VERSION ""

NS_ :

BS_:

BU_: ACM APIM APIM_CDC APIM_CIM APIM_CISM ARM DSP ESPM FCIMB GENERIC GWM HUD_ADV IPC MRCMB_RDAPM_HS3 RACM_RCIM TRM_ITRM TSTR WCM WCMB WCMC

BO_ 1152 HEV_Powertrain_Data6_HS3: 8 GWM
 SG_ StopStrtVThres_D_Stat : 1|2@0+ (1,0) [0|3] "SED"  APIM,APIM_CDC,APIM_CIM,IPC
 SG_ BattTracDiagClr_B_Stat : 2|1@0+ (1,0) [0|1] "SED" Vector__XXX
 SG_ OnePdlDrv_D_Dsply : 4|2@0+ (1,0) [0|3] "SED"  APIM,APIM_CDC,APIM_CIM,APIM_CISM,IPC
 SG_ EngTeHi_B_Actl : 5|1@0+ (1,0) [0|1] "SED" Vector__XXX
 SG_ DcdcOn_B_Rq : 6|1@0+ (1,0) [0|1] "SED" Vector__XXX
 SG_ ULoBattSpprtSustn_B_Rq : 7|1@0+ (1,0) [0|1] "SED" Vector__XXX
 SG_ GrdAsstActv_B_Stat : 8|1@0+ (1,0) [0|1] "SED"  APIM_CDC,APIM_CIM,IPC
 SG_ VehElEff_No_Avg : 15|7@0+ (10,-100) [-100|1170] "watt*hr/km" Vector__XXX
 SG_ PwOutlet8EnblScnd_B_Rq : 16|1@0+ (1,0) [0|1] "SED" Vector__XXX
 SG_ PwOutlet8Enbl_B_Rq : 17|1@0+ (1,0) [0|1] "SED" Vector__XXX
 SG_ PwOutlet7EnblScnd_B_Rq : 18|1@0+ (1,0) [0|1] "SED" Vector__XXX
 SG_ PwOutlet7Enbl_B_Rq : 19|1@0+ (1,0) [0|1] "SED" Vector__XXX
 SG_ PwOutlet6EnblScnd_B_Rq : 20|1@0+ (1,0) [0|1] "SED" Vector__XXX
 SG_ PwOutlet6Enbl_B_Rq : 21|1@0+ (1,0) [0|1] "SED" Vector__XXX
 SG_ HybPwULoLamp_B_Rq : 22|1@0+ (1,0) [0|1] "SED" Vector__XXX
 SG_ OnePdlDrvLamp_B_Rq : 23|1@0+ (1,0) [0|1] "SED"  APIM_CDC,APIM_CIM,IPC
 SG_ DcacPwSustn_B_RqPt : 24|1@0+ (1,0) [0|1] "SED" Vector__XXX
 SG_ OnePdlDrvButtn_D_Dsply : 26|2@0+ (1,0) [0|3] "SED"  APIM,APIM_CDC,APIM_CIM
 SG_ DcdcOnScnd_B_Rq : 27|1@0+ (1,0) [0|1] "SED" Vector__XXX
 SG_ PwCabinEnblScnd_B_Rq : 28|1@0+ (1,0) [0|1] "SED" Vector__XXX
 SG_ PwCabinEnbl_B_Rq : 29|1@0+ (1,0) [0|1] "SED" Vector__XXX
 SG_ PwTrnkFrntEnblScnd_B_Rq : 30|1@0+ (1,0) [0|1] "SED" Vector__XXX
 SG_ PwTrnkFrntEnbl_B_Rq : 31|1@0+ (1,0) [0|1] "SED" Vector__XXX
 SG_ DcacLoFuelLim_L_PwRsrv : 39|9@0+ (1,0) [0|511] "kilometer"  APIM,APIM_CDC,APIM_CIM

BO_ 1153 All_Terrain_Data_HS3: 8 GWM
 SG_ TerrMde_D_RqDrv : 3|3@0+ (1,0) [0|7] "SED"  APIM_CDC,APIM_CIM
 SG_ TerrStat_D_RqDsply : 7|4@0+ (1,0) [0|15] "SED"  APIM_CDC,APIM_CIM,GENERIC

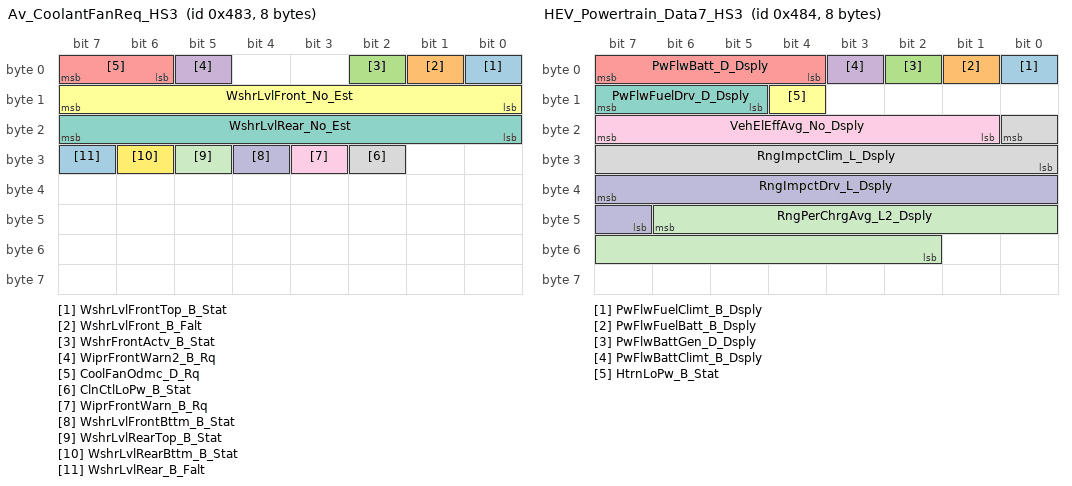
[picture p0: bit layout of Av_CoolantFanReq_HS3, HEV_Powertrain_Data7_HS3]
BO_ 1155 Av_CoolantFanReq_HS3: 8 GWM
 SG_ WshrLvlFrontTop_B_Stat : 0|1@0+ (1,0) [0|1] "SED" Vector__XXX
 SG_ WshrLvlFront_B_Falt : 1|1@0+ (1,0) [0|1] "SED" Vector__XXX
 SG_ WshrFrontActv_B_Stat : 2|1@0+ (1,0) [0|1] "SED"  APIM_CDC
 SG_ WiprFrontWarn2_B_Rq : 5|1@0+ (1,0) [0|1] "SED"  APIM_CDC
 SG_ CoolFanOdmc_D_Rq : 7|2@0+ (1,0) [0|3] "SED" Vector__XXX
 SG_ WshrLvlFront_No_Est : 15|8@0+ (1,0) [0|255] "unitless" Vector__XXX
 SG_ WshrLvlRear_No_Est : 23|8@0+ (1,0) [0|255] "unitless" Vector__XXX
 SG_ ClnCtlLoPw_B_Stat : 26|1@0+ (1,0) [0|1] "SED" Vector__XXX
 SG_ WiprFrontWarn_B_Rq : 27|1@0+ (1,0) [0|1] "SED"  APIM_CDC
 SG_ WshrLvlFrontBttm_B_Stat : 28|1@0+ (1,0) [0|1] "SED" Vector__XXX
 SG_ WshrLvlRearTop_B_Stat : 29|1@0+ (1,0) [0|1] "SED" Vector__XXX
 SG_ WshrLvlRearBttm_B_Stat : 30|1@0+ (1,0) [0|1] "SED" Vector__XXX
 SG_ WshrLvlRear_B_Falt : 31|1@0+ (1,0) [0|1] "SED" Vector__XXX

BO_ 1156 HEV_Powertrain_Data7_HS3: 8 GWM
 SG_ PwFlwFuelClimt_B_Dsply : 0|1@0+ (1,0) [0|1] "SED"  APIM,APIM_CDC,APIM_CIM,APIM_CISM
 SG_ PwFlwFuelBatt_B_Dsply : 1|1@0+ (1,0) [0|1] "SED"  APIM,APIM_CDC,APIM_CIM,APIM_CISM
 SG_ PwFlwBattGen_D_Dsply : 2|1@0+ (1,0) [0|1] "SED"  APIM,APIM_CDC,APIM_CIM,APIM_CISM
 SG_ PwFlwBattClimt_B_Dsply : 3|1@0+ (1,0) [0|1] "SED"  APIM,APIM_CDC,APIM_CIM,APIM_CISM
 SG_ PwFlwBatt_D_Dsply : 7|4@0+ (1,0) [0|15] "SED"  APIM,APIM_CDC,APIM_CIM,APIM_CISM
 SG_ HtrnLoPw_B_Stat : 12|1@0+ (1,0) [0|1] "SED" Vector__XXX
 SG_ PwFlwFuelDrv_D_Dsply : 15|3@0+ (1,0) [0|7] "SED"  APIM,APIM_CDC,APIM_CIM,APIM_CISM
 SG_ RngImpctClim_L_Dsply : 16|9@0+ (1,-255) [-255|256] "km"  APIM_CDC,APIM_CIM,IPC
 SG_ VehElEffAvg_No_Dsply : 23|7@0+ (10,-100) [-100|1170] "wattHr/km"  APIM,APIM_CDC,APIM_CIM,APIM_CISM,IPC
 SG_ RngImpctDrv_L_Dsply : 39|9@0+ (1,-255) [-255|256] "km"  APIM_CDC,APIM_CIM,IPC
 SG_ RngPerChrgAvg_L2_Dsply : 46|13@0+ (0.1,0) [0|819.1] "km"  APIM,APIM_CDC,APIM_CIM,APIM_CISM,IPC

BO_ 1157 BTT5GLH_Data1_HS3: 8 GWM
 SG_ SodAltLeft_D2_StatAft : 7|2@0+ (1,0) [0|3] "SED"  APIM,APIM_CDC,APIM_CIM,APIM_CISM

BO_ 1158 BTT5GRH_Data1_HS3: 8 GWM
 SG_ SodAltRight_D2_StatAft : 7|2@0+ (1,0) [0|3] "SED"  APIM,APIM_CDC,APIM_CIM,APIM_CISM

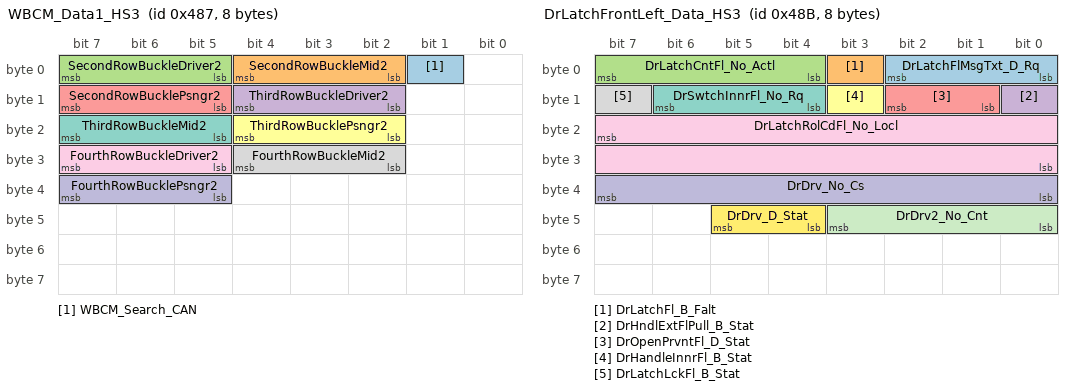
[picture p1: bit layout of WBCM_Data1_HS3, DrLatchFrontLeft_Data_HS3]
BO_ 1159 WBCM_Data1_HS3: 8 GWM
 SG_ WBCM_Search_CAN : 1|1@0+ (1,0) [0|1] "SED" Vector__XXX
 SG_ SecondRowBuckleMid2 : 4|3@0+ (1,0) [0|7] "SED"  APIM_CDC,APIM_CIM,IPC
 SG_ SecondRowBuckleDriver2 : 7|3@0+ (1,0) [0|7] "SED"  APIM_CDC,APIM_CIM,IPC
 SG_ ThirdRowBuckleDriver2 : 12|3@0+ (1,0) [0|7] "SED"  APIM_CDC,APIM_CIM,IPC
 SG_ SecondRowBucklePsngr2 : 15|3@0+ (1,0) [0|7] "SED"  APIM_CDC,APIM_CIM,IPC
 SG_ ThirdRowBucklePsngr2 : 20|3@0+ (1,0) [0|7] "SED"  APIM_CDC,APIM_CIM,IPC
 SG_ ThirdRowBuckleMid2 : 23|3@0+ (1,0) [0|7] "SED"  APIM_CDC,APIM_CIM,IPC
 SG_ FourthRowBuckleMid2 : 28|3@0+ (1,0) [0|7] "SED"  APIM_CDC,APIM_CIM,IPC
 SG_ FourthRowBuckleDriver2 : 31|3@0+ (1,0) [0|7] "SED"  APIM_CDC,APIM_CIM,IPC
 SG_ FourthRowBucklePsngr2 : 39|3@0+ (1,0) [0|7] "SED"  APIM_CDC,APIM_CIM,IPC

BO_ 1161 HEV_Data_Monitor_22_HS3: 8 GWM
 SG_ BattTracCellCnt_No_Actl : 7|8@0+ (1,0) [0|255] "unitless" Vector__XXX
 SG_ BattTracCellUMn_No_Actl : 15|8@0+ (1,0) [0|255] "unitless" Vector__XXX
 SG_ BattTracTeCnt_No_Actl : 23|8@0+ (1,0) [0|255] "unitless" Vector__XXX
 SG_ BattTracTeMn_No_Actl : 31|8@0+ (1,0) [0|255] "unitless" Vector__XXX
 SG_ BattTracTeMx_No_Actl : 39|8@0+ (1,0) [0|255] "unitless" Vector__XXX
 SG_ BattTracTeMx_B_Falt : 40|1@0+ (1,0) [0|1] "SED" Vector__XXX
 SG_ BattTracTeDelta_B_Falt : 41|1@0+ (1,0) [0|1] "SED" Vector__XXX
 SG_ BattTracSoftware_B_Falt : 42|1@0+ (1,0) [0|1] "SED" Vector__XXX
 SG_ BattTracCellDiff_B_Falt : 43|1@0+ (1,0) [0|1] "SED" Vector__XXX
 SG_ BattChrgSocMx_B_Falt : 44|1@0+ (1,0) [0|1] "SED"  APIM,APIM_CDC,APIM_CIM,APIM_CISM
 SG_ BattChrgSocMn_B_Falt : 45|1@0+ (1,0) [0|1] "SED"  APIM,APIM_CDC,APIM_CIM,APIM_CISM
 SG_ BattChrgSocErrtc_B_Falt : 46|1@0+ (1,0) [0|1] "SED" Vector__XXX
 SG_ BattChrgIsltn_B_Falt : 47|1@0+ (1,0) [0|1] "SED" Vector__XXX
 SG_ BattTracUMxArry_No_Actl : 52|5@0+ (1,0) [0|31] "unitless" Vector__XXX
 SG_ BattChrgUMx_B_Falt : 53|1@0+ (1,0) [0|1] "SED" Vector__XXX
 SG_ BattTracUMx_B_Falt : 54|1@0+ (1,0) [0|1] "SED" Vector__XXX
 SG_ BattTracUMn_B_Falt : 55|1@0+ (1,0) [0|1] "SED" Vector__XXX
 SG_ BattTracCellUMx_No_Actl : 63|8@0+ (1,0) [0|255] "unitless" Vector__XXX

BO_ 1163 DrLatchFrontLeft_Data_HS3: 8 GWM
 SG_ DrLatchFlMsgTxt_D_Rq : 2|3@0+ (1,0) [0|7] "SED"  APIM_CDC,APIM_CIM,IPC
 SG_ DrLatchFl_B_Falt : 3|1@0+ (1,0) [0|1] "SED" Vector__XXX
 SG_ DrLatchCntFl_No_Actl : 7|4@0+ (1,0) [0|15] "unitless" Vector__XXX
 SG_ DrHndlExtFlPull_B_Stat : 8|1@0+ (1,0) [0|1] "SED" Vector__XXX
 SG_ DrOpenPrvntFl_D_Stat : 10|2@0+ (1,0) [0|3] "SED" Vector__XXX
 SG_ DrHandleInnrFl_B_Stat : 11|1@0+ (1,0) [0|1] "SED" Vector__XXX
 SG_ DrSwtchInnrFl_No_Rq : 14|3@0+ (1,0) [0|7] "unitless" Vector__XXX
 SG_ DrLatchLckFl_B_Stat : 15|1@0+ (1,0) [0|1] "SED"  APIM,APIM_CDC,APIM_CIM,APIM_CISM
 SG_ DrLatchRolCdFl_No_Locl : 23|16@0+ (1,0) [0|65535] "unitless" Vector__XXX
 SG_ DrDrv_No_Cs : 39|8@0+ (1,0) [0|255] "unitless" Vector__XXX
 SG_ DrDrv2_No_Cnt : 43|4@0+ (1,0) [0|15] "unitless" Vector__XXX
 SG_ DrDrv_D_Stat : 45|2@0+ (1,0) [0|3] "SED" Vector__XXX

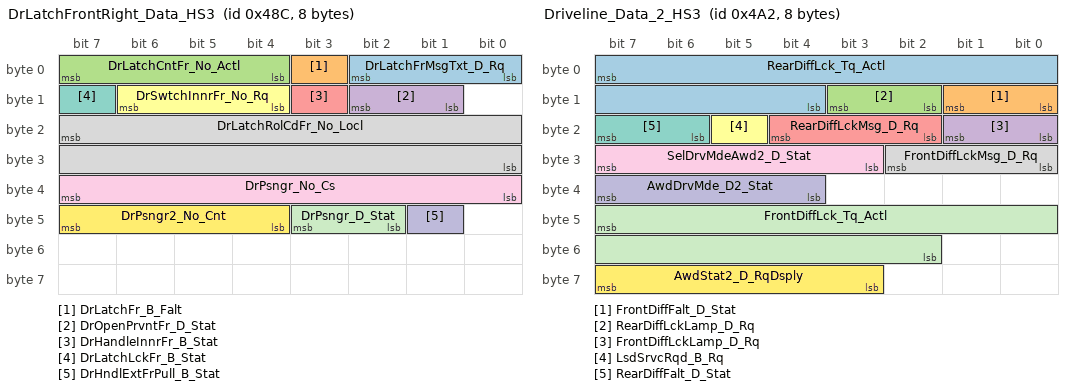
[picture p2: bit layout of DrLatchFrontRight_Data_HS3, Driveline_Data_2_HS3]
BO_ 1164 DrLatchFrontRight_Data_HS3: 8 GWM
 SG_ DrLatchFrMsgTxt_D_Rq : 2|3@0+ (1,0) [0|7] "SED"  APIM_CDC,APIM_CIM,IPC
 SG_ DrLatchFr_B_Falt : 3|1@0+ (1,0) [0|1] "SED" Vector__XXX
 SG_ DrLatchCntFr_No_Actl : 7|4@0+ (1,0) [0|15] "unitless" Vector__XXX
 SG_ DrOpenPrvntFr_D_Stat : 10|2@0+ (1,0) [0|3] "SED" Vector__XXX
 SG_ DrHandleInnrFr_B_Stat : 11|1@0+ (1,0) [0|1] "SED" Vector__XXX
 SG_ DrSwtchInnrFr_No_Rq : 14|3@0+ (1,0) [0|7] "unitless" Vector__XXX
 SG_ DrLatchLckFr_B_Stat : 15|1@0+ (1,0) [0|1] "SED"  APIM,APIM_CDC,APIM_CIM,APIM_CISM
 SG_ DrLatchRolCdFr_No_Locl : 23|16@0+ (1,0) [0|65535] "unitless" Vector__XXX
 SG_ DrPsngr_No_Cs : 39|8@0+ (1,0) [0|255] "unitless" Vector__XXX
 SG_ DrHndlExtFrPull_B_Stat : 41|1@0+ (1,0) [0|1] "SED" Vector__XXX
 SG_ DrPsngr_D_Stat : 43|2@0+ (1,0) [0|3] "SED" Vector__XXX
 SG_ DrPsngr2_No_Cnt : 47|4@0+ (1,0) [0|15] "unitless" Vector__XXX

BO_ 1165 DrLatchRearLeft_Data_HS3: 8 GWM
 SG_ DrLatchRolCdRl_No_Locl : 7|16@0+ (1,0) [0|65535] "unitless"  APIM_CIM

BO_ 1166 DrLatchRearRight_Data_HS3: 8 GWM
 SG_ DrLatchRolCdRr_No_Locl : 7|16@0+ (1,0) [0|65535] "unitless"  APIM_CIM
 SG_ DrHndlExtRrPull_B_Stat : 23|1@0+ (1,0) [0|1] "SED"  APIM_CIM

BO_ 1184 APIM_TCU_Word_Rx_HS3: 8 GWM
 SG_ APIM_TCU_Word_Rx : 7|64@0+ (1,0) [0|1.84467440737096E+019] "unitless"  APIM,APIM_CDC,APIM_CIM,APIM_CISM

BO_ 1185 TCU_MC_WORD_Rx: 8 APIM_CDC
 SG_ TCU_MC_WORD_Rx : 7|64@0+ (1,0) [0|1.84467440737096E+019] "unitless"  GWM

BO_ 1186 Driveline_Data_2_HS3: 8 GWM
 SG_ RearDiffLck_Tq_Actl : 7|12@0+ (1,0) [0|4095] "Nm" Vector__XXX
 SG_ FrontDiffFalt_D_Stat : 9|2@0+ (1,0) [0|3] "SED"  GENERIC
 SG_ RearDiffLckLamp_D_Rq : 11|2@0+ (1,0) [0|3] "SED"  ACM,APIM,APIM_CDC,APIM_CIM,APIM_CISM,HUD_ADV,IPC
 SG_ FrontDiffLckLamp_D_Rq : 17|2@0+ (1,0) [0|3] "SED"  APIM,APIM_CDC,APIM_CIM,APIM_CISM,HUD_ADV,IPC
 SG_ RearDiffLckMsg_D_Rq : 20|3@0+ (1,0) [0|7] "SED"  APIM_CDC,APIM_CIM,IPC
 SG_ LsdSrvcRqd_B_Rq : 21|1@0+ (1,0) [0|1] "SED"  APIM_CDC,APIM_CIM,APIM_CISM,IPC
 SG_ RearDiffFalt_D_Stat : 23|2@0+ (1,0) [0|3] "SED" Vector__XXX
 SG_ FrontDiffLckMsg_D_Rq : 26|3@0+ (1,0) [0|7] "SED"  APIM_CDC,APIM_CIM,IPC
 SG_ SelDrvMdeAwd2_D_Stat : 31|5@0+ (1,0) [0|31] "SED"  GENERIC
 SG_ AwdDrvMde_D2_Stat : 39|4@0+ (1,0) [0|15] "SED"  APIM_CDC,APIM_CIM,IPC
 SG_ FrontDiffLck_Tq_Actl : 47|14@0+ (1,0) [0|16383] "Nm"  GENERIC
 SG_ AwdStat2_D_RqDsply : 63|5@0+ (1,0) [0|31] "SED"  APIM_CDC,APIM_CIM,IPC

BO_ 1187 TCU_RDISP2_WORD_Tx_HS3: 8 GWM
 SG_ TCU_RDISP2_WORD_Tx : 7|64@0+ (1,0) [0|1.84467440737096E+019] "unitless"  HUD_ADV

BO_ 1188 OPTIN_MC_WORD_Rx: 8 APIM_CDC
 SG_ OPTIN_MC_WORD_Rx : 7|64@0+ (1,0) [0|1.84467440737096E+019] "unitless"  GWM

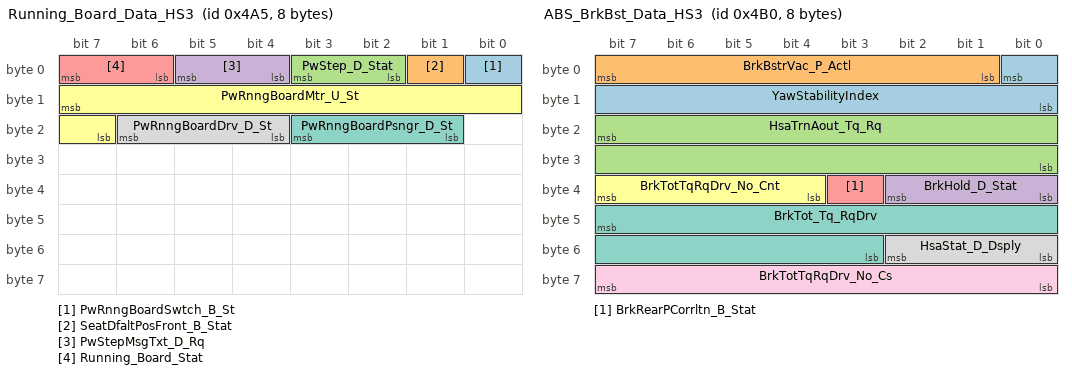
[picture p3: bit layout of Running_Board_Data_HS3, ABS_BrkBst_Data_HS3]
BO_ 1189 Running_Board_Data_HS3: 8 GWM
 SG_ PwRnngBoardSwtch_B_St : 0|1@0+ (1,0) [0|1] "SED" Vector__XXX
 SG_ SeatDfaltPosFront_B_Stat : 1|1@0+ (1,0) [0|1] "SED" Vector__XXX
 SG_ PwStep_D_Stat : 3|2@0+ (1,0) [0|3] "SED" Vector__XXX
 SG_ PwStepMsgTxt_D_Rq : 5|2@0+ (1,0) [0|3] "SED"  APIM_CDC,APIM_CIM,IPC
 SG_ Running_Board_Stat : 7|2@0+ (1,0) [0|3] "SED"  APIM,APIM_CDC,APIM_CIM,APIM_CISM,IPC
 SG_ PwRnngBoardMtr_U_St : 15|9@0+ (0.05,0) [0|25.55] "volt" Vector__XXX
 SG_ PwRnngBoardPsngr_D_St : 19|3@0+ (1,0) [0|7] "SED" Vector__XXX
 SG_ PwRnngBoardDrv_D_St : 22|3@0+ (1,0) [0|7] "SED" Vector__XXX

BO_ 1192 APIM_TCU_Word_Tx: 8 APIM_CDC
 SG_ APIM_TCU_Word_Tx : 7|64@0+ (1,0) [0|1.84467440737096E+019] "unitless"  GWM

BO_ 1195 TCU_RDISP2_WORD_Rx: 8 HUD_ADV
 SG_ TCU_RDISP2_WORD_Rx : 7|64@0+ (1,0) [0|1.84467440737096E+019] "unitless"  GWM

BO_ 1200 ABS_BrkBst_Data_HS3: 8 GWM
 SG_ YawStabilityIndex : 0|9@0+ (1,-256) [-256|255] "%" Vector__XXX
 SG_ BrkBstrVac_P_Actl : 7|7@0+ (8,0) [0|1016] "millibar" Vector__XXX
 SG_ HsaTrnAout_Tq_Rq : 23|16@0+ (4,-131072) [-131072|131068] "Nm" Vector__XXX
 SG_ BrkHold_D_Stat : 34|3@0+ (1,0) [0|7] "SED" Vector__XXX
 SG_ BrkRearPCorrltn_B_Stat : 35|1@0+ (1,0) [0|1] "SED" Vector__XXX
 SG_ BrkTotTqRqDrv_No_Cnt : 39|4@0+ (1,0) [0|15] "unitless" Vector__XXX
 SG_ BrkTot_Tq_RqDrv : 47|13@0+ (4,0) [0|32764] "Nm"  APIM,APIM_CIM,APIM_CISM
 SG_ HsaStat_D_Dsply : 50|3@0+ (1,0) [0|7] "SED" Vector__XXX
 SG_ BrkTotTqRqDrv_No_Cs : 63|8@0+ (1,0) [0|255] "unitless" Vector__XXX

BO_ 1202 SDARS_VR_WORD_Rx: 8 APIM_CDC
 SG_ SDARS_VR_WORD_Rx : 7|64@0+ (1,0) [0|1.84467440737096E+019] "unitless"  ACM

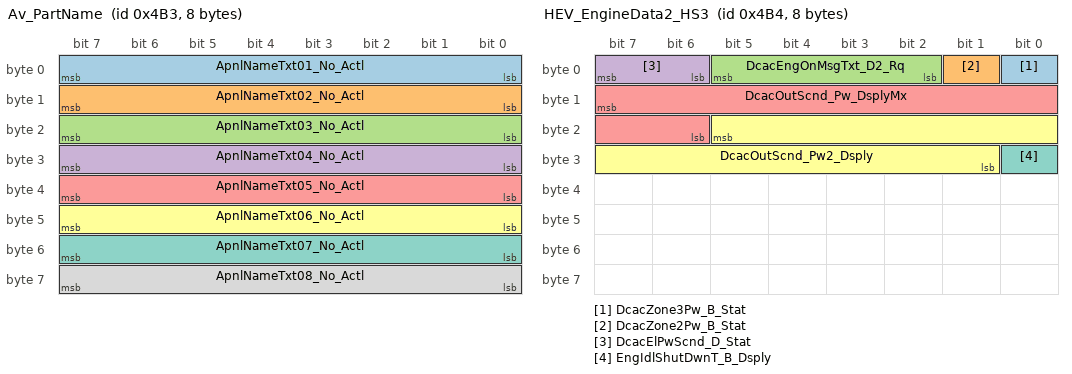
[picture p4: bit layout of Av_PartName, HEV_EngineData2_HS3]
BO_ 1203 Av_PartName: 8 GWM
 SG_ ApnlNameTxt01_No_Actl : 7|8@0+ (1,0) [0|255] "unitless"  MRCMB_RDAPM_HS3
 SG_ ApnlNameTxt02_No_Actl : 15|8@0+ (1,0) [0|255] "unitless"  MRCMB_RDAPM_HS3
 SG_ ApnlNameTxt03_No_Actl : 23|8@0+ (1,0) [0|255] "unitless"  MRCMB_RDAPM_HS3
 SG_ ApnlNameTxt04_No_Actl : 31|8@0+ (1,0) [0|255] "unitless"  MRCMB_RDAPM_HS3
 SG_ ApnlNameTxt05_No_Actl : 39|8@0+ (1,0) [0|255] "unitless"  MRCMB_RDAPM_HS3
 SG_ ApnlNameTxt06_No_Actl : 47|8@0+ (1,0) [0|255] "unitless"  MRCMB_RDAPM_HS3
 SG_ ApnlNameTxt07_No_Actl : 55|8@0+ (1,0) [0|255] "unitless"  MRCMB_RDAPM_HS3
 SG_ ApnlNameTxt08_No_Actl : 63|8@0+ (1,0) [0|255] "unitless"  MRCMB_RDAPM_HS3

BO_ 1204 HEV_EngineData2_HS3: 8 GWM
 SG_ DcacZone3Pw_B_Stat : 0|1@0+ (1,0) [0|1] "SED"  APIM,APIM_CDC,APIM_CIM
 SG_ DcacZone2Pw_B_Stat : 1|1@0+ (1,0) [0|1] "SED"  APIM,APIM_CDC,APIM_CIM
 SG_ DcacEngOnMsgTxt_D2_Rq : 5|4@0+ (1,0) [0|15] "SED"  APIM,APIM_CDC,APIM_CIM
 SG_ DcacElPwScnd_D_Stat : 7|2@0+ (1,0) [0|3] "SED"  APIM,APIM_CDC,APIM_CIM
 SG_ DcacOutScnd_Pw_DsplyMx : 15|10@0+ (10,0) [0|10230] "watts"  APIM,APIM_CDC,APIM_CIM
 SG_ DcacOutScnd_Pw2_Dsply : 21|13@0+ (1,0) [0|8191] "watts"  APIM,APIM_CDC,APIM_CIM
 SG_ EngIdlShutDwnT_B_Dsply : 24|1@0+ (1,0) [0|1] "SED"  APIM,APIM_CDC,APIM_CIM

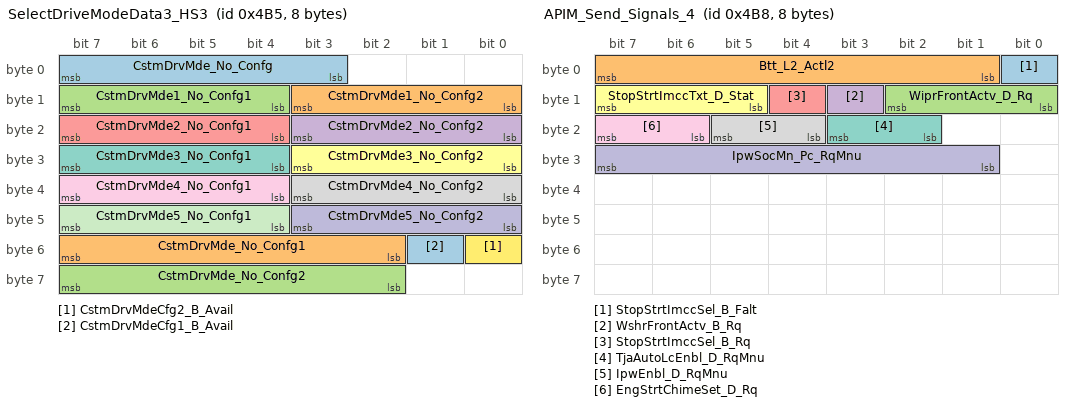
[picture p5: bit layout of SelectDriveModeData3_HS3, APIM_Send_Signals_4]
BO_ 1205 SelectDriveModeData3_HS3: 8 GWM
 SG_ CstmDrvMde_No_Confg : 7|5@0+ (1,0) [0|31] "unitless"  APIM_CDC,APIM_CIM,IPC
 SG_ CstmDrvMde1_No_Confg2 : 11|4@0+ (1,0) [0|15] "unitless"  APIM_CDC,APIM_CIM,IPC
 SG_ CstmDrvMde1_No_Confg1 : 15|4@0+ (1,0) [0|15] "unitless"  APIM_CDC,APIM_CIM,IPC
 SG_ CstmDrvMde2_No_Confg2 : 19|4@0+ (1,0) [0|15] "unitless"  APIM_CDC,APIM_CIM,IPC
 SG_ CstmDrvMde2_No_Confg1 : 23|4@0+ (1,0) [0|15] "unitless"  APIM_CDC,APIM_CIM,IPC
 SG_ CstmDrvMde3_No_Confg2 : 27|4@0+ (1,0) [0|15] "unitless"  APIM_CDC,APIM_CIM,IPC
 SG_ CstmDrvMde3_No_Confg1 : 31|4@0+ (1,0) [0|15] "unitless"  APIM_CDC,APIM_CIM,IPC
 SG_ CstmDrvMde4_No_Confg2 : 35|4@0+ (1,0) [0|15] "unitless"  APIM_CDC,APIM_CIM,IPC
 SG_ CstmDrvMde4_No_Confg1 : 39|4@0+ (1,0) [0|15] "unitless"  APIM_CDC,APIM_CIM,IPC
 SG_ CstmDrvMde5_No_Confg2 : 43|4@0+ (1,0) [0|15] "unitless"  APIM_CDC,APIM_CIM,IPC
 SG_ CstmDrvMde5_No_Confg1 : 47|4@0+ (1,0) [0|15] "unitless"  APIM_CDC,APIM_CIM,IPC
 SG_ CstmDrvMdeCfg2_B_Avail : 48|1@0+ (1,0) [0|1] "SED"  APIM_CDC,APIM_CIM,IPC
 SG_ CstmDrvMdeCfg1_B_Avail : 49|1@0+ (1,0) [0|1] "SED"  APIM_CDC,APIM_CIM,IPC
 SG_ CstmDrvMde_No_Confg1 : 55|6@0+ (1,0) [0|63] "unitless"  APIM_CDC,APIM_CIM,IPC
 SG_ CstmDrvMde_No_Confg2 : 63|6@0+ (1,0) [0|63] "unitless"  APIM_CDC,APIM_CIM,IPC

BO_ 1208 APIM_Send_Signals_4: 8 APIM_CDC
 SG_ StopStrtImccSel_B_Falt : 0|1@0+ (1,0) [0|1] "SED"  GWM
 SG_ Btt_L2_Actl2 : 7|7@0+ (0.1,5.1) [5.1|17.8] "meter"  GWM
 SG_ WiprFrontActv_D_Rq : 10|3@0+ (1,0) [0|7] "SED"  GWM
 SG_ WshrFrontActv_B_Rq : 11|1@0+ (1,0) [0|1] "SED"  GWM
 SG_ StopStrtImccSel_B_Rq : 12|1@0+ (1,0) [0|1] "SED"  GWM
 SG_ StopStrtImccTxt_D_Stat : 15|3@0+ (1,0) [0|7] "SED"  GWM
 SG_ TjaAutoLcEnbl_D_RqMnu : 19|2@0+ (1,0) [0|3] "SED"  GWM
 SG_ IpwEnbl_D_RqMnu : 21|2@0+ (1,0) [0|3] "SED"  GWM
 SG_ EngStrtChimeSet_D_Rq : 23|2@0+ (1,0) [0|3] "SED"  GWM
 SG_ IpwSocMn_Pc_RqMnu : 31|7@0+ (1,0) [0|127] "percent"  GWM

BO_ 1210 SDARS_VR_WORD_Tx: 8 ACM
 SG_ SDARS_VR_WORD_Tx : 7|64@0+ (1,0) [0|1.84467440737096E+019] "unitless"  APIM,APIM_CDC

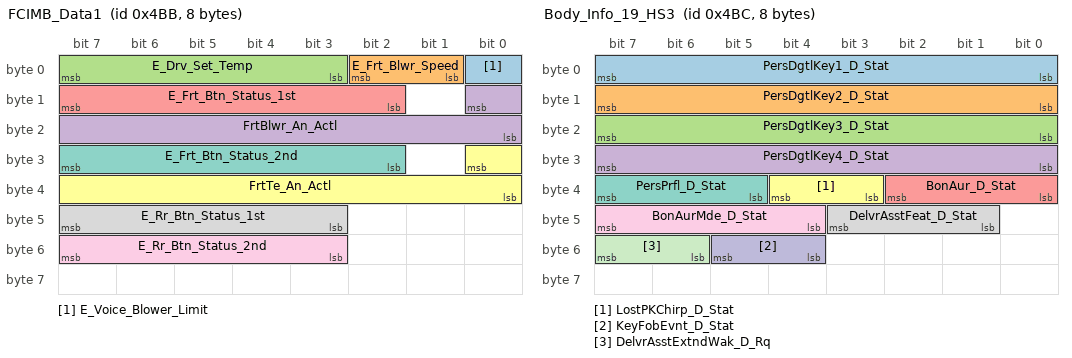
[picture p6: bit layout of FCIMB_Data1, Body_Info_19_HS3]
BO_ 1211 FCIMB_Data1: 8 FCIMB
 SG_ E_Voice_Blower_Limit : 0|1@0+ (1,0) [0|1] "SED"  GWM
 SG_ E_Frt_Blwr_Speed : 2|2@0+ (1,0) [0|3] "SED"  GWM
 SG_ E_Drv_Set_Temp : 7|5@0+ (1,0) [0|31] "SED"  GWM
 SG_ FrtBlwr_An_Actl : 8|9@0+ (1,0) [0|511] "degrees"  GWM
 SG_ E_Frt_Btn_Status_1st : 15|6@0+ (1,0) [0|63] "SED"  GWM
 SG_ FrtTe_An_Actl : 24|9@0+ (1,0) [0|511] "degrees"  GWM
 SG_ E_Frt_Btn_Status_2nd : 31|6@0+ (1,0) [0|63] "SED"  GWM
 SG_ E_Rr_Btn_Status_1st : 47|5@0+ (1,0) [0|31] "SED"  GWM
 SG_ E_Rr_Btn_Status_2nd : 55|5@0+ (1,0) [0|31] "SED"  GWM

BO_ 1212 Body_Info_19_HS3: 8 GWM
 SG_ PersDgtlKey1_D_Stat : 7|8@0+ (1,0) [0|255] "SED"  APIM,APIM_CDC,APIM_CIM
 SG_ PersDgtlKey2_D_Stat : 15|8@0+ (1,0) [0|255] "SED"  APIM,APIM_CDC,APIM_CIM
 SG_ PersDgtlKey3_D_Stat : 23|8@0+ (1,0) [0|255] "SED"  APIM,APIM_CDC,APIM_CIM
 SG_ PersDgtlKey4_D_Stat : 31|8@0+ (1,0) [0|255] "SED"  APIM,APIM_CDC,APIM_CIM
 SG_ BonAur_D_Stat : 34|3@0+ (1,0) [0|7] "SED"  APIM_CDC,APIM_CIM,RACM_RCIM
 SG_ LostPKChirp_D_Stat : 36|2@0+ (1,0) [0|3] "SED"  APIM,APIM_CDC,APIM_CIM,APIM_CISM
 SG_ PersPrfl_D_Stat : 39|3@0+ (1,0) [0|7] "SED"  APIM,APIM_CDC,APIM_CIM
 SG_ DelvrAsstFeat_D_Stat : 43|3@0+ (1,0) [0|7] "SED"  APIM,APIM_CDC,IPC
 SG_ BonAurMde_D_Stat : 47|4@0+ (1,0) [0|15] "SED"  APIM_CDC,APIM_CIM,RACM_RCIM
 SG_ KeyFobEvnt_D_Stat : 53|2@0+ (1,0) [0|3] "SED"  APIM,APIM_CDC
 SG_ DelvrAsstExtndWak_D_Rq : 55|2@0+ (1,0) [0|3] "SED"  APIM,APIM_CDC

BO_ 1216 LeftPwrSlidDrStat_HS3: 8 GWM
 SG_ SldrlUnlck_No_Cnt : 3|4@0+ (1,0) [0|15] "unitless" Vector__XXX
 SG_ SldrlChildLck_No_Cnt : 7|4@0+ (1,0) [0|15] "unitless" Vector__XXX
 SG_ SldrlUnlckRollCd_No_Cnt : 15|16@0+ (1,0) [0|65535] "unitless" Vector__XXX
 SG_ DrHandleInnrRl_B_Stat : 24|1@0+ (1,0) [0|1] "SED" Vector__XXX
 SG_ SldrlStat_B_Actl : 25|1@0+ (1,0) [0|1] "SED"  APIM_CDC,APIM_CIM,IPC
 SG_ SldrlUnlckSwtch_D_Stat : 27|2@0+ (1,0) [0|3] "SED" Vector__XXX
 SG_ Sldrl_D_Stat : 29|2@0+ (1,0) [0|3] "SED" Vector__XXX
 SG_ PwStepLeft_D_Rq : 31|2@0+ (1,0) [0|3] "SED" Vector__XXX
 SG_ UnlckSrcRl_D_Stat : 33|2@0+ (1,0) [0|3] "SED" Vector__XXX
 SG_ SldrlMsgTxt_D2_Rq : 36|3@0+ (1,0) [0|7] "SED"  APIM_CDC,APIM_CIM,IPC
 SG_ SldrlChime_D_Rq : 39|3@0+ (1,0) [0|7] "SED"  APIM_CDC,APIM_CIM,IPC
 SG_ DrLatchLckRl_B_Stat : 40|1@0+ (1,0) [0|1] "SED"  APIM,APIM_CDC,APIM_CIM,APIM_CISM
 SG_ DrLatchCntRl_No_Actl : 44|4@0+ (1,0) [0|15] "unitless" Vector__XXX
 SG_ DrSwtchExtRl_No_Rq : 47|3@0+ (1,0) [0|7] "unitless" Vector__XXX
 SG_ DrLatchRlMsgTxt_D_Rq : 50|3@0+ (1,0) [0|7] "SED"  APIM_CDC,APIM_CIM,IPC
 SG_ DrOpenPrvntRl_D_Stat : 52|2@0+ (1,0) [0|3] "SED" Vector__XXX
 SG_ DrSwtchInnrRl_No_Rq : 55|3@0+ (1,0) [0|7] "unitless" Vector__XXX
 SG_ DrHndlExtRlPull_B_Stat : 62|1@0+ (1,0) [0|1] "SED" Vector__XXX
 SG_ DrLatchRl_B_Falt : 63|1@0+ (1,0) [0|1] "SED" Vector__XXX

BO_ 1217 RightPwrSlidDrStat_HS3: 8 GWM
 SG_ SldrrUnlck_No_Cnt : 3|4@0+ (1,0) [0|15] "unitless" Vector__XXX
 SG_ SldrrChildLck_No_Cnt : 7|4@0+ (1,0) [0|15] "unitless" Vector__XXX
 SG_ SldrrUnlckRollCd_No_Cnt : 15|16@0+ (1,0) [0|65535] "unitless" Vector__XXX
 SG_ DrHandleInnrRr_B_Stat : 24|1@0+ (1,0) [0|1] "SED" Vector__XXX
 SG_ SldrrStat_B_Actl : 25|1@0+ (1,0) [0|1] "SED"  APIM_CDC,APIM_CIM,IPC
 SG_ SldrrUnlckSwtch_D_Stat : 27|2@0+ (1,0) [0|3] "SED" Vector__XXX
 SG_ Sldrr_D_Stat : 29|2@0+ (1,0) [0|3] "SED" Vector__XXX
 SG_ PwStepRight_D_Rq : 31|2@0+ (1,0) [0|3] "SED" Vector__XXX
 SG_ UnlckSrcRr_D_Stat : 33|2@0+ (1,0) [0|3] "SED" Vector__XXX
 SG_ SldrrMsgTxt_D2_Rq : 36|3@0+ (1,0) [0|7] "SED"  APIM_CDC,APIM_CIM,IPC
 SG_ SldrrChime_D_Rq : 39|3@0+ (1,0) [0|7] "SED"  APIM_CDC,APIM_CIM,IPC
 SG_ DrLatchLckRr_B_Stat : 40|1@0+ (1,0) [0|1] "SED"  APIM,APIM_CDC,APIM_CIM,APIM_CISM
 SG_ DrLatchCntRr_No_Actl : 44|4@0+ (1,0) [0|15] "unitless" Vector__XXX
 SG_ DrSwtchExtRr_No_Rq : 47|3@0+ (1,0) [0|7] "unitless" Vector__XXX
 SG_ DrOpenPrvntRr_D_Stat : 49|2@0+ (1,0) [0|3] "SED" Vector__XXX
 SG_ DrLatchRrMsgTxt_D_Rq : 52|3@0+ (1,0) [0|7] "SED"  APIM_CDC,APIM_CIM,IPC
 SG_ DrSwtchInnrRr_No_Rq : 55|3@0+ (1,0) [0|7] "unitless" Vector__XXX
 SG_ DrLatchRr_B_Falt : 63|1@0+ (1,0) [0|1] "SED" Vector__XXX

BO_ 1218 Body_Info_5_HS3: 8 GWM
 SG_ BecSwtchExtLck_D_Stat : 1|2@0+ (1,0) [0|3] "SED"  APIM_CDC
 SG_ BecSwtch2ExtLck_D_Stat : 3|2@0+ (1,0) [0|3] "SED"  APIM_CDC
 SG_ DrPsngrRearLck_D_Stat : 5|2@0+ (1,0) [0|3] "SED"  APIM_CDC
 SG_ DrDrvRearLck_D_Stat : 7|2@0+ (1,0) [0|3] "SED"  APIM_CDC
 SG_ LckUnlckSrvc_D_Arb : 9|2@0+ (1,0) [0|3] "SED" Vector__XXX
 SG_ FecSwtchExtLck_D_Stat : 11|2@0+ (1,0) [0|3] "SED"  APIM_CDC
 SG_ DrPsngrLck_D_Stat : 13|2@0+ (1,0) [0|3] "SED"  APIM_CDC
 SG_ DrDrvLck_D_Stat : 15|2@0+ (1,0) [0|3] "SED"  APIM_CDC
 SG_ ClsrOprtSrvc_D_Arb : 17|2@0+ (1,0) [0|3] "SED" Vector__XXX
 SG_ DrStopTglRl_No_Actl : 20|3@0+ (1,0) [0|7] "unitless" Vector__XXX
 SG_ DrStopTglRr_No_Actl : 23|3@0+ (1,0) [0|7] "unitless" Vector__XXX
 SG_ ClsrOprtSrvc_D_Res : 27|4@0+ (1,0) [0|15] "SED" Vector__XXX
 SG_ LckUnlckSrvc_D_Res : 31|4@0+ (1,0) [0|15] "SED" Vector__XXX
 SG_ LatchFdbck_B_Stat : 33|1@0+ (1,0) [0|1] "SED" Vector__XXX
 SG_ ClsrOprtSrvcId_No_Actl : 36|3@0+ (1,0) [0|7] "unitless" Vector__XXX
 SG_ LckUnlckSrvcId_No_Actl : 39|3@0+ (1,0) [0|7] "unitless" Vector__XXX
 SG_ PsngrAutoPwWndw_D_Rq : 41|2@0+ (1,0) [0|3] "SED" Vector__XXX
 SG_ AwlSwtch_D_Stat : 44|3@0+ (1,0) [0|7] "unitless" Vector__XXX
 SG_ OprtSrc_D_Stat : 47|3@0+ (1,0) [0|7] "SED" Vector__XXX
 SG_ BodyPersFeatCnt_No_Act : 53|5@0+ (1,0) [0|31] "unitless" Vector__XXX
 SG_ DrvAutoPwWndw_D_Rq : 55|2@0+ (1,0) [0|3] "SED" Vector__XXX
 SG_ VehLck_D_Dsply : 57|2@0+ (1,0) [0|3] "SED" Vector__XXX
 SG_ BodyPersSrvc_D_Res : 61|4@0+ (1,0) [0|15] "SED" Vector__XXX
 SG_ BodyPersChng_D_Stat : 63|2@0+ (1,0) [0|3] "SED" Vector__XXX

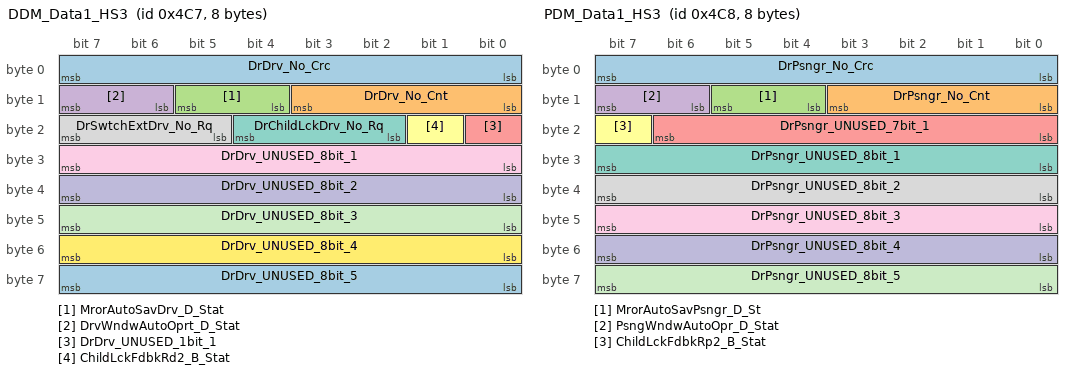
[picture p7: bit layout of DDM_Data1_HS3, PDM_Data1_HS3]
BO_ 1223 DDM_Data1_HS3: 8 GWM
 SG_ DrDrv_No_Crc : 7|8@0+ (1,0) [0|255] "unitless" Vector__XXX
 SG_ DrDrv_No_Cnt : 11|4@0+ (1,0) [0|15] "unitless" Vector__XXX
 SG_ MrorAutoSavDrv_D_Stat : 13|2@0+ (1,0) [0|3] "SED"  APIM_CDC,APIM_CIM
 SG_ DrvWndwAutoOprt_D_Stat : 15|2@0+ (1,0) [0|3] "SED" Vector__XXX
 SG_ DrDrv_UNUSED_1bit_1 : 16|1@0+ (1,0) [0|1] "unitless" Vector__XXX
 SG_ ChildLckFdbkRd2_B_Stat : 17|1@0+ (1,0) [0|1] "SED" Vector__XXX
 SG_ DrChildLckDrv_No_Rq : 20|3@0+ (1,0) [0|7] "unitless" Vector__XXX
 SG_ DrSwtchExtDrv_No_Rq : 23|3@0+ (1,0) [0|7] "unitless" Vector__XXX
 SG_ DrDrv_UNUSED_8bit_1 : 31|8@0+ (1,0) [0|255] "unitless" Vector__XXX
 SG_ DrDrv_UNUSED_8bit_2 : 39|8@0+ (1,0) [0|255] "unitless" Vector__XXX
 SG_ DrDrv_UNUSED_8bit_3 : 47|8@0+ (1,0) [0|255] "unitless" Vector__XXX
 SG_ DrDrv_UNUSED_8bit_4 : 55|8@0+ (1,0) [0|255] "unitless" Vector__XXX
 SG_ DrDrv_UNUSED_8bit_5 : 63|8@0+ (1,0) [0|255] "unitless" Vector__XXX

BO_ 1224 PDM_Data1_HS3: 8 GWM
 SG_ DrPsngr_No_Crc : 7|8@0+ (1,0) [0|255] "unitless" Vector__XXX
 SG_ DrPsngr_No_Cnt : 11|4@0+ (1,0) [0|15] "unitless" Vector__XXX
 SG_ MrorAutoSavPsngr_D_St : 13|2@0+ (1,0) [0|3] "SED"  APIM_CDC,APIM_CIM
 SG_ PsngWndwAutoOpr_D_Stat : 15|2@0+ (1,0) [0|3] "SED" Vector__XXX
 SG_ DrPsngr_UNUSED_7bit_1 : 22|7@0+ (1,0) [0|127] "unitless" Vector__XXX
 SG_ ChildLckFdbkRp2_B_Stat : 23|1@0+ (1,0) [0|1] "SED" Vector__XXX
 SG_ DrPsngr_UNUSED_8bit_1 : 31|8@0+ (1,0) [0|255] "unitless" Vector__XXX
 SG_ DrPsngr_UNUSED_8bit_2 : 39|8@0+ (1,0) [0|255] "unitless" Vector__XXX
 SG_ DrPsngr_UNUSED_8bit_3 : 47|8@0+ (1,0) [0|255] "unitless" Vector__XXX
 SG_ DrPsngr_UNUSED_8bit_4 : 55|8@0+ (1,0) [0|255] "unitless" Vector__XXX
 SG_ DrPsngr_UNUSED_8bit_5 : 63|8@0+ (1,0) [0|255] "unitless" Vector__XXX

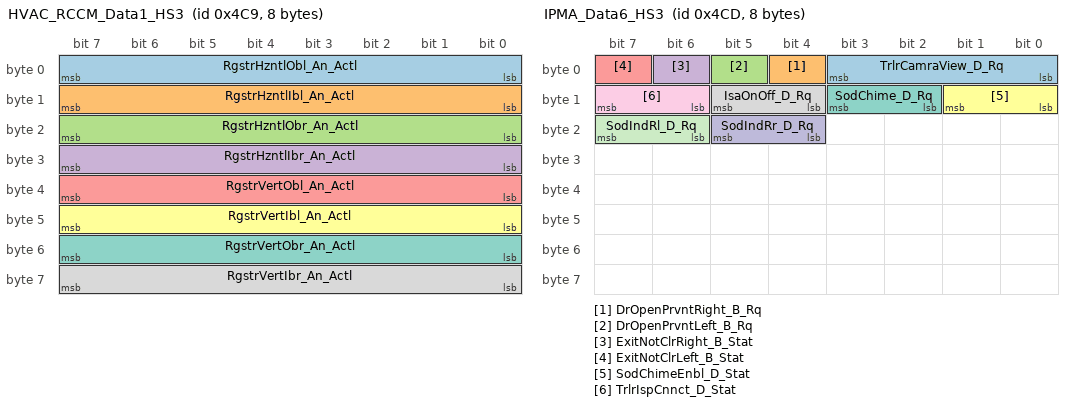
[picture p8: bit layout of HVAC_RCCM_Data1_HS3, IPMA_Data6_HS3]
BO_ 1225 HVAC_RCCM_Data1_HS3: 8 GWM
 SG_ RgstrHzntlObl_An_Actl : 7|8@0+ (1,0) [0|255] "degree"  APIM,APIM_CDC,APIM_CIM,APIM_CISM
 SG_ RgstrHzntlIbl_An_Actl : 15|8@0+ (1,0) [0|255] "degree"  APIM,APIM_CDC,APIM_CIM,APIM_CISM
 SG_ RgstrHzntlObr_An_Actl : 23|8@0+ (1,0) [0|255] "degree"  APIM,APIM_CDC,APIM_CIM,APIM_CISM
 SG_ RgstrHzntlIbr_An_Actl : 31|8@0+ (1,0) [0|255] "degree"  APIM,APIM_CDC,APIM_CIM,APIM_CISM
 SG_ RgstrVertObl_An_Actl : 39|8@0+ (1,0) [0|255] "degree"  APIM,APIM_CDC,APIM_CIM,APIM_CISM
 SG_ RgstrVertIbl_An_Actl : 47|8@0+ (1,0) [0|255] "degree"  APIM,APIM_CDC,APIM_CIM,APIM_CISM
 SG_ RgstrVertObr_An_Actl : 55|8@0+ (1,0) [0|255] "degree"  APIM,APIM_CDC,APIM_CIM,APIM_CISM
 SG_ RgstrVertIbr_An_Actl : 63|8@0+ (1,0) [0|255] "degree"  APIM,APIM_CDC,APIM_CIM,APIM_CISM

BO_ 1229 IPMA_Data6_HS3: 8 GWM
 SG_ TrlrCamraView_D_Rq : 3|4@0+ (1,0) [0|15] "SED" Vector__XXX
 SG_ DrOpenPrvntRight_B_Rq : 4|1@0+ (1,0) [0|1] "SED" Vector__XXX
 SG_ DrOpenPrvntLeft_B_Rq : 5|1@0+ (1,0) [0|1] "SED" Vector__XXX
 SG_ ExitNotClrRight_B_Stat : 6|1@0+ (1,0) [0|1] "SED" Vector__XXX
 SG_ ExitNotClrLeft_B_Stat : 7|1@0+ (1,0) [0|1] "SED" Vector__XXX
 SG_ SodChimeEnbl_D_Stat : 9|2@0+ (1,0) [0|3] "SED"  APIM,APIM_CDC,APIM_CIM
 SG_ SodChime_D_Rq : 11|2@0+ (1,0) [0|3] "SED"  APIM,APIM_CDC,APIM_CIM,IPC
 SG_ IsaOnOff_D_Rq : 13|2@0+ (1,0) [0|3] "SED" Vector__XXX
 SG_ TrlrIspCnnct_D_Stat : 15|2@0+ (1,0) [0|3] "SED"  APIM,APIM_CDC,APIM_CIM,APIM_CISM
 SG_ SodIndRr_D_Rq : 21|2@0+ (1,0) [0|3] "SED"  APIM,APIM_CDC,APIM_CIM,IPC
 SG_ SodIndRl_D_Rq : 23|2@0+ (1,0) [0|3] "SED"  APIM,APIM_CDC,APIM_CIM,IPC

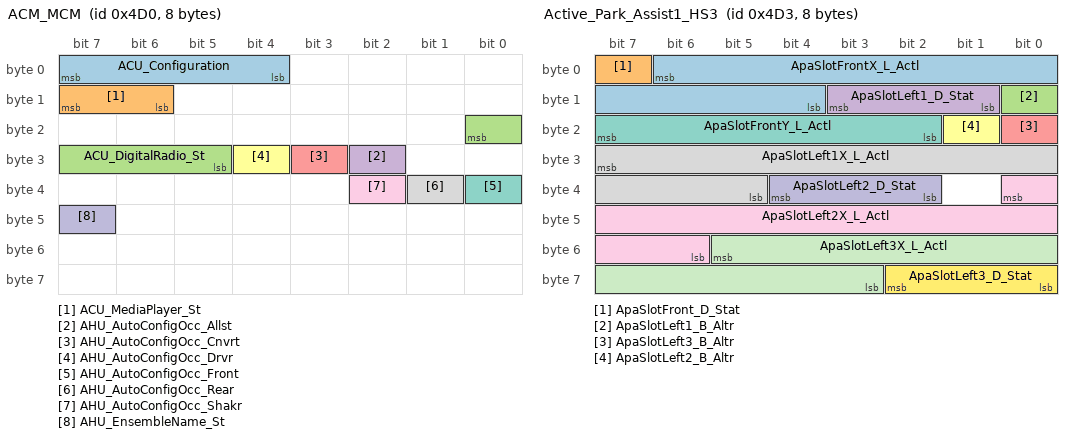
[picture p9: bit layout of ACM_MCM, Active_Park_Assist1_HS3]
BO_ 1232 ACM_MCM: 8 APIM_CIM
 SG_ ACU_Configuration : 7|4@0+ (1,0) [0|15] "SED"  APIM,APIM_CDC,GWM,IPC
 SG_ ACU_MediaPlayer_St : 15|2@0+ (1,0) [0|3] "SED"  APIM,APIM_CDC,GWM,IPC
 SG_ ACU_DigitalRadio_St : 16|4@0+ (1,0) [0|15] "SED"  APIM,APIM_CDC,GWM,IPC
 SG_ AHU_AutoConfigOcc_Allst : 26|1@0+ (1,0) [0|1] "SED"  APIM,APIM_CDC,GWM
 SG_ AHU_AutoConfigOcc_Cnvrt : 27|1@0+ (1,0) [0|1] "SED"  APIM,APIM_CDC,GWM
 SG_ AHU_AutoConfigOcc_Drvr : 28|1@0+ (1,0) [0|1] "SED"  APIM,APIM_CDC,GWM
 SG_ AHU_AutoConfigOcc_Front : 32|1@0+ (1,0) [0|1] "SED"  APIM,APIM_CDC,GWM
 SG_ AHU_AutoConfigOcc_Rear : 33|1@0+ (1,0) [0|1] "SED"  APIM,APIM_CDC,GWM
 SG_ AHU_AutoConfigOcc_Shakr : 34|1@0+ (1,0) [0|1] "SED"  APIM,APIM_CDC,GWM
 SG_ AHU_EnsembleName_St : 47|1@0+ (1,0) [0|1] "SED"  APIM,APIM_CDC

BO_ 1235 Active_Park_Assist1_HS3: 8 GWM
 SG_ ApaSlotFrontX_L_Actl : 6|11@0+ (0.02,-20.96) [-20.96|19.98] "meter"  APIM,APIM_CDC,APIM_CIM,APIM_CISM
 SG_ ApaSlotFront_D_Stat : 7|1@0+ (1,0) [0|1] "SED"  APIM,APIM_CDC,APIM_CIM,APIM_CISM
 SG_ ApaSlotLeft1_B_Altr : 8|1@0+ (1,0) [0|1] "SED"  APIM,APIM_CDC,APIM_CIM,APIM_CISM
 SG_ ApaSlotLeft1_D_Stat : 11|3@0+ (1,0) [0|7] "SED"  APIM,APIM_CDC,APIM_CIM,APIM_CISM
 SG_ ApaSlotLeft3_B_Altr : 16|1@0+ (1,0) [0|1] "SED"  APIM,APIM_CDC,APIM_CIM,APIM_CISM
 SG_ ApaSlotLeft2_B_Altr : 17|1@0+ (1,0) [0|1] "SED"  APIM,APIM_CDC,APIM_CIM,APIM_CISM
 SG_ ApaSlotFrontY_L_Actl : 23|6@0+ (0.2,-6.4) [-6.4|6.2] "meter"  APIM,APIM_CDC,APIM_CIM,APIM_CISM
 SG_ ApaSlotLeft1X_L_Actl : 31|11@0+ (0.02,-20.96) [-20.96|19.98] "meter"  APIM,APIM_CDC,APIM_CIM,APIM_CISM
 SG_ ApaSlotLeft2X_L_Actl : 32|11@0+ (0.02,-20.96) [-20.96|19.98] "meter"  APIM,APIM_CDC,APIM_CIM,APIM_CISM
 SG_ ApaSlotLeft2_D_Stat : 36|3@0+ (1,0) [0|7] "SED"  APIM,APIM_CDC,APIM_CIM,APIM_CISM
 SG_ ApaSlotLeft3X_L_Actl : 53|11@0+ (0.02,-20.96) [-20.96|19.98] "meter"  APIM,APIM_CDC,APIM_CIM,APIM_CISM
 SG_ ApaSlotLeft3_D_Stat : 58|3@0+ (1,0) [0|7] "SED"  APIM,APIM_CDC,APIM_CIM,APIM_CISM

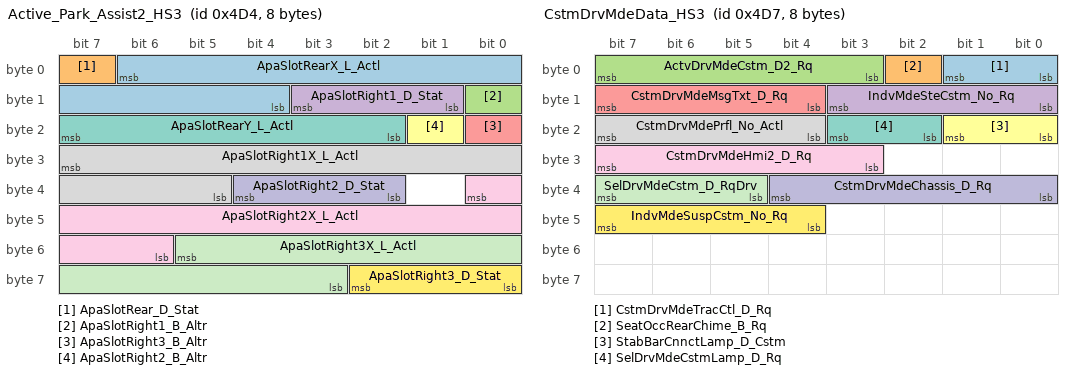
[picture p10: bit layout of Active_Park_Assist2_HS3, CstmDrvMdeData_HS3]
BO_ 1236 Active_Park_Assist2_HS3: 8 GWM
 SG_ ApaSlotRearX_L_Actl : 6|11@0+ (0.02,-20.96) [-20.96|19.98] "meter"  APIM,APIM_CDC,APIM_CIM,APIM_CISM
 SG_ ApaSlotRear_D_Stat : 7|1@0+ (1,0) [0|1] "SED"  APIM,APIM_CDC,APIM_CIM,APIM_CISM
 SG_ ApaSlotRight1_B_Altr : 8|1@0+ (1,0) [0|1] "SED"  APIM,APIM_CDC,APIM_CIM,APIM_CISM
 SG_ ApaSlotRight1_D_Stat : 11|3@0+ (1,0) [0|7] "SED"  APIM,APIM_CDC,APIM_CIM,APIM_CISM
 SG_ ApaSlotRight3_B_Altr : 16|1@0+ (1,0) [0|1] "SED"  APIM,APIM_CDC,APIM_CIM,APIM_CISM
 SG_ ApaSlotRight2_B_Altr : 17|1@0+ (1,0) [0|1] "SED"  APIM,APIM_CDC,APIM_CIM,APIM_CISM
 SG_ ApaSlotRearY_L_Actl : 23|6@0+ (0.2,-6.4) [-6.4|6.2] "meter"  APIM,APIM_CDC,APIM_CIM,APIM_CISM
 SG_ ApaSlotRight1X_L_Actl : 31|11@0+ (0.02,-20.96) [-20.96|19.98] "meter"  APIM,APIM_CDC,APIM_CIM,APIM_CISM
 SG_ ApaSlotRight2X_L_Actl : 32|11@0+ (0.02,-20.96) [-20.96|19.98] "meter"  APIM,APIM_CDC,APIM_CIM,APIM_CISM
 SG_ ApaSlotRight2_D_Stat : 36|3@0+ (1,0) [0|7] "SED"  APIM,APIM_CDC,APIM_CIM,APIM_CISM
 SG_ ApaSlotRight3X_L_Actl : 53|11@0+ (0.02,-20.96) [-20.96|19.98] "meter"  APIM,APIM_CDC,APIM_CIM,APIM_CISM
 SG_ ApaSlotRight3_D_Stat : 58|3@0+ (1,0) [0|7] "SED"  APIM,APIM_CDC,APIM_CIM,APIM_CISM

BO_ 1237 Active_Park_Assist3_HS3: 8 GWM
 SG_ ApaSlotRef1X_L_Actl : 7|11@0+ (0.02,-20.96) [-20.96|19.98] "meter"  APIM,APIM_CDC,APIM_CIM,APIM_CISM
 SG_ ApaSlotRef2X_L_Actl : 12|11@0+ (0.02,-20.96) [-20.96|19.98] "meter"  APIM,APIM_CDC,APIM_CIM,APIM_CISM
 SG_ ApaSlotRef2Y_L_Actl : 31|11@0+ (0.02,-20.96) [-20.96|19.98] "meter"  APIM,APIM_CDC,APIM_CIM,APIM_CISM
 SG_ ApaSlotRef1Y_L_Actl : 36|11@0+ (0.02,-20.96) [-20.96|19.98] "meter"  APIM,APIM_CDC,APIM_CIM,APIM_CISM
 SG_ DasAttentWarn_D_Dsply : 55|3@0+ (1,0) [0|7] "SED"  APIM_CDC,IPC

BO_ 1238 IPMA_Data5_HS3: 8 GWM
 SG_ IaccVAdjLim_No_Actl : 7|8@0+ (1,0) [0|255] "unitless"  APIM,APIM_CDC,APIM_CIM,APIM_CISM,HUD_ADV,IPC
 SG_ TjaLaneBias_D_Stat : 10|3@0+ (1,0) [0|7] "SED"  APIM_CDC,APIM_CIM,IPC
 SG_ IaccVAdjReas_D_Dsply : 15|5@0+ (1,0) [0|31] "SED"  APIM,APIM_CDC,APIM_CIM,APIM_CISM,HUD_ADV,IPC
 SG_ TjaLcEnbl_D_Stat : 17|2@0+ (1,0) [0|3] "SED"  APIM,APIM_CDC,APIM_CIM,APIM_CISM
 SG_ GfhbMnu_D_Rq : 19|2@0+ (1,0) [0|3] "SED"  APIM,APIM_CDC,APIM_CIM,APIM_CISM,IPC
 SG_ AhbcMnu_D_Rq : 21|2@0+ (1,0) [0|3] "SED"  APIM,APIM_CDC,APIM_CIM,APIM_CISM,IPC
 SG_ TjaLaneBiasEnbl_D_Stat : 23|2@0+ (1,0) [0|3] "SED"  APIM,APIM_CDC,APIM_CIM,APIM_CISM
 SG_ TjaLc_D_Stat : 27|4@0+ (1,0) [0|15] "SED"  APIM_CDC,APIM_CIM,HUD_ADV,IPC
 SG_ TjaCanclMsgTxt_D_Dsply : 31|4@0+ (1,0) [0|15] "SED"  APIM,APIM_CDC,APIM_CIM,IPC
 SG_ FbaAlrt_D_Dsply : 33|2@0+ (1,0) [0|3] "SED"  APIM,APIM_CDC,APIM_CIM,IPC
 SG_ TjaLcWarn_D_Rq : 36|3@0+ (1,0) [0|7] "SED"  APIM_CDC,APIM_CIM,HUD_ADV,IPC
 SG_ TjaLcMsgTxt_D_Rq : 39|3@0+ (1,0) [0|7] "SED"  APIM_CDC,APIM_CIM,HUD_ADV,IPC
 SG_ OraAutoActv_D_Rq : 41|2@0+ (1,0) [0|3] "SED"  APIM_CDC
 SG_ FbaMsg_D_Rq : 43|2@0+ (1,0) [0|3] "SED"  APIM_CDC,APIM_CIM,IPC
 SG_ FbaMnu_D_Rq : 45|2@0+ (1,0) [0|3] "SED"  APIM,APIM_CDC,APIM_CIM
 SG_ Fba_D_Stat : 47|2@0+ (1,0) [0|3] "SED"  APIM,APIM_CDC,APIM_CIM
 SG_ MoisNotfn_D_Rq : 50|3@0+ (1,0) [0|7] "SED"  IPC
 SG_ TjaAutoLcEnbl_D_Stat : 52|2@0+ (1,0) [0|3] "SED"  APIM,APIM_CDC
 SG_ TsrAslButtnPress_D_Rq : 55|3@0+ (1,0) [0|7] "SED"  APIM_CDC,APIM_CIM,IPC
 SG_ TjaLc_D2_Stat : 62|6@0+ (1,0) [0|63] "SED"  APIM,APIM_CDC,APIM_CIM,HUD_ADV,IPC
 SG_ MoisChime_B_Rq : 63|1@0+ (1,0) [0|1] "SED"  IPC

BO_ 1239 CstmDrvMdeData_HS3: 8 GWM
 SG_ CstmDrvMdeTracCtl_D_Rq : 1|2@0+ (1,0) [0|3] "SED" Vector__XXX
 SG_ SeatOccRearChime_B_Rq : 2|1@0+ (1,0) [0|1] "SED"  APIM_CDC,APIM_CIM,IPC
 SG_ ActvDrvMdeCstm_D2_Rq : 7|5@0+ (1,0) [0|31] "SED"  APIM_CDC,APIM_CIM,IPC
 SG_ IndvMdeSteCstm_No_Rq : 11|4@0+ (1,0) [0|15] "unitless"  APIM_CDC,APIM_CIM,IPC
 SG_ CstmDrvMdeMsgTxt_D_Rq : 15|4@0+ (1,0) [0|15] "SED"  APIM_CDC,APIM_CIM,IPC
 SG_ StabBarCnnctLamp_D_Cstm : 17|2@0+ (1,0) [0|3] "SED"  APIM_CDC,APIM_CIM,HUD_ADV,IPC
 SG_ SelDrvMdeCstmLamp_D_Rq : 19|2@0+ (1,0) [0|3] "SED"  APIM_CDC,APIM_CIM,IPC
 SG_ CstmDrvMdePrfl_No_Actl : 23|4@0+ (1,0) [0|15] "unitless"  APIM_CDC,IPC
 SG_ CstmDrvMdeHmi2_D_Rq : 31|5@0+ (1,0) [0|31] "SED" Vector__XXX
 SG_ CstmDrvMdeChassis_D_Rq : 36|5@0+ (1,0) [0|31] "SED" Vector__XXX
 SG_ SelDrvMdeCstm_D_RqDrv : 39|3@0+ (1,0) [0|7] "SED"  IPC
 SG_ IndvMdeSuspCstm_No_Rq : 47|4@0+ (1,0) [0|15] "unitless"  APIM_CDC,APIM_CIM,IPC

BO_ 1242 PowertrainCstmData_HS3: 8 GWM
 SG_ SelDrvMdeCstmPt_D_Rq : 4|5@0+ (1,0) [0|31] "SED" Vector__XXX
 SG_ EngExhMdeQuietCstm_D_Rq : 7|3@0+ (1,0) [0|7] "SED"  APIM_CDC,APIM_CIM,GWM,IPC
 SG_ StopStrtCstm_D_Rq : 15|2@0+ (1,0) [0|3] "SED"  APIM_CDC,APIM_CIM,GWM,IPC

BO_ 1243 Con_BTAud_MCM: 8 ACM
 SG_ Con_BTAudConfiguration : 7|5@0+ (1,0) [0|31] "unitless"  IPC
 SG_ Con_BTAud_Profiles_St : 11|4@0+ (1,0) [0|15] "unitless"  IPC
 SG_ Con_BTAud_InfotainmVer_St : 15|4@0+ (1,0) [0|15] "SED"  IPC

BO_ 1244 Con_MCM: 8 ACM
 SG_ Con_Configuration : 7|5@0+ (1,0) [0|31] "unitless"  IPC
 SG_ Con_Profiles_St : 11|4@0+ (1,0) [0|15] "unitless"  IPC
 SG_ Con_InfotainmentVer_St : 15|4@0+ (1,0) [0|15] "SED"  IPC

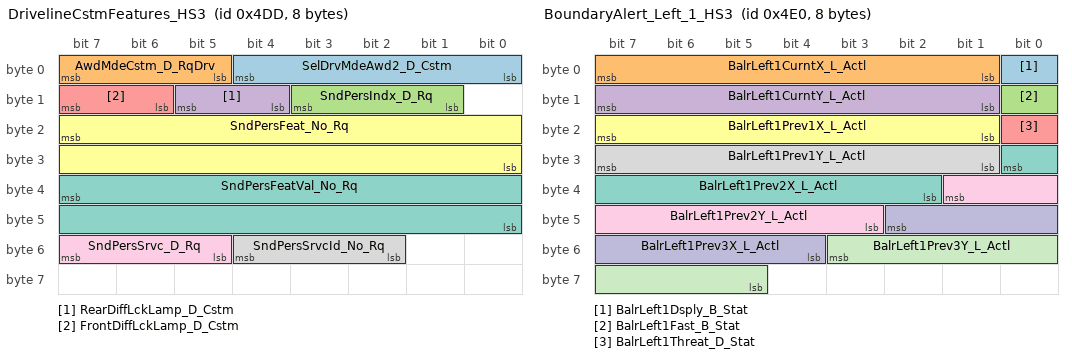
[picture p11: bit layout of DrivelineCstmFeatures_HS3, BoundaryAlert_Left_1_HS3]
BO_ 1245 DrivelineCstmFeatures_HS3: 8 GWM
 SG_ SelDrvMdeAwd2_D_Cstm : 4|5@0+ (1,0) [0|31] "SED" Vector__XXX
 SG_ AwdMdeCstm_D_RqDrv : 7|3@0+ (1,0) [0|7] "SED"  APIM_CDC,APIM_CIM,IPC
 SG_ SndPersIndx_D_Rq : 11|3@0+ (1,0) [0|7] "SED"  ACM
 SG_ RearDiffLckLamp_D_Cstm : 13|2@0+ (1,0) [0|3] "SED"  APIM_CDC,APIM_CIM,IPC
 SG_ FrontDiffLckLamp_D_Cstm : 15|2@0+ (1,0) [0|3] "SED"  APIM_CDC,APIM_CIM,IPC
 SG_ SndPersFeat_No_Rq : 23|16@0+ (1,0) [0|65535] "unitless"  ACM
 SG_ SndPersFeatVal_No_Rq : 39|16@0+ (1,0) [0|65535] "unitless"  ACM
 SG_ SndPersSrvcId_No_Rq : 52|3@0+ (1,0) [0|7] "unitless"  ACM
 SG_ SndPersSrvc_D_Rq : 55|3@0+ (1,0) [0|7] "SED"  ACM

BO_ 1246 TRM_Data1: 8 TRM_ITRM
 SG_ TrlrBrkCtl2BFalt_No_Cs : 7|8@0+ (1,0) [0|255] "unitless"  APIM_CDC,APIM_CIM,GWM,IPC
 SG_ TrlrBrkCtl2_B_Falt : 11|1@0+ (1,0) [0|1] "SED"  APIM_CDC,APIM_CIM,GWM,IPC
 SG_ TrlrBrkCtl2BFalt_No_Cnt : 15|4@0+ (1,0) [0|15] "unitless"  APIM_CDC,APIM_CIM,GWM,IPC

BO_ 1247 PowerDistData_4_HS3: 8 GWM
 SG_ TrlrBrkCtl3_B_Falt : 2|1@0+ (1,0) [0|1] "SED"  TRM_ITRM
 SG_ StopLampBRqTrlrAft_No_Cnt : 6|4@0+ (1,0) [0|15] "Unitless"  TRM_ITRM
 SG_ StopLamp_B_RqTrlrAft : 7|1@0+ (1,0) [0|1] "SED"  TRM_ITRM
 SG_ StopLampBRqTrlrAft_No_Cs : 15|8@0+ (1,0) [0|255] "Unitless"  TRM_ITRM

BO_ 1248 BoundaryAlert_Left_1_HS3: 8 GWM
 SG_ BalrLeft1Dsply_B_Stat : 0|1@0+ (1,0) [0|1] "SED"  APIM_CDC,APIM_CIM,IPC
 SG_ BalrLeft1CurntX_L_Actl : 7|7@0+ (0.5,-32) [-32|31.5] "meter"  APIM_CDC,APIM_CIM,IPC
 SG_ BalrLeft1Fast_B_Stat : 8|1@0+ (1,0) [0|1] "SED"  APIM_CDC,APIM_CIM,IPC
 SG_ BalrLeft1CurntY_L_Actl : 15|7@0+ (0.5,-32) [-32|31.5] "meter"  APIM_CDC,APIM_CIM,IPC
 SG_ BalrLeft1Threat_D_Stat : 16|1@0+ (1,0) [0|1] "SED"  APIM_CDC,APIM_CIM,IPC
 SG_ BalrLeft1Prev1X_L_Actl : 23|7@0+ (0.5,-32) [-32|31.5] "meter"  APIM_CDC,APIM_CIM,IPC
 SG_ BalrLeft1Prev2X_L_Actl : 24|7@0+ (0.5,-32) [-32|31.5] "meter"  APIM_CDC,APIM_CIM,IPC
 SG_ BalrLeft1Prev1Y_L_Actl : 31|7@0+ (0.5,-32) [-32|31.5] "meter"  APIM_CDC,APIM_CIM,IPC
 SG_ BalrLeft1Prev2Y_L_Actl : 33|7@0+ (0.5,-32) [-32|31.5] "meter"  APIM_CDC,APIM_CIM,IPC
 SG_ BalrLeft1Prev3X_L_Actl : 42|7@0+ (0.5,-32) [-32|31.5] "meter"  APIM_CDC,APIM_CIM,IPC
 SG_ BalrLeft1Prev3Y_L_Actl : 51|7@0+ (0.5,-32) [-32|31.5] "meter"  APIM_CDC,APIM_CIM,IPC

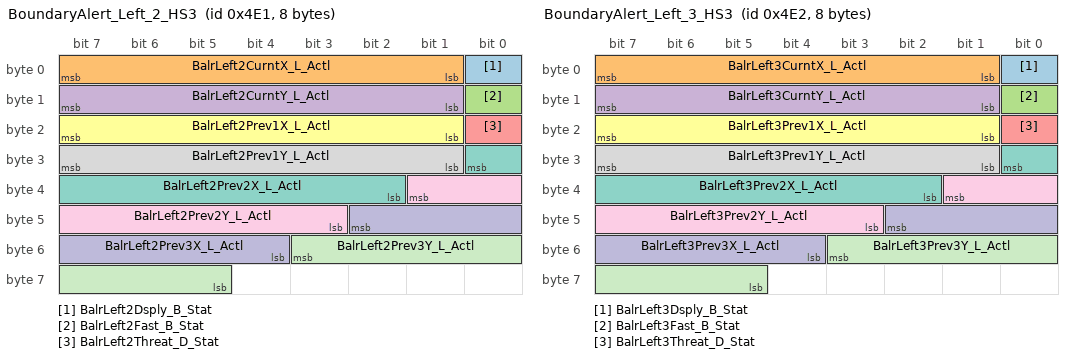
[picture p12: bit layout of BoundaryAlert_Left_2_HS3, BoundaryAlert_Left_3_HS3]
BO_ 1249 BoundaryAlert_Left_2_HS3: 8 GWM
 SG_ BalrLeft2Dsply_B_Stat : 0|1@0+ (1,0) [0|1] "SED"  APIM_CDC,APIM_CIM,IPC
 SG_ BalrLeft2CurntX_L_Actl : 7|7@0+ (0.5,-32) [-32|31.5] "meter"  APIM_CDC,APIM_CIM,IPC
 SG_ BalrLeft2Fast_B_Stat : 8|1@0+ (1,0) [0|1] "SED"  APIM_CDC,APIM_CIM,IPC
 SG_ BalrLeft2CurntY_L_Actl : 15|7@0+ (0.5,-32) [-32|31.5] "meter"  APIM_CDC,APIM_CIM,IPC
 SG_ BalrLeft2Threat_D_Stat : 16|1@0+ (1,0) [0|1] "SED"  APIM_CDC,APIM_CIM,IPC
 SG_ BalrLeft2Prev1X_L_Actl : 23|7@0+ (0.5,-32) [-32|31.5] "meter"  APIM_CDC,APIM_CIM,IPC
 SG_ BalrLeft2Prev2X_L_Actl : 24|7@0+ (0.5,-32) [-32|31.5] "meter"  APIM_CDC,APIM_CIM,IPC
 SG_ BalrLeft2Prev1Y_L_Actl : 31|7@0+ (0.5,-32) [-32|31.5] "meter"  APIM_CDC,APIM_CIM,IPC
 SG_ BalrLeft2Prev2Y_L_Actl : 33|7@0+ (0.5,-32) [-32|31.5] "meter"  APIM_CDC,APIM_CIM,IPC
 SG_ BalrLeft2Prev3X_L_Actl : 42|7@0+ (0.5,-32) [-32|31.5] "meter"  APIM_CDC,APIM_CIM,IPC
 SG_ BalrLeft2Prev3Y_L_Actl : 51|7@0+ (0.5,-32) [-32|31.5] "meter"  APIM_CDC,APIM_CIM,IPC

BO_ 1250 BoundaryAlert_Left_3_HS3: 8 GWM
 SG_ BalrLeft3Dsply_B_Stat : 0|1@0+ (1,0) [0|1] "SED"  APIM_CDC,APIM_CIM,IPC
 SG_ BalrLeft3CurntX_L_Actl : 7|7@0+ (0.5,-32) [-32|31.5] "meter"  APIM_CDC,APIM_CIM,IPC
 SG_ BalrLeft3Fast_B_Stat : 8|1@0+ (1,0) [0|1] "SED"  APIM_CDC,APIM_CIM,IPC
 SG_ BalrLeft3CurntY_L_Actl : 15|7@0+ (0.5,-32) [-32|31.5] "meter"  APIM_CDC,APIM_CIM,IPC
 SG_ BalrLeft3Threat_D_Stat : 16|1@0+ (1,0) [0|1] "SED"  APIM_CDC,APIM_CIM,IPC
 SG_ BalrLeft3Prev1X_L_Actl : 23|7@0+ (0.5,-32) [-32|31.5] "meter"  APIM_CDC,APIM_CIM,IPC
 SG_ BalrLeft3Prev2X_L_Actl : 24|7@0+ (0.5,-32) [-32|31.5] "meter"  APIM_CDC,APIM_CIM,IPC
 SG_ BalrLeft3Prev1Y_L_Actl : 31|7@0+ (0.5,-32) [-32|31.5] "meter"  APIM_CDC,APIM_CIM,IPC
 SG_ BalrLeft3Prev2Y_L_Actl : 33|7@0+ (0.5,-32) [-32|31.5] "meter"  APIM_CDC,APIM_CIM,IPC
 SG_ BalrLeft3Prev3X_L_Actl : 42|7@0+ (0.5,-32) [-32|31.5] "meter"  APIM_CDC,APIM_CIM,IPC
 SG_ BalrLeft3Prev3Y_L_Actl : 51|7@0+ (0.5,-32) [-32|31.5] "meter"  APIM_CDC,APIM_CIM,IPC

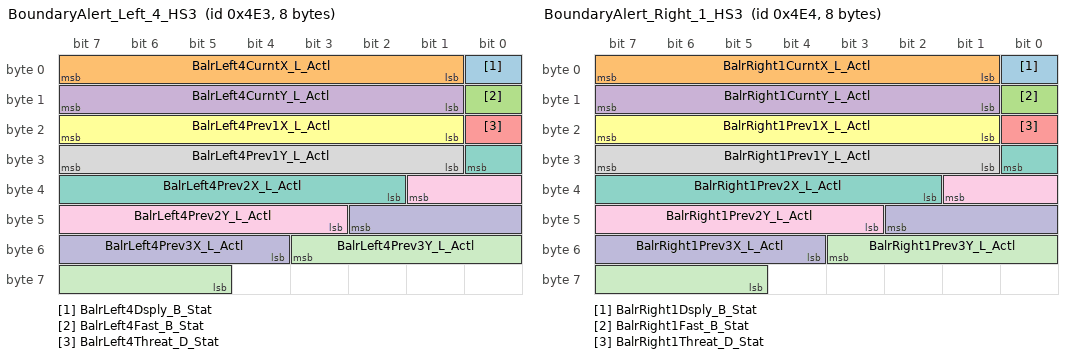
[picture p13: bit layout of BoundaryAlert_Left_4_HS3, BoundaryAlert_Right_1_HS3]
BO_ 1251 BoundaryAlert_Left_4_HS3: 8 GWM
 SG_ BalrLeft4Dsply_B_Stat : 0|1@0+ (1,0) [0|1] "SED"  APIM_CDC,APIM_CIM,IPC
 SG_ BalrLeft4CurntX_L_Actl : 7|7@0+ (0.5,-32) [-32|31.5] "meter"  APIM_CDC,APIM_CIM,IPC
 SG_ BalrLeft4Fast_B_Stat : 8|1@0+ (1,0) [0|1] "SED"  APIM_CDC,APIM_CIM,IPC
 SG_ BalrLeft4CurntY_L_Actl : 15|7@0+ (0.5,-32) [-32|31.5] "meter"  APIM_CDC,APIM_CIM,IPC
 SG_ BalrLeft4Threat_D_Stat : 16|1@0+ (1,0) [0|1] "SED"  APIM_CDC,APIM_CIM,IPC
 SG_ BalrLeft4Prev1X_L_Actl : 23|7@0+ (0.5,-32) [-32|31.5] "meter"  APIM_CDC,APIM_CIM,IPC
 SG_ BalrLeft4Prev2X_L_Actl : 24|7@0+ (0.5,-32) [-32|31.5] "meter"  APIM_CDC,APIM_CIM,IPC
 SG_ BalrLeft4Prev1Y_L_Actl : 31|7@0+ (0.5,-32) [-32|31.5] "meter"  APIM_CDC,APIM_CIM,IPC
 SG_ BalrLeft4Prev2Y_L_Actl : 33|7@0+ (0.5,-32) [-32|31.5] "meter"  APIM_CDC,APIM_CIM,IPC
 SG_ BalrLeft4Prev3X_L_Actl : 42|7@0+ (0.5,-32) [-32|31.5] "meter"  APIM_CDC,APIM_CIM,IPC
 SG_ BalrLeft4Prev3Y_L_Actl : 51|7@0+ (0.5,-32) [-32|31.5] "meter"  APIM_CDC,APIM_CIM,IPC

BO_ 1252 BoundaryAlert_Right_1_HS3: 8 GWM
 SG_ BalrRight1Dsply_B_Stat : 0|1@0+ (1,0) [0|1] "SED"  APIM_CDC,APIM_CIM,IPC
 SG_ BalrRight1CurntX_L_Actl : 7|7@0+ (0.5,-32) [-32|31.5] "meter"  APIM_CDC,APIM_CIM,IPC
 SG_ BalrRight1Fast_B_Stat : 8|1@0+ (1,0) [0|1] "SED"  APIM_CDC,APIM_CIM,IPC
 SG_ BalrRight1CurntY_L_Actl : 15|7@0+ (0.5,-32) [-32|31.5] "meter"  APIM_CDC,APIM_CIM,IPC
 SG_ BalrRight1Threat_D_Stat : 16|1@0+ (1,0) [0|1] "SED"  APIM_CDC,APIM_CIM,IPC
 SG_ BalrRight1Prev1X_L_Actl : 23|7@0+ (0.5,-32) [-32|31.5] "meter"  APIM_CDC,APIM_CIM,IPC
 SG_ BalrRight1Prev2X_L_Actl : 24|7@0+ (0.5,-32) [-32|31.5] "meter"  APIM_CDC,APIM_CIM,IPC
 SG_ BalrRight1Prev1Y_L_Actl : 31|7@0+ (0.5,-32) [-32|31.5] "meter"  APIM_CDC,APIM_CIM,IPC
 SG_ BalrRight1Prev2Y_L_Actl : 33|7@0+ (0.5,-32) [-32|31.5] "meter"  APIM_CDC,APIM_CIM,IPC
 SG_ BalrRight1Prev3X_L_Actl : 42|7@0+ (0.5,-32) [-32|31.5] "meter"  APIM_CDC,APIM_CIM,IPC
 SG_ BalrRight1Prev3Y_L_Actl : 51|7@0+ (0.5,-32) [-32|31.5] "meter"  APIM_CDC,APIM_CIM,IPC

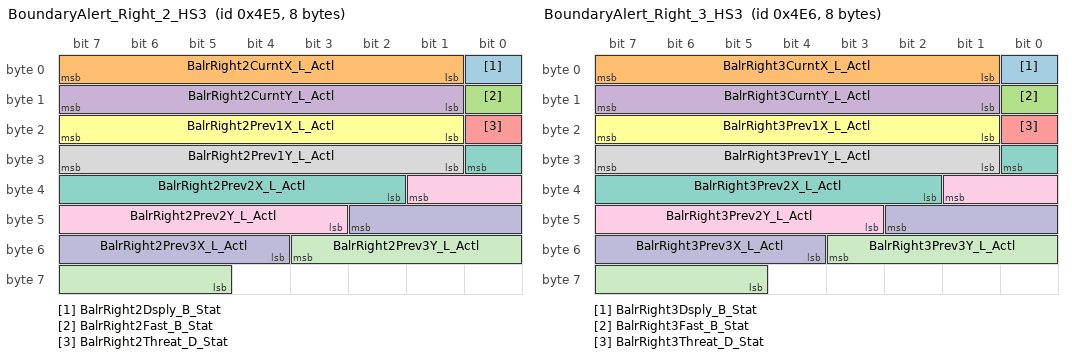
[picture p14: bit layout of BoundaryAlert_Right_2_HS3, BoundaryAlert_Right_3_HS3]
BO_ 1253 BoundaryAlert_Right_2_HS3: 8 GWM
 SG_ BalrRight2Dsply_B_Stat : 0|1@0+ (1,0) [0|1] "SED"  APIM_CDC,APIM_CIM,IPC
 SG_ BalrRight2CurntX_L_Actl : 7|7@0+ (0.5,-32) [-32|31.5] "meter"  APIM_CDC,APIM_CIM,IPC
 SG_ BalrRight2Fast_B_Stat : 8|1@0+ (1,0) [0|1] "SED"  APIM_CDC,APIM_CIM,IPC
 SG_ BalrRight2CurntY_L_Actl : 15|7@0+ (0.5,-32) [-32|31.5] "meter"  APIM_CDC,APIM_CIM,IPC
 SG_ BalrRight2Threat_D_Stat : 16|1@0+ (1,0) [0|1] "SED"  APIM_CDC,APIM_CIM,IPC
 SG_ BalrRight2Prev1X_L_Actl : 23|7@0+ (0.5,-32) [-32|31.5] "meter"  APIM_CDC,APIM_CIM,IPC
 SG_ BalrRight2Prev2X_L_Actl : 24|7@0+ (0.5,-32) [-32|31.5] "meter"  APIM_CDC,APIM_CIM,IPC
 SG_ BalrRight2Prev1Y_L_Actl : 31|7@0+ (0.5,-32) [-32|31.5] "meter"  APIM_CDC,APIM_CIM,IPC
 SG_ BalrRight2Prev2Y_L_Actl : 33|7@0+ (0.5,-32) [-32|31.5] "meter"  APIM_CDC,APIM_CIM,IPC
 SG_ BalrRight2Prev3X_L_Actl : 42|7@0+ (0.5,-32) [-32|31.5] "meter"  APIM_CDC,APIM_CIM,IPC
 SG_ BalrRight2Prev3Y_L_Actl : 51|7@0+ (0.5,-32) [-32|31.5] "meter"  APIM_CDC,APIM_CIM,IPC

BO_ 1254 BoundaryAlert_Right_3_HS3: 8 GWM
 SG_ BalrRight3Dsply_B_Stat : 0|1@0+ (1,0) [0|1] "SED"  APIM_CDC,APIM_CIM,IPC
 SG_ BalrRight3CurntX_L_Actl : 7|7@0+ (0.5,-32) [-32|31.5] "meter"  APIM_CDC,APIM_CIM,IPC
 SG_ BalrRight3Fast_B_Stat : 8|1@0+ (1,0) [0|1] "SED"  APIM_CDC,APIM_CIM,IPC
 SG_ BalrRight3CurntY_L_Actl : 15|7@0+ (0.5,-32) [-32|31.5] "meter"  APIM_CDC,APIM_CIM,IPC
 SG_ BalrRight3Threat_D_Stat : 16|1@0+ (1,0) [0|1] "SED"  APIM_CDC,APIM_CIM,IPC
 SG_ BalrRight3Prev1X_L_Actl : 23|7@0+ (0.5,-32) [-32|31.5] "meter"  APIM_CDC,APIM_CIM,IPC
 SG_ BalrRight3Prev2X_L_Actl : 24|7@0+ (0.5,-32) [-32|31.5] "meter"  APIM_CDC,APIM_CIM,IPC
 SG_ BalrRight3Prev1Y_L_Actl : 31|7@0+ (0.5,-32) [-32|31.5] "meter"  APIM_CDC,APIM_CIM,IPC
 SG_ BalrRight3Prev2Y_L_Actl : 33|7@0+ (0.5,-32) [-32|31.5] "meter"  APIM_CDC,APIM_CIM,IPC
 SG_ BalrRight3Prev3X_L_Actl : 42|7@0+ (0.5,-32) [-32|31.5] "meter"  APIM_CDC,APIM_CIM,IPC
 SG_ BalrRight3Prev3Y_L_Actl : 51|7@0+ (0.5,-32) [-32|31.5] "meter"  APIM_CDC,APIM_CIM,IPC

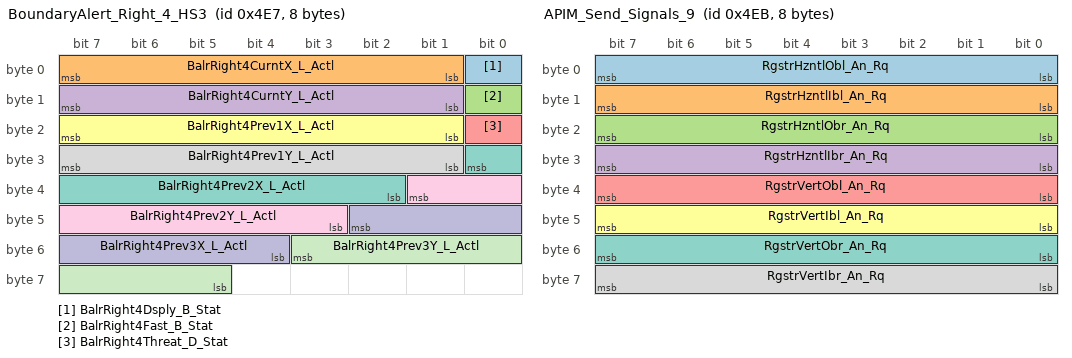
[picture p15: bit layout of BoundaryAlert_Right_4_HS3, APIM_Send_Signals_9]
BO_ 1255 BoundaryAlert_Right_4_HS3: 8 GWM
 SG_ BalrRight4Dsply_B_Stat : 0|1@0+ (1,0) [0|1] "SED"  APIM_CDC,APIM_CIM,IPC
 SG_ BalrRight4CurntX_L_Actl : 7|7@0+ (0.5,-32) [-32|31.5] "meter"  APIM_CDC,APIM_CIM,IPC
 SG_ BalrRight4Fast_B_Stat : 8|1@0+ (1,0) [0|1] "SED"  APIM_CDC,APIM_CIM,IPC
 SG_ BalrRight4CurntY_L_Actl : 15|7@0+ (0.5,-32) [-32|31.5] "meter"  APIM_CDC,APIM_CIM,IPC
 SG_ BalrRight4Threat_D_Stat : 16|1@0+ (1,0) [0|1] "SED"  APIM_CDC,APIM_CIM,IPC
 SG_ BalrRight4Prev1X_L_Actl : 23|7@0+ (0.5,-32) [-32|31.5] "meter"  APIM_CDC,APIM_CIM,IPC
 SG_ BalrRight4Prev2X_L_Actl : 24|7@0+ (0.5,-32) [-32|31.5] "meter"  APIM_CDC,APIM_CIM,IPC
 SG_ BalrRight4Prev1Y_L_Actl : 31|7@0+ (0.5,-32) [-32|31.5] "meter"  APIM_CDC,APIM_CIM,IPC
 SG_ BalrRight4Prev2Y_L_Actl : 33|7@0+ (0.5,-32) [-32|31.5] "meter"  APIM_CDC,APIM_CIM,IPC
 SG_ BalrRight4Prev3X_L_Actl : 42|7@0+ (0.5,-32) [-32|31.5] "meter"  APIM_CDC,APIM_CIM,IPC
 SG_ BalrRight4Prev3Y_L_Actl : 51|7@0+ (0.5,-32) [-32|31.5] "meter"  APIM_CDC,APIM_CIM,IPC

BO_ 1258 IPMB_Data1_HS3: 8 GWM
 SG_ TrlrCamraCalib_D_Stat : 3|2@0+ (1,0) [0|3] "SED"  APIM,APIM_CDC,APIM_CIM,APIM_CISM
 SG_ TrlrCamraView_D_Stat : 7|4@0+ (1,0) [0|15] "SED"  APIM,APIM_CDC,APIM_CIM,APIM_CISM
 SG_ TrlrCamraMsgTxt_D_Rq : 15|6@0+ (1,0) [0|63] "SED"  APIM,APIM_CDC

BO_ 1259 APIM_Send_Signals_9: 8 APIM_CDC
 SG_ RgstrHzntlObl_An_Rq : 7|8@0+ (1,0) [0|255] "degree"  GWM
 SG_ RgstrHzntlIbl_An_Rq : 15|8@0+ (1,0) [0|255] "degree"  GWM
 SG_ RgstrHzntlObr_An_Rq : 23|8@0+ (1,0) [0|255] "degree"  GWM
 SG_ RgstrHzntlIbr_An_Rq : 31|8@0+ (1,0) [0|255] "degree"  GWM
 SG_ RgstrVertObl_An_Rq : 39|8@0+ (1,0) [0|255] "degree"  GWM
 SG_ RgstrVertIbl_An_Rq : 47|8@0+ (1,0) [0|255] "degree"  GWM
 SG_ RgstrVertObr_An_Rq : 55|8@0+ (1,0) [0|255] "degree"  GWM
 SG_ RgstrVertIbr_An_Rq : 63|8@0+ (1,0) [0|255] "degree"  GWM

BO_ 1261 MassageSeat_Data5_HS3: 8 GWM
 SG_ StmsAutoSavDrv_D_Stat : 7|2@0+ (1,0) [0|3] "SED"  APIM_CDC,APIM_CIM

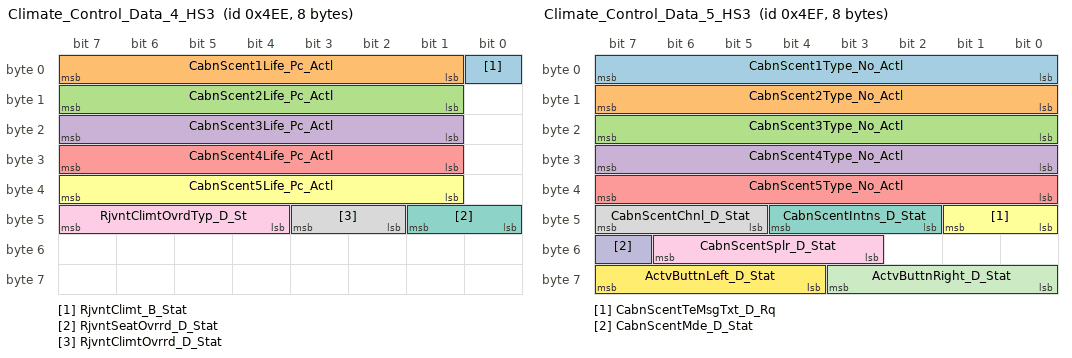
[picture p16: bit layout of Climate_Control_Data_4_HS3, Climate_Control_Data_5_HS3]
BO_ 1262 Climate_Control_Data_4_HS3: 8 GWM
 SG_ RjvntClimt_B_Stat : 0|1@0+ (1,0) [0|1] "SED"  APIM_CDC,APIM_CIM,APIM_CISM
 SG_ CabnScent1Life_Pc_Actl : 7|7@0+ (1,0) [0|127] "unitless"  APIM,APIM_CDC,APIM_CIM,APIM_CISM
 SG_ CabnScent2Life_Pc_Actl : 15|7@0+ (1,0) [0|127] "unitless"  APIM,APIM_CDC,APIM_CIM,APIM_CISM
 SG_ CabnScent3Life_Pc_Actl : 23|7@0+ (1,0) [0|127] "unitless"  APIM,APIM_CDC,APIM_CIM,APIM_CISM
 SG_ CabnScent4Life_Pc_Actl : 31|7@0+ (1,0) [0|127] "unitless"  APIM,APIM_CDC,APIM_CIM,APIM_CISM
 SG_ CabnScent5Life_Pc_Actl : 39|7@0+ (1,0) [0|127] "unitless"  APIM,APIM_CDC,APIM_CIM,APIM_CISM
 SG_ RjvntSeatOvrrd_D_Stat : 41|2@0+ (1,0) [0|3] "SED"  APIM_CDC,APIM_CIM,APIM_CISM
 SG_ RjvntClimtOvrrd_D_Stat : 43|2@0+ (1,0) [0|3] "SED"  APIM_CDC,APIM_CIM,APIM_CISM
 SG_ RjvntClimtOvrdTyp_D_St : 47|4@0+ (1,0) [0|15] "SED"  APIM_CDC,APIM_CIM,APIM_CISM

BO_ 1263 Climate_Control_Data_5_HS3: 8 GWM
 SG_ CabnScent1Type_No_Actl : 7|8@0+ (1,0) [0|255] "unitless"  APIM,APIM_CDC,APIM_CIM,APIM_CISM
 SG_ CabnScent2Type_No_Actl : 15|8@0+ (1,0) [0|255] "unitless"  APIM,APIM_CDC,APIM_CIM,APIM_CISM
 SG_ CabnScent3Type_No_Actl : 23|8@0+ (1,0) [0|255] "unitless"  APIM,APIM_CDC,APIM_CIM,APIM_CISM
 SG_ CabnScent4Type_No_Actl : 31|8@0+ (1,0) [0|255] "unitless"  APIM,APIM_CDC,APIM_CIM,APIM_CISM
 SG_ CabnScent5Type_No_Actl : 39|8@0+ (1,0) [0|255] "unitless"  APIM,APIM_CDC,APIM_CIM,APIM_CISM
 SG_ CabnScentTeMsgTxt_D_Rq : 41|2@0+ (1,0) [0|3] "SED"  APIM,APIM_CDC,APIM_CIM,APIM_CISM
 SG_ CabnScentIntns_D_Stat : 44|3@0+ (1,0) [0|7] "SED"  APIM,APIM_CDC,APIM_CIM,APIM_CISM
 SG_ CabnScentChnl_D_Stat : 47|3@0+ (1,0) [0|7] "SED"  APIM,APIM_CDC,APIM_CIM,APIM_CISM
 SG_ CabnScentSplr_D_Stat : 54|4@0+ (1,0) [0|15] "SED"  APIM,APIM_CDC,APIM_CIM,APIM_CISM
 SG_ CabnScentMde_D_Stat : 55|1@0+ (1,0) [0|1] "SED"  APIM,APIM_CDC,APIM_CIM,APIM_CISM
 SG_ ActvButtnRight_D_Stat : 59|4@0+ (1,0) [0|15] "SED"  APIM,APIM_CDC,APIM_CIM,APIM_CISM
 SG_ ActvButtnLeft_D_Stat : 63|4@0+ (1,0) [0|15] "SED"  APIM,APIM_CDC,APIM_CIM,APIM_CISM

BO_ 1264 AUDIO2_RDISP_WORD_Tx: 8 ACM
 SG_ AUDIO2_RDISP_WORD_Tx : 9|64@0+ (1,0) [0|1.84467440737096E+019] "unitless"  APIM_CDC

BO_ 1266 APIM_Send_Signals_8: 8 APIM_CDC
 SG_ CabnScentCalbType_No_Rq : 7|8@0+ (1,0) [0|255] "SED"  GWM
 SG_ SafePetTempSet_D_Rq : 15|5@0+ (1,0) [0|31] "SED"  GWM
 SG_ CabnScentCalibVal_No_Rq : 23|16@0+ (1,0) [0|65535] "unitless"  GWM

BO_ 1270 APIM_Send_Signals_10: 8 APIM_CDC
 SG_ UpftrElementId_No_Rq : 7|14@0+ (1,0) [0|16383] "unitless"  GWM
 SG_ UpftrDynmcData2_No_Rq : 23|14@0+ (1,0) [0|16383] "unitless"  GWM
 SG_ UpftrDynmcData1_No_Rq : 39|4@0+ (1,0) [0|15] "unitless"  GWM

BO_ 1272 AUDIO2_RDISP_WORD_Rx: 8 APIM_CDC
 SG_ AUDIO2_RDISP_WORD_Rx : 9|64@0+ (1,0) [0|1.84467440737096E+019] "unitless"  ACM

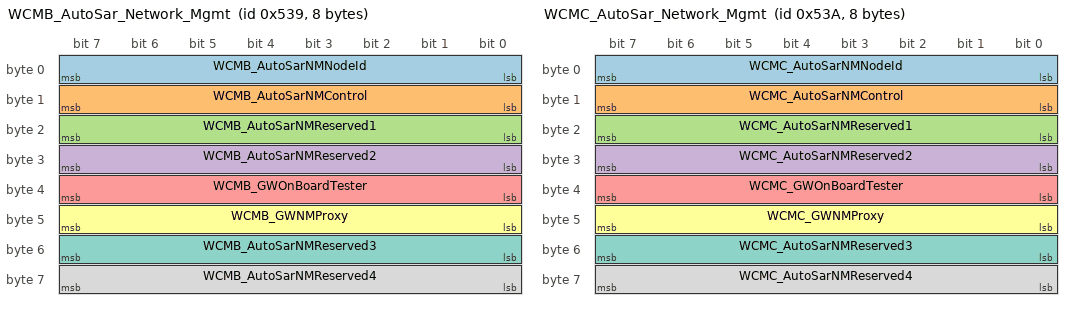
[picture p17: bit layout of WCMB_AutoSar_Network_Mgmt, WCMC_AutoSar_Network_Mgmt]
BO_ 1337 WCMB_AutoSar_Network_Mgmt: 8 WCMB
 SG_ WCMB_AutoSarNMNodeId : 7|8@0+ (1,0) [0|255] "unitless"  GENERIC
 SG_ WCMB_AutoSarNMControl : 15|8@0+ (1,0) [0|255] "unitless"  GENERIC
 SG_ WCMB_AutoSarNMReserved1 : 23|8@0+ (1,0) [0|255] "unitless"  GENERIC
 SG_ WCMB_AutoSarNMReserved2 : 31|8@0+ (1,0) [0|255] "unitless"  GENERIC
 SG_ WCMB_GWOnBoardTester : 39|8@0+ (1,0) [0|255] "unitless"  GENERIC
 SG_ WCMB_GWNMProxy : 47|8@0+ (1,0) [0|255] "unitless"  GENERIC
 SG_ WCMB_AutoSarNMReserved3 : 55|8@0+ (1,0) [0|255] "unitless"  GENERIC
 SG_ WCMB_AutoSarNMReserved4 : 63|8@0+ (1,0) [0|255] "unitless"  GENERIC

BO_ 1338 WCMC_AutoSar_Network_Mgmt: 8 WCMC
 SG_ WCMC_AutoSarNMNodeId : 7|8@0+ (1,0) [0|255] "unitless"  GENERIC
 SG_ WCMC_AutoSarNMControl : 15|8@0+ (1,0) [0|255] "unitless"  GENERIC
 SG_ WCMC_AutoSarNMReserved1 : 23|8@0+ (1,0) [0|255] "unitless"  GENERIC
 SG_ WCMC_AutoSarNMReserved2 : 31|8@0+ (1,0) [0|255] "unitless"  GENERIC
 SG_ WCMC_GWOnBoardTester : 39|8@0+ (1,0) [0|255] "unitless"  GENERIC
 SG_ WCMC_GWNMProxy : 47|8@0+ (1,0) [0|255] "unitless"  GENERIC
 SG_ WCMC_AutoSarNMReserved3 : 55|8@0+ (1,0) [0|255] "unitless"  GENERIC
 SG_ WCMC_AutoSarNMReserved4 : 63|8@0+ (1,0) [0|255] "unitless"  GENERIC

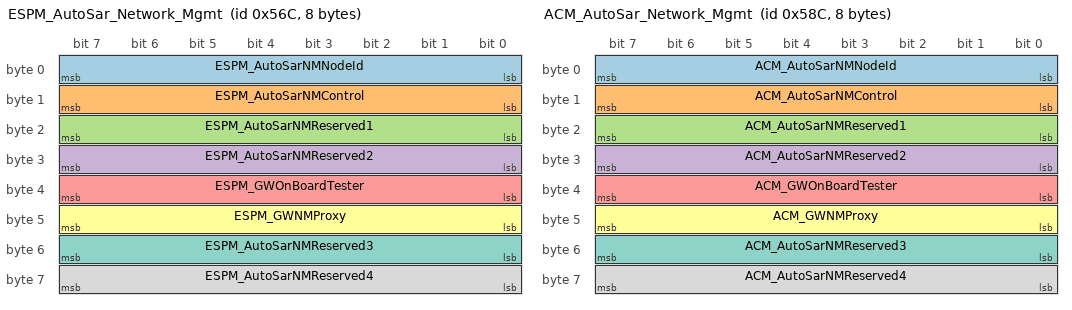
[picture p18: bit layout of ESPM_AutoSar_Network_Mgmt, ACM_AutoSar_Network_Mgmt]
BO_ 1388 ESPM_AutoSar_Network_Mgmt: 8 ESPM
 SG_ ESPM_AutoSarNMNodeId : 7|8@0+ (1,0) [0|255] "unitless"  GENERIC
 SG_ ESPM_AutoSarNMControl : 15|8@0+ (1,0) [0|255] "unitless"  GENERIC
 SG_ ESPM_AutoSarNMReserved1 : 23|8@0+ (1,0) [0|255] "unitless"  GENERIC
 SG_ ESPM_AutoSarNMReserved2 : 31|8@0+ (1,0) [0|255] "unitless"  GENERIC
 SG_ ESPM_GWOnBoardTester : 39|8@0+ (1,0) [0|255] "unitless"  GENERIC
 SG_ ESPM_GWNMProxy : 47|8@0+ (1,0) [0|255] "unitless"  GENERIC
 SG_ ESPM_AutoSarNMReserved3 : 55|8@0+ (1,0) [0|255] "unitless"  GENERIC
 SG_ ESPM_AutoSarNMReserved4 : 63|8@0+ (1,0) [0|255] "unitless"  GENERIC

BO_ 1420 ACM_AutoSar_Network_Mgmt: 8 ACM
 SG_ ACM_AutoSarNMNodeId : 7|8@0+ (1,0) [0|255] "unitless"  GENERIC,GWM,IPC
 SG_ ACM_AutoSarNMControl : 15|8@0+ (1,0) [0|255] "unitless"  GENERIC,GWM,IPC
 SG_ ACM_AutoSarNMReserved1 : 23|8@0+ (1,0) [0|255] "unitless"  GENERIC,GWM,IPC
 SG_ ACM_AutoSarNMReserved2 : 31|8@0+ (1,0) [0|255] "unitless"  GENERIC,GWM,IPC
 SG_ ACM_GWOnBoardTester : 39|8@0+ (1,0) [0|255] "unitless"  GENERIC,GWM,IPC
 SG_ ACM_GWNMProxy : 47|8@0+ (1,0) [0|255] "unitless"  GENERIC,GWM,IPC
 SG_ ACM_AutoSarNMReserved3 : 55|8@0+ (1,0) [0|255] "unitless"  GENERIC,GWM,IPC
 SG_ ACM_AutoSarNMReserved4 : 63|8@0+ (1,0) [0|255] "unitless"  GENERIC,GWM,IPC

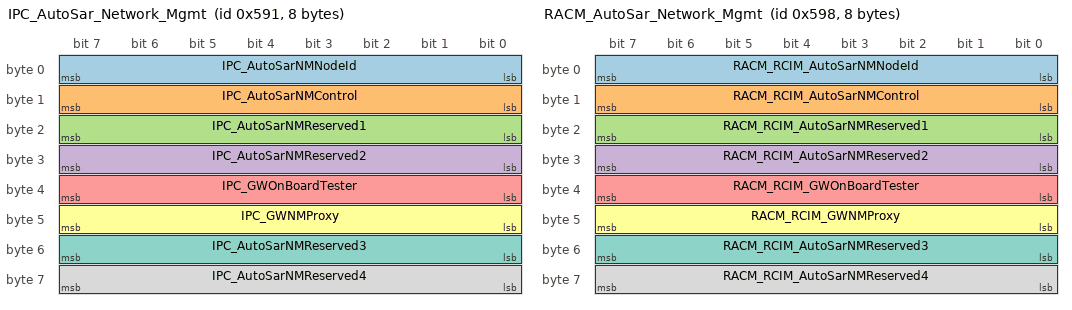
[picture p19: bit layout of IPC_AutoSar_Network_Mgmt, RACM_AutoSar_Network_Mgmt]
BO_ 1425 IPC_AutoSar_Network_Mgmt: 8 IPC
 SG_ IPC_AutoSarNMNodeId : 7|8@0+ (1,0) [0|255] "unitless"  ACM,GENERIC,GWM,HUD_ADV
 SG_ IPC_AutoSarNMControl : 15|8@0+ (1,0) [0|255] "unitless"  ACM,GENERIC,GWM,HUD_ADV
 SG_ IPC_AutoSarNMReserved1 : 23|8@0+ (1,0) [0|255] "unitless"  ACM,GENERIC,GWM,HUD_ADV
 SG_ IPC_AutoSarNMReserved2 : 31|8@0+ (1,0) [0|255] "unitless"  ACM,GENERIC,GWM,HUD_ADV
 SG_ IPC_GWOnBoardTester : 39|8@0+ (1,0) [0|255] "unitless"  ACM,GENERIC,GWM,HUD_ADV
 SG_ IPC_GWNMProxy : 47|8@0+ (1,0) [0|255] "unitless"  ACM,GENERIC,GWM,HUD_ADV
 SG_ IPC_AutoSarNMReserved3 : 55|8@0+ (1,0) [0|255] "unitless"  ACM,GENERIC,GWM,HUD_ADV
 SG_ IPC_AutoSarNMReserved4 : 63|8@0+ (1,0) [0|255] "unitless"  ACM,GENERIC,GWM,HUD_ADV

BO_ 1432 RACM_AutoSar_Network_Mgmt: 8 RACM_RCIM
 SG_ RACM_RCIM_AutoSarNMNodeId : 7|8@0+ (1,0) [0|255] "unitless"  GENERIC,GWM
 SG_ RACM_RCIM_AutoSarNMControl : 15|8@0+ (1,0) [0|255] "unitless"  GENERIC,GWM
 SG_ RACM_RCIM_AutoSarNMReserved1 : 23|8@0+ (1,0) [0|255] "unitless"  GENERIC,GWM
 SG_ RACM_RCIM_AutoSarNMReserved2 : 31|8@0+ (1,0) [0|255] "unitless"  GENERIC,GWM
 SG_ RACM_RCIM_GWOnBoardTester : 39|8@0+ (1,0) [0|255] "unitless"  GENERIC,GWM
 SG_ RACM_RCIM_GWNMProxy : 47|8@0+ (1,0) [0|255] "unitless"  GENERIC,GWM
 SG_ RACM_RCIM_AutoSarNMReserved3 : 55|8@0+ (1,0) [0|255] "unitless"  GENERIC,GWM
 SG_ RACM_RCIM_AutoSarNMReserved4 : 63|8@0+ (1,0) [0|255] "unitless"  GENERIC,GWM

BO_ 1435 HUD_AutoSar_Network_Mgmt: 8 HUD_ADV
 SG_ HUD_ADV_AutoSarNMNodeId : 7|8@0+ (1,0) [0|255] "unitless"  GENERIC,GWM,IPC
 SG_ HUD_ADV_AutoSarNMControl : 15|8@0+ (1,0) [0|255] "unitless"  GENERIC,GWM,IPC
 SG_ HUD_ADV_AutoSarNMReserved1 : 23|8@0+ (1,0) [0|255] "unitless"  GENERIC,GWM,IPC
 SG_ HUD_ADV_AutoSarNMReserved2 : 31|8@0+ (1,0) [0|255] "unitless"  GENERIC,GWM,IPC
 SG_ HUD_ADV_GWOnBoardTester : 39|8@0+ (1,0) [0|255] "unitless"  GENERIC,GWM,IPC
 SG_ HUD_ADV_GWNMProxy : 47|8@0+ (1,0) [0|255] "unitless"  GENERIC,GWM,IPC
 SG_ HUD_ADV_AutoSarNMReserved3 : 55|8@0+ (1,0) [0|255] "unitless"  GENERIC,GWM,IPC
 SG_ HUD_ADV_AutoSarNMReserved4 : 63|8@0+ (1,0) [0|255] "unitless"  GENERIC,GWM,IPC

BO_ 1438 GWM_AutoSar_NetMgmt_HS3: 8 GWM
 SG_ GWM_AutoSarNMNodeId : 7|8@0+ (1,0) [0|255] "unitless"  ACM,APIM,APIM_CDC,APIM_CIM,APIM_CISM,ARM,DSP,HUD_ADV,IPC,RACM_RCIM,TRM_ITRM,WCM,WCMB,WCMC
 SG_ GWM_AutoSarNMControl : 15|8@0+ (1,0) [0|255] "unitless"  ACM,APIM,APIM_CDC,APIM_CIM,APIM_CISM,ARM,DSP,HUD_ADV,IPC,RACM_RCIM,TRM_ITRM,WCM,WCMB,WCMC
 SG_ GWM_AutoSarNMReserved1 : 23|8@0+ (1,0) [0|255] "unitless"  ACM,APIM,APIM_CDC,APIM_CIM,APIM_CISM,ARM,DSP,HUD_ADV,IPC,RACM_RCIM,TRM_ITRM,WCM,WCMB,WCMC
 SG_ GWM_AutoSarNMReserved2 : 31|8@0+ (1,0) [0|255] "unitless"  ACM,APIM,APIM_CDC,APIM_CIM,APIM_CISM,ARM,DSP,HUD_ADV,IPC,RACM_RCIM,TRM_ITRM,WCM,WCMB,WCMC
 SG_ GWM_GWOnBoardTester : 39|8@0+ (1,0) [0|255] "unitless"  ACM,APIM,APIM_CDC,APIM_CIM,APIM_CISM,ARM,DSP,HUD_ADV,IPC,RACM_RCIM,TRM_ITRM,WCM,WCMB,WCMC
 SG_ GWM_GWNMProxy : 47|8@0+ (1,0) [0|255] "unitless"  ACM,APIM,APIM_CDC,APIM_CIM,APIM_CISM,ARM,DSP,HUD_ADV,IPC,RACM_RCIM,TRM_ITRM,WCM,WCMB,WCMC
 SG_ GWM_AutoSarNMReserved3 : 55|8@0+ (1,0) [0|255] "unitless"  ACM,APIM,APIM_CDC,APIM_CIM,APIM_CISM,ARM,DSP,HUD_ADV,IPC,RACM_RCIM,TRM_ITRM,WCM,WCMB,WCMC
 SG_ GWM_AutoSarNMReserved4 : 63|8@0+ (1,0) [0|255] "unitless"  ACM,APIM,APIM_CDC,APIM_CIM,APIM_CISM,ARM,DSP,HUD_ADV,IPC,RACM_RCIM,TRM_ITRM,WCM,WCMB,WCMC

BO_ 1439 WCM_AutoSar_Network_Mgmt: 8 WCM
 SG_ WCM_AutoSarNMNodeId : 7|8@0+ (1,0) [0|255] "unitless"  ACM,GENERIC,HUD_ADV,IPC
 SG_ WCM_AutoSarNMControl : 15|8@0+ (1,0) [0|255] "unitless"  ACM,GENERIC,HUD_ADV,IPC
 SG_ WCM_AutoSarNMReserved1 : 23|8@0+ (1,0) [0|255] "unitless"  ACM,GENERIC,HUD_ADV,IPC
 SG_ WCM_AutoSarNMReserved2 : 31|8@0+ (1,0) [0|255] "unitless"  ACM,GENERIC,HUD_ADV,IPC
 SG_ WCM_GWOnBoardTester : 39|8@0+ (1,0) [0|255] "unitless"  ACM,GENERIC,HUD_ADV,IPC
 SG_ WCM_GWNMProxy : 47|8@0+ (1,0) [0|255] "unitless"  ACM,GENERIC,HUD_ADV,IPC
 SG_ WCM_AutoSarNMReserved3 : 55|8@0+ (1,0) [0|255] "unitless"  ACM,GENERIC,HUD_ADV,IPC
 SG_ WCM_AutoSarNMReserved4 : 63|8@0+ (1,0) [0|255] "unitless"  ACM,GENERIC,HUD_ADV,IPC

BO_ 1478 DSP_AutoSar_Network_Mgmt: 8 DSP
 SG_ DSP_AutoSarNMNodeId : 7|8@0+ (1,0) [0|255] "unitless"  ACM,HUD_ADV,IPC
 SG_ DSP_AutoSarNMControl : 15|8@0+ (1,0) [0|255] "unitless"  ACM,HUD_ADV,IPC
 SG_ DSP_AutoSarNMReserved1 : 23|8@0+ (1,0) [0|255] "unitless"  ACM,HUD_ADV,IPC
 SG_ DSP_AutoSarNMReserved2 : 31|8@0+ (1,0) [0|255] "unitless"  ACM,HUD_ADV,IPC
 SG_ DSP_GWOnBoardTester : 39|8@0+ (1,0) [0|255] "unitless"  ACM,HUD_ADV,IPC
 SG_ DSP_GWNMProxy : 47|8@0+ (1,0) [0|255] "unitless"  ACM,HUD_ADV,IPC
 SG_ DSP_AutoSarNMReserved3 : 55|8@0+ (1,0) [0|255] "unitless"  ACM,HUD_ADV,IPC
 SG_ DSP_AutoSarNMReserved4 : 63|8@0+ (1,0) [0|255] "unitless"  ACM,HUD_ADV,IPC

BO_ 1484 RDAPM_AutoSar_Network_Mgmt: 8 MRCMB_RDAPM_HS3
 SG_ MRCMB_RDAPM_HS3_AutoSarNMNodeId : 7|8@0+ (1,0) [0|255] "unitless" Vector__XXX
 SG_ MRCMB_RDAPM_HS3_AutoSarNMControl : 15|8@0+ (1,0) [0|255] "unitless" Vector__XXX
 SG_ MRCMB_RDAPM_HS3_AutoSarNMReserve : 23|8@0+ (1,0) [0|255] "unitless" Vector__XXX
 SG_ MRCMB_RDAPM_HS3_AutoSarNMRe_0000 : 31|8@0+ (1,0) [0|255] "unitless" Vector__XXX
 SG_ MRCMB_RDAPM_HS3_GWOnBoardTester : 39|8@0+ (1,0) [0|255] "unitless" Vector__XXX
 SG_ MRCMB_RDAPM_HS3_GWNMProxy : 47|8@0+ (1,0) [0|255] "unitless" Vector__XXX
 SG_ MRCMB_RDAPM_HS3_AutoSarNMRe_0001 : 55|8@0+ (1,0) [0|255] "unitless" Vector__XXX
 SG_ MRCMB_RDAPM_HS3_AutoSarNMRe_0002 : 63|8@0+ (1,0) [0|255] "unitless" Vector__XXX

BO_ 1492 TRM_AutoSar_Network_Mgmt: 8 TRM_ITRM
 SG_ TRM_ITRM_AutoSarNMNodeId : 7|8@0+ (1,0) [0|255] "unitless"  GENERIC
 SG_ TRM_ITRM_AutoSarNMControl : 15|8@0+ (1,0) [0|255] "unitless"  GENERIC
 SG_ TRM_ITRM_AutoSarNMReserved1 : 23|8@0+ (1,0) [0|255] "unitless"  GENERIC
 SG_ TRM_ITRM_AutoSarNMReserved2 : 31|8@0+ (1,0) [0|255] "unitless"  GENERIC
 SG_ TRM_ITRM_GWOnBoardTester : 39|8@0+ (1,0) [0|255] "unitless"  GENERIC
 SG_ TRM_ITRM_GWNMProxy : 47|8@0+ (1,0) [0|255] "unitless"  GENERIC
 SG_ TRM_ITRM_AutoSarNMReserved3 : 55|8@0+ (1,0) [0|255] "unitless"  GENERIC
 SG_ TRM_ITRM_AutoSarNMReserved4 : 63|8@0+ (1,0) [0|255] "unitless"  GENERIC

BO_ 1500 ARM_AutoSar_Network_Mgmt: 8 ARM
 SG_ ARM_AutoSarNMNodeId : 7|8@0+ (1,0) [0|255] "unitless"  GENERIC
 SG_ ARM_AutoSarNMControl : 15|8@0+ (1,0) [0|255] "unitless"  GENERIC
 SG_ ARM_AutoSarNMReserved1 : 23|8@0+ (1,0) [0|255] "unitless"  GENERIC
 SG_ ARM_AutoSarNMReserved2 : 31|8@0+ (1,0) [0|255] "unitless"  GENERIC
 SG_ ARM_GWOnBoardTester : 39|8@0+ (1,0) [0|255] "unitless"  GENERIC
 SG_ ARM_GWNMProxy : 47|8@0+ (1,0) [0|255] "unitless"  GENERIC
 SG_ ARM_AutoSarNMReserved3 : 55|8@0+ (1,0) [0|255] "unitless"  GENERIC
 SG_ ARM_AutoSarNMReserved4 : 63|8@0+ (1,0) [0|255] "unitless"  GENERIC

BO_ 1506 APIM_AutoSar_Network_HS3: 8 APIM_CDC
 SG_ APIM_CDC_AutoSarNMNodeId : 7|8@0+ (1,0) [0|255] "unitless"  ACM,APIM_CISM,GENERIC,HUD_ADV,IPC
 SG_ APIM_CDC_AutoSarNMControl : 15|8@0+ (1,0) [0|255] "unitless"  ACM,APIM_CISM,GENERIC,HUD_ADV,IPC
 SG_ APIM_CDC_AutoSarNMReserved1 : 23|8@0+ (1,0) [0|255] "unitless"  ACM,APIM_CISM,GENERIC,HUD_ADV,IPC
 SG_ APIM_CDC_AutoSarNMReserved2 : 31|8@0+ (1,0) [0|255] "unitless"  ACM,APIM_CISM,GENERIC,HUD_ADV,IPC
 SG_ APIM_CDC_GWOnBoardTester : 39|8@0+ (1,0) [0|255] "unitless"  ACM,APIM_CISM,GENERIC,HUD_ADV,IPC
 SG_ APIM_CDC_GWNMProxy : 47|8@0+ (1,0) [0|255] "unitless"  ACM,APIM_CISM,GENERIC,HUD_ADV,IPC
 SG_ APIM_CDC_AutoSarNMReserved3 : 55|8@0+ (1,0) [0|255] "unitless"  ACM,APIM_CISM,GENERIC,HUD_ADV,IPC
 SG_ APIM_CDC_AutoSarNMReserved4 : 63|8@0+ (1,0) [0|255] "unitless"  ACM,APIM_CISM,GENERIC,HUD_ADV,IPC

BO_ 1735 TesterPhysicalReqWCMB: 8 TSTR
 SG_ TesterPhysicalReqWCMB : 7|64@0+ (1,0) [0|1.84467440737096E+019] "unitless"  WCMB

BO_ 1743 TesterPhysicalResWCMB: 8 WCMB
 SG_ TesterPhysicalResWCMB : 7|64@0+ (1,0) [0|1.84467440737096E+019] "unitless"  TSTR

BO_ 1744 TesterPhysicalReqWCMC: 8 TSTR
 SG_ TesterPhysicalReqWCMC : 7|64@0+ (1,0) [0|1.84467440737096E+019] "unitless"  WCMC

BO_ 1752 TesterPhysicalResWCMC: 8 WCMC
 SG_ TesterPhysicalResWCMC : 7|64@0+ (1,0) [0|1.84467440737096E+019] "unitless"  TSTR

BO_ 1761 TesterPhysicalReqESPM: 8 TSTR
 SG_ TesterPhysicalReqESPM : 7|64@0+ (1,0) [0|1.84467440737096E+019] "unitless"  ESPM

BO_ 1769 TesterPhysicalResESPM: 8 ESPM
 SG_ TesterPhysicalResESPM : 7|64@0+ (1,0) [0|1.84467440737096E+019] "unitless"  TSTR

BO_ 1814 TesterPhysicalReqGWM_H3: 8 TSTR
 SG_ TesterPhysicalReqGWM_H3 : 7|64@0+ (1,0) [0|1.84467440737096E+019] "unitless"  GWM

BO_ 1822 TesterPhysicalResGWM_HS3: 8 GWM
 SG_ TesterPhysicalResGWM : 7|64@0+ (1,0) [0|1.84467440737096E+019] "unitless"  TSTR

BO_ 1824 TesterPhysicalReqIPC: 8 TSTR
 SG_ TesterPhysicalReqIPC : 7|64@0+ (1,0) [0|1.84467440737096E+019] "unitless"  IPC

BO_ 1829 TesterPhysicalReqWCM: 8 TSTR
 SG_ TesterPhysicalReqWCM : 7|64@0+ (1,0) [0|1.84467440737096E+019] "unitless"  WCM

BO_ 1831 TesterPhysicalReqACM: 8 TSTR
 SG_ TesterPhysicalReqACM : 7|64@0+ (1,0) [0|1.84467440737096E+019] "unitless"  ACM

BO_ 1832 TesterPhysicalResIPC: 8 IPC
 SG_ TesterPhysicalResIPC : 7|64@0+ (1,0) [0|1.84467440737096E+019] "unitless"  TSTR

BO_ 1837 TesterPhysicalResWCM: 8 WCM
 SG_ TesterPhysicalResWCM : 7|64@0+ (1,0) [0|1.84467440737096E+019] "unitless"  TSTR

BO_ 1839 TesterPhysicalResACM: 8 ACM
 SG_ TesterPhysicalResACM : 7|64@0+ (1,0) [0|1.84467440737096E+019] "unitless"  TSTR

BO_ 1877 TesterPhysicalReqARM: 8 TSTR
 SG_ TesterPhysicalReqARM : 7|64@0+ (1,0) [0|1.84467440737096E+019] "unitless"  ARM

BO_ 1879 TesterPhysicalReqTBM: 8 TSTR
 SG_ TesterPhysicalReqTBM : 7|64@0+ (1,0) [0|1.84467440737096E+019] "unitless"  TRM_ITRM

BO_ 1885 TesterPhysicalResARM: 8 ARM
 SG_ TesterPhysicalResARM : 7|64@0+ (1,0) [0|1.84467440737096E+019] "unitless"  TSTR

BO_ 1908 TesterPhysicalReqRACM: 8 TSTR
 SG_ TesterPhysicalReqRACM : 7|64@0+ (1,0) [0|1.84467440737096E+019] "unitless"  RACM_RCIM

BO_ 1916 TesterPhysicalResRACM: 8 RACM_RCIM
 SG_ TesterPhysicalResRACM : 7|64@0+ (1,0) [0|1.84467440737096E+019] "unitless"  TSTR

BO_ 1923 TesterPhysicalReqDSP: 8 TSTR
 SG_ TesterPhysicalReqDSP : 7|64@0+ (1,0) [0|1.84467440737096E+019] "unitless"  DSP

BO_ 1931 TesterPhysicalResDSP: 8 DSP
 SG_ TesterPhysicalResDSP : 7|64@0+ (1,0) [0|1.84467440737096E+019] "unitless"  TSTR

BO_ 1937 TesterPhysicalReqTRM_ITRM: 8 TSTR
 SG_ TesterPhysicalReqTRM_ITRM : 7|64@0+ (1,0) [0|1.84467440737096E+019] "unitless"  TRM_ITRM

BO_ 1945 TesterPhysicalResTRM_ITRM: 8 TRM_ITRM
 SG_ TesterPhysicalResTRM_ITRM : 7|64@0+ (1,0) [0|1.84467440737096E+019] "unitless"  TSTR

BO_ 1952 TesterPhysicalReqFCIMB: 8 TSTR
 SG_ TesterPhysicalReqFCIMB : 7|64@0+ (1,0) [0|1.84467440737096E+019] "unitless"  FCIMB

BO_ 1960 TesterPhysicalResFCIMB: 8 FCIMB
 SG_ TesterPhysicalResFCIMB : 7|64@0+ (1,0) [0|1.84467440737096E+019] "unitless"  TSTR

BO_ 1968 TesterPhysicalReqRDAPM_20: 8 TSTR
 SG_ TesterPhysicalReqRDAPM_20 : 7|64@0+ (1,0) [0|1.84467440737096E+019] "unitless"  MRCMB_RDAPM_HS3

BO_ 1970 TesterPhysicalReqHUD_ADV: 8 TSTR
 SG_ TesterPhysicalReqHUD_ADV : 7|64@0+ (1,0) [0|1.84467440737096E+019] "unitless"  HUD_ADV

BO_ 1976 TesterPhysicalResRDAPM_20: 8 MRCMB_RDAPM_HS3
 SG_ TesterPhysicalResRDAPM_20 : 7|64@0+ (1,0) [0|1.84467440737096E+019] "unitless"  TSTR

BO_ 1978 TesterPhysicalResHUD_ADV: 8 HUD_ADV
 SG_ TesterPhysicalResHUD_ADV : 7|64@0+ (1,0) [0|1.84467440737096E+019] "unitless"  TSTR

BO_ 2000 TesterPhysicalReqAPIM: 8 TSTR
 SG_ TesterPhysicalReqAPIM : 7|64@0+ (1,0) [0|1.84467440737096E+019] "unitless"  APIM,APIM_CDC,APIM_CIM,APIM_CISM

BO_ 2008 TesterPhysicalResAPIM: 8 APIM_CDC
 SG_ TesterPhysicalResAPIM : 7|64@0+ (1,0) [0|1.84467440737096E+019] "unitless"  TSTR

BO_ 2015 TesterFunctionalReq_H3: 8 TSTR
 SG_ TesterFunctionalReq : 7|64@0+ (1,0) [0|1.84467440737096E+019] "unitless"  ACM,APIM,APIM_CDC,APIM_CIM,APIM_CISM,ARM,DSP,ESPM,FCIMB,GWM,HUD_ADV,IPC,MRCMB_RDAPM_HS3,RACM_RCIM,TRM_ITRM,WCM,WCMB,WCMC

BO_ 2609912024 OTAPhysGWM_ECGtoHUD: 8 GWM
 SG_ OTAPhysGWM_ECGtoHUD : 7|29@0+ (1,0) [0|536870911] "unitless"  HUD_ADV

BO_ 2609915096 OTAPhysGWM_ECGtoDSP: 8 GWM
 SG_ OTAPhysGWM_ECGtoDSP : 7|29@0+ (1,0) [0|536870911] "unitless"  DSP

BO_ 2609942744 OTAPhysGWM_ECGtoTRM_ITRM: 8 GWM
 SG_ OTAPhysGWM_ECGtoTRM_ITRM : 7|29@0+ (1,0) [0|536870911] "unitless"  TRM_ITRM

BO_ 2609958104 OTAPhysGWM_ECGtoMRCMB_RDAPM: 8 GWM
 SG_ OTAPhysGWM_ECGtoMRCMB_RDAPM : 7|29@0+ (1,0) [0|536870911] "unitless"  MRCMB_RDAPM_HS3

BO_ 2609971416 OTAPhysGWM_ECGtoWCM: 8 GWM
 SG_ OTAPhysGWM_ECGtoWCM : 7|29@0+ (1,0) [0|536870911] "unitless"  WCM

BO_ 2609991896 OTAPhysGWM_ECGtoWCMC: 8 GWM
 SG_ OTAPhysGWM_ECGtoWCMC : 7|29@0+ (1,0) [0|536870911] "unitless"  WCMC

BO_ 2610004184 OTAPhysGWM_ECGtoIPC: 8 GWM
 SG_ OTAPhysGWM_ECGtoIPC : 7|29@0+ (1,0) [0|536870911] "unitless"  IPC

BO_ 2610020568 OTAPhysGWM_ECGtoWCMB: 8 GWM
 SG_ OTAPhysGWM_ECGtoWCMB : 7|29@0+ (1,0) [0|536870911] "unitless"  WCMB

BO_ 2610036952 OTAPhysGWM_ECGtoACM: 8 GWM
 SG_ OTAPhysGWM_ECGtoACM : 7|29@0+ (1,0) [0|536870911] "unitless"  ACM

BO_ 2610049240 OTAPhysGWM_ECGtoRACM: 8 GWM
 SG_ OTAPhysGWM_ECGtoRACM : 7|29@0+ (1,0) [0|536870911] "unitless"  RACM_RCIM

BO_ 2610117848 OTAPhysGWM_ECGtoESPM: 8 GWM
 SG_ OTAPhysGWM_ECGtoESPM : 7|29@0+ (1,0) [0|536870911] "unitless"  ESPM

BO_ 2610126854 OTAPhysHUDtoGWM_ECG: 8 HUD_ADV
 SG_ OTAPhysHUDtoGWM_ECG : 7|29@0+ (1,0) [0|536870911] "unitless"  GWM

BO_ 2610126857 OTAPhysDSPtoGWM_ECG: 8 DSP
 SG_ OTAPhysDSPtoGWM_ECG : 7|29@0+ (1,0) [0|536870911] "unitless"  GWM

BO_ 2610126884 OTAPhysTRM_ITRMtoGWM_ECG: 8 TRM_ITRM
 SG_ OTAPhysTRM_ITRMtoGWM_ECG : 7|29@0+ (1,0) [0|536870911] "unitless"  GWM

BO_ 2610126899 OTAPhysMRCMB_RDAPM_HS3toGWM_ECG: 8 MRCMB_RDAPM_HS3
 SG_ OTAPhysMRCMB_RDAPMtoGWM_ECG : 7|29@0+ (1,0) [0|536870911] "unitless"  GWM

BO_ 2610126912 OTAPhysWCMtoGWM_ECG: 8 WCM
 SG_ OTAPhysWCMtoGWM_ECG : 7|29@0+ (1,0) [0|536870911] "unitless"  GWM

BO_ 2610126932 OTAPhysWCMCtoGWM_ECG: 8 WCMC
 SG_ OTAPhysWCMCtoGWM_ECG : 7|29@0+ (1,0) [0|536870911] "unitless"  GWM

BO_ 2610126944 OTAPhysIPCtoGWM_ECG: 8 IPC
 SG_ OTAPhysIPCtoGWM_ECG : 7|29@0+ (1,0) [0|536870911] "unitless"  GWM

BO_ 2610126960 OTAPhysWCMBtoGWM_ECG: 8 WCMB
 SG_ OTAPhysWCMBtoGWM_ECG : 9|29@0+ (1,0) [0|536870911] "unitless"  GWM

BO_ 2610126976 OTAPhysACMtoGWM_ECG: 8 ACM
 SG_ OTAPhysACMtoGWM_ECG : 7|29@0+ (1,0) [0|536870911] "unitless"  GWM

BO_ 2610126988 OTAPhysRACMtoGWM_ECG: 8 RACM_RCIM
 SG_ OTAPhysRACMtoGWM_ECG : 7|29@0+ (1,0) [0|536870911] "unitless"  GWM

BO_ 2610127055 OTAPhysESPMtoGWM_ECG: 8 ESPM
 SG_ OTAPhysESPMtoGWM_ECG : 7|29@0+ (1,0) [0|536870911] "unitless"  GWM

BO_ 2610953432 OTAFuncGWM_ECG_HS3: 8 GWM
 SG_ OTAFuncGWM_ECG : 7|29@0+ (1,0) [0|536870911] "unitless"  ACM,DSP,ESPM,HUD_ADV,IPC,MRCMB_RDAPM_HS3,RACM_RCIM,TRM_ITRM,WCM,WCMB,WCMC

BO_ 2610960600 PARSEDPhysGWM_ECGtoHUD: 8 GWM
 SG_ PARSEDPhysGWM_ECGtoHUD : 7|29@0+ (1,0) [0|536870911] "unitless"  HUD_ADV

BO_ 2610963672 PARSEDPhysGWM_ECGtoDSP: 8 GWM
 SG_ PARSEDPhysGWM_ECGtoDSP : 7|29@0+ (1,0) [0|536870911] "unitless"  DSP

BO_ 2610991320 PARSEDPhysGWM_ECGtoTRM_ITRM: 8 GWM
 SG_ PARSEDPhysGWM_ECGtoTRM_ITRM : 7|29@0+ (1,0) [0|536870911] "unitless"  TRM_ITRM

BO_ 2611006680 PARSEDPhysGWM_ECGtoMRCMB_RDAPM: 8 GWM
 SG_ PARSEDPhysGWM_ECGtoMRCMB_RDAPM : 7|29@0+ (1,0) [0|536870911] "unitless"  MRCMB_RDAPM_HS3

BO_ 2611019992 PARSEDPhysGWM_ECGtoWCM: 8 GWM
 SG_ PARSEDPhysGWM_ECGtoWCM : 7|29@0+ (1,0) [0|536870911] "unitless"  WCM

BO_ 2611040472 PARSEDPhysGWM_ECGtoWCMC: 8 GWM
 SG_ PARSEDPhysGWM_ECGtoWCMC : 7|29@0+ (1,0) [0|536870911] "unitless"  WCMC

BO_ 2611052760 PARSEDPhysGWM_ECGtoIPC: 8 GWM
 SG_ PARSEDPhysGWM_ECGtoIPC : 7|29@0+ (1,0) [0|536870911] "unitless"  IPC

BO_ 2611069144 PARSEDPhysGWM_ECGtoWCMB: 8 GWM
 SG_ PARSEDPhysGWM_ECGtoWCMB : 9|29@0+ (1,0) [0|536870911] "unitless"  WCMB

BO_ 2611085528 PARSEDPhysGWM_ECGtoACM: 8 GWM
 SG_ PARSEDPhysGWM_ECGtoACM : 7|29@0+ (1,0) [0|536870911] "unitless"  ACM

BO_ 2611097816 PARSEDPhysGWM_ECGtoRACM: 8 GWM
 SG_ PARSEDPhysGWM_ECGtoRACM : 7|29@0+ (1,0) [0|536870911] "unitless"  RACM_RCIM

BO_ 2611166424 PARSEDPhysGWM_ECGtoESPM: 8 GWM
 SG_ PARSEDPhysGWM_ECGtoESPM : 7|29@0+ (1,0) [0|536870911] "unitless"  ESPM

BO_ 2611175430 PARSEDPhysHUDtoGWM_ECG: 8 HUD_ADV
 SG_ PARSEDPhysHUDtoGWM_ECG : 7|29@0+ (1,0) [0|536870911] "unitless"  GWM

BO_ 2611175433 PARSEDPhysDSPtoGWM_ECG: 8 DSP
 SG_ PARSEDPhysDSPtoGWM_ECG : 7|29@0+ (1,0) [0|536870911] "unitless"  GWM

BO_ 2611175460 PARSEDPhysTRM_ITRMtoGWM_ECG: 8 TRM_ITRM
 SG_ PARSEDPhysTRM_ITRMtoGWM_ECG : 7|29@0+ (1,0) [0|536870911] "unitless"  GWM

BO_ 2611175475 PARSEDPhysMRCMB_RDAPMtoGWM_ECG: 8 MRCMB_RDAPM_HS3
 SG_ PARSEDPhysMRCMB_RDAPMtoGWM_ECG : 7|29@0+ (1,0) [0|536870911] "unitless"  GWM

BO_ 2611175488 PARSEDPhysWCMtoGWM_ECG: 8 WCM
 SG_ PARSEDPhysWCMtoGWM_ECG : 7|29@0+ (1,0) [0|536870911] "unitless"  GWM

BO_ 2611175508 PARSEDPhysWCMCtoGWM_ECG: 8 WCMC
 SG_ PARSEDPhysWCMCtoGWM_ECG : 7|29@0+ (1,0) [0|536870911] "unitless"  GWM

BO_ 2611175520 PARSEDPhysIPCtoGWM_ECG: 8 IPC
 SG_ PARSEDPhysIPCtoGWM_ECG : 7|29@0+ (1,0) [0|536870911] "unitless"  GWM

BO_ 2611175536 PARSEDPhysWCMBtoGWM_ECG: 8 WCMB
 SG_ PARSEDPhysWCMBtoGWM_ECG : 7|29@0+ (1,0) [0|536870911] "unitless"  GWM

BO_ 2611175552 PARSEDPhysACMtoGWM_ECG: 8 ACM
 SG_ PARSEDPhysACMtoGWM_ECG : 7|29@0+ (1,0) [0|536870911] "unitless"  GWM

BO_ 2611175564 PARSEDPhysRACMtoGWM_ECG: 8 RACM_RCIM
 SG_ PARSEDPhysRACMtoGWM_ECG : 7|29@0+ (1,0) [0|536870911] "unitless"  GWM

BO_ 2611175631 PARSEDPhysESPMtoGWM_ECG: 8 ESPM
 SG_ PARSEDPhysESPMtoGWM_ECG : 7|29@0+ (1,0) [0|536870911] "unitless"  GWM

BO_ 2612002008 PARSEDFuncGWM_ECG_HS3: 8 GWM
 SG_ PARSEDFuncGWM_ECG : 7|29@0+ (1,0) [0|536870911] "unitless"  ACM,DSP,ESPM,HUD_ADV,IPC,MRCMB_RDAPM_HS3,RACM_RCIM,TRM_ITRM,WCM,WCMB,WCMC

BO_ 2612009176 PARSEDPushFcGWM_ECGtoHUD: 8 GWM
 SG_ PARSEDPushFcGWM_ECGtoHUD : 7|29@0+ (1,0) [0|536870911] "unitless"  HUD_ADV

BO_ 2612012248 PARSEDPushFcGWM_ECGtoDSP: 8 GWM
 SG_ PARSEDPushFcGWM_ECGtoDSP : 7|29@0+ (1,0) [0|536870911] "unitless"  DSP

BO_ 2612039896 PARSEDPushFcGWM_ECGtoTRM_ITRM: 8 GWM
 SG_ PARSEDPushFcGWM_ECGtoTRM_ITRM : 7|29@0+ (1,0) [0|536870911] "unitless"  TRM_ITRM

BO_ 2612055256 PARSEDPushFcGWM_ECGtoMRCMB_RDAPM: 8 GWM
 SG_ PARSEDPushFcGWM_ECGtoMRCMB_RDAPM : 7|29@0+ (1,0) [0|536870911] "unitless"  MRCMB_RDAPM_HS3

BO_ 2612068568 PARSEDPushFcGWM_ECGtoWCM: 8 GWM
 SG_ PARSEDPushFcGWM_ECGtoWCM : 7|29@0+ (1,0) [0|536870911] "unitless"  WCM

BO_ 2612089048 PARSEDPushFcGWM_ECGtoWCMC: 8 GWM
 SG_ PARSEDPushFcGWM_ECGtoWCMC : 7|29@0+ (1,0) [0|536870911] "unitless"  WCMC

BO_ 2612101336 PARSEDPushFcGWM_ECGtoIPC: 8 GWM
 SG_ PARSEDPushFcGWM_ECGtoIPC : 7|29@0+ (1,0) [0|536870911] "unitless"  IPC

BO_ 2612117720 PARSEDPushFcGWM_ECGtoWCMB: 8 GWM
 SG_ PARSEDPushFcGWM_ECGtoWCMB : 9|29@0+ (1,0) [0|536870911] "unitless"  WCMB

BO_ 2612134104 PARSEDPushFcGWM_ECGtoACM: 8 GWM
 SG_ PARSEDPushFcGWM_ECGtoACM : 7|29@0+ (1,0) [0|536870911] "unitless"  ACM

BO_ 2612146392 PARSEDPushFcGWM_ECGtoRACM: 8 GWM
 SG_ PARSEDPushFcGWM_ECGtoRACM : 7|29@0+ (1,0) [0|536870911] "unitless"  RACM_RCIM

BO_ 2612215000 PARSEDPushFcGWM_ECGtoESPM: 8 GWM
 SG_ PARSEDPushFcGWM_ECGtoESPM : 7|29@0+ (1,0) [0|536870911] "unitless"  ESPM

BO_ 2612224006 PARSEDPushHUDtoGWM_ECG: 8 HUD_ADV
 SG_ PARSEDPushHUDtoGWM_ECG : 7|29@0+ (1,0) [0|536870911] "unitless"  GWM

BO_ 2612224009 PARSEDPushDSPtoGWM_ECG: 8 DSP
 SG_ PARSEDPushDSPtoGWM_ECG : 7|29@0+ (1,0) [0|536870911] "unitless"  GWM

BO_ 2612224036 PARSEDPushTRM_ITRMtoGWM_ECG: 8 TRM_ITRM
 SG_ PARSEDPushTRM_ITRMtoGWM_ECG : 7|29@0+ (1,0) [0|536870911] "unitless"  GWM

BO_ 2612224051 PARSEDPushMRCMB_RDAPM_HS3toGWM_E: 8 MRCMB_RDAPM_HS3
 SG_ PARSEDPushMRCMB_RDAPMtoGWM_ECG : 7|29@0+ (1,0) [0|536870911] "unitless"  GWM

BO_ 2612224064 PARSEDPushWCMtoGWM_ECG: 8 WCM
 SG_ PARSEDPushWCMtoGWM_ECG : 7|29@0+ (1,0) [0|536870911] "unitless"  GWM

BO_ 2612224084 PARSEDPushWCMCtoGWM_ECG: 8 WCMC
 SG_ PARSEDPushWCMCtoGWM_ECG : 7|29@0+ (1,0) [0|536870911] "unitless"  GWM

BO_ 2612224096 PARSEDPushIPCtoGWM_ECG: 8 IPC
 SG_ PARSEDPushIPCtoGWM_ECG : 7|29@0+ (1,0) [0|536870911] "unitless"  GWM

BO_ 2612224112 PARSEDPushWCMBtoGWM_ECG: 8 WCMB
 SG_ PARSEDPushWCMBtoGWM_ECG : 7|29@0+ (1,0) [0|536870911] "unitless"  GWM

BO_ 2612224128 PARSEDPushACMtoGWM_ECG: 8 ACM
 SG_ PARSEDPushACMtoGWM_ECG : 7|29@0+ (1,0) [0|536870911] "unitless"  GWM

BO_ 2612224140 PARSEDPushRACMtoGWM_ECG: 8 RACM_RCIM
 SG_ PARSEDPushRACMtoGWM_ECG : 7|29@0+ (1,0) [0|536870911] "unitless"  GWM

BO_ 2612224207 PARSEDPushESPMoGWM_ECG: 8 ESPM
 SG_ PARSEDPushESPMoGWM_ECG : 7|29@0+ (1,0) [0|536870911] "unitless"  ESPM,MRCMB_RDAPM_HS3

BO_ 2613060824 SymKeyPhysGWM_ECGtoDSP: 8 GWM
 SG_ SymKeyPhysGWM_ECGtoDSP : 7|29@0+ (1,0) [0|536870911] "unitless"  DSP

BO_ 2613103832 SymKeyPhysGWM_ECGtoMRCMB_RDAPM_H: 8 GWM
 SG_ SymKeyPhysGWM_ECGtoMRCMB_RDAPM : 7|29@0+ (1,0) [0|536870911] "unitless"  MRCMB_RDAPM_HS3

BO_ 2613182680 SymKeyPhysGWM_ECGtoACM: 8 GWM
 SG_ SymKeyPhysGWM_ECGtoACM : 7|29@0+ (1,0) [0|536870911] "unitless"  ACM

BO_ 2613194968 SymKeyPhysGWM_ECGtoRACM: 8 GWM
 SG_ SymKeyPhysGWM_ECGtoRACM : 7|29@0+ (1,0) [0|536870911] "unitless"  RACM_RCIM

BO_ 2613263576 SymKeyPhysGWM_ECGtoESPM: 8 GWM
 SG_ SymKeyPhysGWM_ECGtoESPM : 7|29@0+ (1,0) [0|536870911] "unitless"  ESPM

BO_ 2613272585 SymKeyPhysDSPtoGWM_ECG: 8 DSP
 SG_ SymKeyPhysDSPtoGWM_ECG : 7|29@0+ (1,0) [0|536870911] "unitless"  GWM

BO_ 2613272627 SymKeyPhysMRCMB_RDAPM_HS3toGWM_E: 8 MRCMB_RDAPM_HS3
 SG_ SymKeyPhysMRCMB_RDAPMtoGWM_ECG : 7|29@0+ (1,0) [0|536870911] "unitless"  GWM

BO_ 2613272704 SymKeyPhysACMtoGWM_ECG: 8 ACM
 SG_ SymKeyPhysACMtoGWM_ECG : 7|29@0+ (1,0) [0|536870911] "unitless"  GWM

BO_ 2613272716 SymKeyPhysRACMtoGWM_ECG: 8 RACM_RCIM
 SG_ SymKeyPhysRACMtoGWM_ECG : 7|29@0+ (1,0) [0|536870911] "unitless"  GWM

BO_ 2613272783 SymKeyPhysESPMtoGWM_ECG: 8 ESPM
 SG_ SymKeyPhysESPMtoGWM_ECG : 7|29@0+ (1,0) [0|536870911] "unitless"  GWM

BO_ 2614099160 SymKeyFuncGWM_ECG_HS3: 8 GWM
 SG_ SymKeyFuncGWM_ECG : 7|29@0+ (1,0) [0|536870911] "unitless"  ACM,DSP,ESPM,IPC,MRCMB_RDAPM_HS3,RACM_RCIM,WCM

BO_TX_BU_ 1185 : APIM_CDC,APIM_CIM,APIM_CISM,IPC;
BO_TX_BU_ 1188 : APIM_CDC,APIM_CIM,APIM_CISM,IPC;
BO_TX_BU_ 1192 : APIM,APIM_CDC,APIM_CIM,APIM_CISM;
BO_TX_BU_ 1202 : APIM,APIM_CDC,APIM_CISM;
BO_TX_BU_ 1208 : APIM,APIM_CDC;
BO_TX_BU_ 1232 : ACM,APIM_CIM,APIM_CISM;
BO_TX_BU_ 1259 : APIM,APIM_CDC,APIM_CIM,APIM_CISM;
BO_TX_BU_ 1266 : APIM,APIM_CDC,APIM_CISM;
BO_TX_BU_ 1270 : APIM,APIM_CDC;
BO_TX_BU_ 1506 : APIM,APIM_CDC,APIM_CIM,APIM_CISM;
BO_TX_BU_ 2008 : APIM,APIM_CDC,APIM_CIM,APIM_CISM;
CM_ BO_ 1184 "TP message";
CM_ BO_ 2015 "OBDII Request ($7DF) messages are for FNOS 1.0.1 only.
Diagnostic Functional Addressing ($7DF) and Dual Rate Periodic messages are for FNOS I3 only.";
BA_DEF_ BO_  "E2EDataId" INT 0 65535;
BA_DEF_ BO_  "E2EDataLength" INT 0 512;
BA_DEF_ BO_  "E2EProfile" STRING ;
BA_DEF_ BO_  "GenMsgRoutingTimeoutTime" INT 0 5000;
BA_DEF_ BO_  "MessageGateway" ENUM  "No","Yes";
BA_DEF_ BO_  "VFrameFormat" ENUM  "StandardCAN","ExtendedCAN","reserved","reserved","reserved","reserved","reserved","reserved","reserved","reserved","reserved","reserved","reserved","reserved","StandardCAN_FD","ExtendedCAN_FD";
BA_DEF_ SG_  "ECGUsedRxSignal" ENUM  "No","Yes";
BA_DEF_ SG_  "ECGUsedTxSignal" ENUM  "No","Yes";
BA_DEF_ SG_  "GenSigInactiveValue" INT 0 100000;
BA_DEF_ SG_  "GenSigSendType" ENUM  "Cyclic","OnWrite","vector_leerstring","OnChange","vector_leerstring","IfActive","vector_leerstring","NoSigSendType";
BA_DEF_ BO_  "NetworkInitialization" ENUM  "No","Yes";
BA_DEF_ SG_  "GenSigStartValue" HEX 0 268435455;
BA_DEF_ BO_  "GenMsgStartDelayTime" INT 0 10000;
BA_DEF_ SG_  "WakeupSignal" ENUM  "No","Yes";
BA_DEF_ BO_  "GenMsgNrOfRepetition" INT 0 100;
BA_DEF_ BO_  "GenMsgDelayTime" INT 0 1000;
BA_DEF_ BO_  "GenMsgCycleTime" INT 0 100000;
BA_DEF_ BO_  "GenMsgSendType" ENUM  "FixedPeriodic","Event","EnabledPeriodic","NotUsed","NotUsed","EventPeriodic","NotUsed","NotUsed","NoMsgSendType";
BA_DEF_ BO_  "FrameRouting" STRING ;
BA_DEF_ BO_  "TpTxIndex" INT 0 536870911;
BA_DEF_ BO_  "OvtpPushApplication" ENUM  "FALSE","TRUE";
BA_DEF_ BO_  "SCP_FreshnessValueLength" INT 0 512;
BA_DEF_ BO_  "SCP_FreshnessValueTxLength" INT 0 512;
BA_DEF_ BO_  "SCP_AuthInfoTxLength" INT 0 512;
BA_DEF_ BO_  "NmAsrMessage" ENUM  "No","Yes";
BA_DEF_ BO_  "DiagState" ENUM  "No","Yes";
BA_DEF_ BO_  "DiagRequest" ENUM  "No","Yes";
BA_DEF_ BO_  "DiagResponse" ENUM  "No","Yes";
BA_DEF_ BO_  "GenMsgILSupport" ENUM  "No","Yes";
BA_DEF_ SG_  "SystemSignalLongSymbol" STRING ;
BA_DEF_ BO_  "SystemMessageLongSymbol" STRING ;
BA_DEF_DEF_  "E2EDataId" 1;
BA_DEF_DEF_  "E2EDataLength" 0;
BA_DEF_DEF_  "E2EProfile" "";
BA_DEF_DEF_  "GenMsgRoutingTimeoutTime" 0;
BA_DEF_DEF_  "MessageGateway" "No";
BA_DEF_DEF_  "VFrameFormat" "StandardCAN";
BA_DEF_DEF_  "ECGUsedRxSignal" "No";
BA_DEF_DEF_  "ECGUsedTxSignal" "No";
BA_DEF_DEF_  "GenSigInactiveValue" 0;
BA_DEF_DEF_  "GenSigSendType" "NoSigSendType";
BA_DEF_DEF_  "NetworkInitialization" "Yes";
BA_DEF_DEF_  "GenSigStartValue" 0;
BA_DEF_DEF_  "GenMsgStartDelayTime" 0;
BA_DEF_DEF_  "WakeupSignal" "No";
BA_DEF_DEF_  "GenMsgNrOfRepetition" 1;
BA_DEF_DEF_  "GenMsgDelayTime" 20;
BA_DEF_DEF_  "GenMsgCycleTime" 0;
BA_DEF_DEF_  "GenMsgSendType" "NoMsgSendType";
BA_DEF_DEF_  "FrameRouting" "";
BA_DEF_DEF_  "TpTxIndex" 0;
BA_DEF_DEF_  "OvtpPushApplication" "FALSE";
BA_DEF_DEF_  "SCP_FreshnessValueLength" 64;
BA_DEF_DEF_  "SCP_FreshnessValueTxLength" 11;
BA_DEF_DEF_  "SCP_AuthInfoTxLength" 53;
BA_DEF_DEF_  "NmAsrMessage" "No";
BA_DEF_DEF_  "DiagState" "No";
BA_DEF_DEF_  "DiagRequest" "No";
BA_DEF_DEF_  "DiagResponse" "No";
BA_DEF_DEF_  "GenMsgILSupport" "Yes";
BA_DEF_DEF_  "SystemSignalLongSymbol" "";
BA_DEF_DEF_  "SystemMessageLongSymbol" "";
BA_ "FrameRouting" BO_ 1152 "FD1_CAN,0x480;";
BA_ "FrameRouting" BO_ 1153 "HS2_CAN,0x481;";
BA_ "FrameRouting" BO_ 1155 "FD1_CAN,0x483;";
BA_ "FrameRouting" BO_ 1156 "FD1_CAN,0x36D;";
BA_ "FrameRouting" BO_ 1157 "MS2_CAN,0x485;";
BA_ "FrameRouting" BO_ 1158 "MS2_CAN,0x486;";
BA_ "FrameRouting" BO_ 1159 "FD2_CAN,0x487;";
BA_ "FrameRouting" BO_ 1161 "HS2_CAN,0x4A5;";
BA_ "FrameRouting" BO_ 1163 "FD3_CAN,0x48B;";
BA_ "FrameRouting" BO_ 1164 "FD3_CAN,0x48C;";
BA_ "FrameRouting" BO_ 1165 "FD3_CAN,0x48D;";
BA_ "FrameRouting" BO_ 1166 "FD3_CAN,0x48E;";
BA_ "TpTxIndex" BO_ 1184 20;
BA_ "FrameRouting" BO_ 1184 "FD2_CAN,0x4A0;";
BA_ "TpTxIndex" BO_ 1185 51;
BA_ "NetworkInitialization" BO_ 1185 0;
BA_ "FrameRouting" BO_ 1186 "FD1_CAN,0x4A2;";
BA_ "TpTxIndex" BO_ 1187 52;
BA_ "FrameRouting" BO_ 1187 "FD2_CAN,0x4A3;";
BA_ "TpTxIndex" BO_ 1188 55;
BA_ "NetworkInitialization" BO_ 1188 0;
BA_ "FrameRouting" BO_ 1189 "FD3_CAN,0x4A5;MS1_CAN,0x4A5;";
BA_ "TpTxIndex" BO_ 1192 20;
BA_ "TpTxIndex" BO_ 1195 52;
BA_ "FrameRouting" BO_ 1200 "FD1_CAN,0x4B0;";
BA_ "TpTxIndex" BO_ 1202 40;
BA_ "GenMsgSendType" BO_ 1203 5;
BA_ "GenMsgCycleTime" BO_ 1203 1000;
BA_ "FrameRouting" BO_ 1204 "FD1_CAN,0x4B4;";
BA_ "FrameRouting" BO_ 1205 "FD1_CAN,0x4B5;";
BA_ "GenMsgSendType" BO_ 1208 5;
BA_ "GenMsgCycleTime" BO_ 1208 1000;
BA_ "TpTxIndex" BO_ 1210 40;
BA_ "GenMsgSendType" BO_ 1211 5;
BA_ "GenMsgCycleTime" BO_ 1211 1000;
BA_ "FrameRouting" BO_ 1212 "FD1_CAN,0x4BC;";
BA_ "FrameRouting" BO_ 1216 "FD3_CAN,0x4C0;";
BA_ "FrameRouting" BO_ 1217 "FD3_CAN,0x4C1;";
BA_ "FrameRouting" BO_ 1218 "FD1_CAN,0x4C2;";
BA_ "FrameRouting" BO_ 1223 "FD3_CAN,0x4C7;";
BA_ "FrameRouting" BO_ 1224 "FD3_CAN,0x4C8;";
BA_ "FrameRouting" BO_ 1225 "MS1_CAN,0x4C9;";
BA_ "FrameRouting" BO_ 1229 "FD3_CAN,0x4CD;FD1_CAN,0x4CD;";
BA_ "GenMsgSendType" BO_ 1232 0;
BA_ "GenMsgCycleTime" BO_ 1232 1000;
BA_ "FrameRouting" BO_ 1235 "FD1_CAN,0x4D3;FD3_CAN,0x4D3;";
BA_ "FrameRouting" BO_ 1236 "FD1_CAN,0x4D4;FD3_CAN,0x4D4;";
BA_ "FrameRouting" BO_ 1237 "FD1_CAN,0x4D5;FD3_CAN,0x4D5;";
BA_ "FrameRouting" BO_ 1238 "FD1_CAN,0x4D6;FD3_CAN,0x4D6;";
BA_ "GenMsgSendType" BO_ 1239 5;
BA_ "GenMsgCycleTime" BO_ 1239 1000;
BA_ "GenMsgSendType" BO_ 1242 5;
BA_ "GenMsgCycleTime" BO_ 1242 1000;
BA_ "GenMsgSendType" BO_ 1243 0;
BA_ "GenMsgCycleTime" BO_ 1243 1000;
BA_ "GenMsgSendType" BO_ 1244 0;
BA_ "GenMsgCycleTime" BO_ 1244 1000;
BA_ "GenMsgSendType" BO_ 1245 5;
BA_ "GenMsgCycleTime" BO_ 1245 1000;
BA_ "GenMsgSendType" BO_ 1246 5;
BA_ "GenMsgCycleTime" BO_ 1246 100;
BA_ "FrameRouting" BO_ 1247 "FD1_CAN,0x4DF;";
BA_ "FrameRouting" BO_ 1248 "FD1_CAN,0x4E0;FD3_CAN,0x4E0;";
BA_ "FrameRouting" BO_ 1249 "FD1_CAN,0x4E1;FD3_CAN,0x4E1;";
BA_ "FrameRouting" BO_ 1250 "FD1_CAN,0x4E2;FD3_CAN,0x4E2;";
BA_ "FrameRouting" BO_ 1251 "FD1_CAN,0x4E3;FD3_CAN,0x4E3;";
BA_ "FrameRouting" BO_ 1252 "FD1_CAN,0x4E4;FD3_CAN,0x4E4;";
BA_ "FrameRouting" BO_ 1253 "FD1_CAN,0x4E5;FD3_CAN,0x4E5;";
BA_ "FrameRouting" BO_ 1254 "FD1_CAN,0x4E6;FD3_CAN,0x4E6;";
BA_ "FrameRouting" BO_ 1255 "FD1_CAN,0x4E7;FD3_CAN,0x4E7;";
BA_ "FrameRouting" BO_ 1258 "MS2_CAN,0x4EA;";
BA_ "GenMsgSendType" BO_ 1259 5;
BA_ "GenMsgCycleTime" BO_ 1259 1000;
BA_ "FrameRouting" BO_ 1261 "MS1_CAN,0x4ED;";
BA_ "FrameRouting" BO_ 1262 "MS1_CAN,0x4EE;";
BA_ "FrameRouting" BO_ 1263 "MS1_CAN,0x4EF;";
BA_ "TpTxIndex" BO_ 1264 126;
BA_ "GenMsgSendType" BO_ 1266 5;
BA_ "GenMsgCycleTime" BO_ 1266 10000;
BA_ "GenMsgSendType" BO_ 1270 5;
BA_ "GenMsgCycleTime" BO_ 1270 1000;
BA_ "TpTxIndex" BO_ 1272 126;
BA_ "NmAsrMessage" BO_ 1337 1;
BA_ "NetworkInitialization" BO_ 1337 0;
BA_ "GenMsgSendType" BO_ 1337 0;
BA_ "GenMsgILSupport" BO_ 1337 0;
BA_ "GenMsgCycleTime" BO_ 1337 1000;
BA_ "NmAsrMessage" BO_ 1338 1;
BA_ "NetworkInitialization" BO_ 1338 0;
BA_ "GenMsgSendType" BO_ 1338 0;
BA_ "GenMsgILSupport" BO_ 1338 0;
BA_ "GenMsgCycleTime" BO_ 1338 1000;
BA_ "NmAsrMessage" BO_ 1388 1;
BA_ "NetworkInitialization" BO_ 1388 0;
BA_ "GenMsgSendType" BO_ 1388 0;
BA_ "GenMsgILSupport" BO_ 1388 0;
BA_ "GenMsgCycleTime" BO_ 1388 1000;
BA_ "NmAsrMessage" BO_ 1420 1;
BA_ "NetworkInitialization" BO_ 1420 0;
BA_ "GenMsgSendType" BO_ 1420 0;
BA_ "GenMsgILSupport" BO_ 1420 0;
BA_ "GenMsgCycleTime" BO_ 1420 1000;
BA_ "NmAsrMessage" BO_ 1425 1;
BA_ "NetworkInitialization" BO_ 1425 0;
BA_ "GenMsgSendType" BO_ 1425 0;
BA_ "GenMsgILSupport" BO_ 1425 0;
BA_ "GenMsgCycleTime" BO_ 1425 1000;
BA_ "NmAsrMessage" BO_ 1432 1;
BA_ "NetworkInitialization" BO_ 1432 0;
BA_ "GenMsgSendType" BO_ 1432 0;
BA_ "GenMsgILSupport" BO_ 1432 0;
BA_ "GenMsgCycleTime" BO_ 1432 1000;
BA_ "NmAsrMessage" BO_ 1435 1;
BA_ "NetworkInitialization" BO_ 1435 0;
BA_ "GenMsgSendType" BO_ 1435 0;
BA_ "GenMsgILSupport" BO_ 1435 0;
BA_ "GenMsgCycleTime" BO_ 1435 1000;
BA_ "NmAsrMessage" BO_ 1438 1;
BA_ "NetworkInitialization" BO_ 1438 0;
BA_ "GenMsgSendType" BO_ 1438 0;
BA_ "GenMsgILSupport" BO_ 1438 0;
BA_ "GenMsgCycleTime" BO_ 1438 1000;
BA_ "NmAsrMessage" BO_ 1439 1;
BA_ "NetworkInitialization" BO_ 1439 0;
BA_ "GenMsgSendType" BO_ 1439 0;
BA_ "GenMsgILSupport" BO_ 1439 0;
BA_ "GenMsgCycleTime" BO_ 1439 1000;
BA_ "NmAsrMessage" BO_ 1478 1;
BA_ "NetworkInitialization" BO_ 1478 0;
BA_ "GenMsgSendType" BO_ 1478 0;
BA_ "GenMsgILSupport" BO_ 1478 0;
BA_ "GenMsgCycleTime" BO_ 1478 1000;
BA_ "NmAsrMessage" BO_ 1484 1;
BA_ "NetworkInitialization" BO_ 1484 0;
BA_ "GenMsgSendType" BO_ 1484 0;
BA_ "GenMsgILSupport" BO_ 1484 0;
BA_ "GenMsgCycleTime" BO_ 1484 1000;
BA_ "NmAsrMessage" BO_ 1492 1;
BA_ "NetworkInitialization" BO_ 1492 0;
BA_ "GenMsgSendType" BO_ 1492 0;
BA_ "GenMsgILSupport" BO_ 1492 0;
BA_ "GenMsgCycleTime" BO_ 1492 1000;
BA_ "NmAsrMessage" BO_ 1500 1;
BA_ "NetworkInitialization" BO_ 1500 0;
BA_ "GenMsgSendType" BO_ 1500 0;
BA_ "GenMsgILSupport" BO_ 1500 0;
BA_ "GenMsgCycleTime" BO_ 1500 1000;
BA_ "NmAsrMessage" BO_ 1506 1;
BA_ "NetworkInitialization" BO_ 1506 0;
BA_ "GenMsgSendType" BO_ 1506 0;
BA_ "GenMsgILSupport" BO_ 1506 0;
BA_ "GenMsgCycleTime" BO_ 1506 1000;
BA_ "NetworkInitialization" BO_ 1735 0;
BA_ "GenMsgSendType" BO_ 1735 1;
BA_ "GenMsgILSupport" BO_ 1735 0;
BA_ "GenMsgDelayTime" BO_ 1735 0;
BA_ "DiagRequest" BO_ 1735 1;
BA_ "NetworkInitialization" BO_ 1743 0;
BA_ "GenMsgSendType" BO_ 1743 1;
BA_ "GenMsgILSupport" BO_ 1743 0;
BA_ "GenMsgDelayTime" BO_ 1743 0;
BA_ "DiagResponse" BO_ 1743 1;
BA_ "NetworkInitialization" BO_ 1744 0;
BA_ "GenMsgSendType" BO_ 1744 1;
BA_ "GenMsgILSupport" BO_ 1744 0;
BA_ "GenMsgDelayTime" BO_ 1744 0;
BA_ "DiagRequest" BO_ 1744 1;
BA_ "NetworkInitialization" BO_ 1752 0;
BA_ "GenMsgSendType" BO_ 1752 1;
BA_ "GenMsgILSupport" BO_ 1752 0;
BA_ "GenMsgDelayTime" BO_ 1752 0;
BA_ "DiagResponse" BO_ 1752 1;
BA_ "NetworkInitialization" BO_ 1761 0;
BA_ "GenMsgSendType" BO_ 1761 1;
BA_ "GenMsgILSupport" BO_ 1761 0;
BA_ "GenMsgDelayTime" BO_ 1761 0;
BA_ "DiagRequest" BO_ 1761 1;
BA_ "NetworkInitialization" BO_ 1769 0;
BA_ "GenMsgSendType" BO_ 1769 1;
BA_ "GenMsgILSupport" BO_ 1769 0;
BA_ "GenMsgDelayTime" BO_ 1769 0;
BA_ "DiagResponse" BO_ 1769 1;
BA_ "NetworkInitialization" BO_ 1814 0;
BA_ "GenMsgSendType" BO_ 1814 1;
BA_ "GenMsgILSupport" BO_ 1814 0;
BA_ "GenMsgDelayTime" BO_ 1814 0;
BA_ "DiagRequest" BO_ 1814 1;
BA_ "NetworkInitialization" BO_ 1822 0;
BA_ "GenMsgSendType" BO_ 1822 1;
BA_ "GenMsgILSupport" BO_ 1822 0;
BA_ "GenMsgDelayTime" BO_ 1822 0;
BA_ "DiagResponse" BO_ 1822 1;
BA_ "NetworkInitialization" BO_ 1824 0;
BA_ "GenMsgSendType" BO_ 1824 1;
BA_ "GenMsgILSupport" BO_ 1824 0;
BA_ "GenMsgDelayTime" BO_ 1824 0;
BA_ "DiagRequest" BO_ 1824 1;
BA_ "NetworkInitialization" BO_ 1829 0;
BA_ "GenMsgSendType" BO_ 1829 1;
BA_ "GenMsgILSupport" BO_ 1829 0;
BA_ "GenMsgDelayTime" BO_ 1829 0;
BA_ "DiagRequest" BO_ 1829 1;
BA_ "NetworkInitialization" BO_ 1831 0;
BA_ "GenMsgSendType" BO_ 1831 1;
BA_ "GenMsgILSupport" BO_ 1831 0;
BA_ "GenMsgDelayTime" BO_ 1831 0;
BA_ "DiagRequest" BO_ 1831 1;
BA_ "NetworkInitialization" BO_ 1832 0;
BA_ "GenMsgSendType" BO_ 1832 1;
BA_ "GenMsgILSupport" BO_ 1832 0;
BA_ "GenMsgDelayTime" BO_ 1832 0;
BA_ "DiagResponse" BO_ 1832 1;
BA_ "NetworkInitialization" BO_ 1837 0;
BA_ "GenMsgSendType" BO_ 1837 1;
BA_ "GenMsgILSupport" BO_ 1837 0;
BA_ "GenMsgDelayTime" BO_ 1837 0;
BA_ "DiagResponse" BO_ 1837 1;
BA_ "NetworkInitialization" BO_ 1839 0;
BA_ "GenMsgSendType" BO_ 1839 1;
BA_ "GenMsgILSupport" BO_ 1839 0;
BA_ "GenMsgDelayTime" BO_ 1839 0;
BA_ "DiagResponse" BO_ 1839 1;
BA_ "NetworkInitialization" BO_ 1877 0;
BA_ "GenMsgSendType" BO_ 1877 1;
BA_ "GenMsgILSupport" BO_ 1877 0;
BA_ "GenMsgDelayTime" BO_ 1877 0;
BA_ "DiagRequest" BO_ 1877 1;
BA_ "NetworkInitialization" BO_ 1879 0;
BA_ "GenMsgSendType" BO_ 1879 1;
BA_ "GenMsgILSupport" BO_ 1879 0;
BA_ "GenMsgDelayTime" BO_ 1879 0;
BA_ "DiagRequest" BO_ 1879 1;
BA_ "NetworkInitialization" BO_ 1885 0;
BA_ "GenMsgSendType" BO_ 1885 1;
BA_ "GenMsgILSupport" BO_ 1885 0;
BA_ "GenMsgDelayTime" BO_ 1885 0;
BA_ "DiagResponse" BO_ 1885 1;
BA_ "NetworkInitialization" BO_ 1908 0;
BA_ "GenMsgSendType" BO_ 1908 1;
BA_ "GenMsgILSupport" BO_ 1908 0;
BA_ "GenMsgDelayTime" BO_ 1908 0;
BA_ "DiagRequest" BO_ 1908 1;
BA_ "NetworkInitialization" BO_ 1916 0;
BA_ "GenMsgSendType" BO_ 1916 1;
BA_ "GenMsgILSupport" BO_ 1916 0;
BA_ "GenMsgDelayTime" BO_ 1916 0;
BA_ "DiagResponse" BO_ 1916 1;
BA_ "NetworkInitialization" BO_ 1923 0;
BA_ "GenMsgSendType" BO_ 1923 1;
BA_ "GenMsgILSupport" BO_ 1923 0;
BA_ "GenMsgDelayTime" BO_ 1923 0;
BA_ "DiagRequest" BO_ 1923 1;
BA_ "NetworkInitialization" BO_ 1931 0;
BA_ "GenMsgSendType" BO_ 1931 1;
BA_ "GenMsgILSupport" BO_ 1931 0;
BA_ "GenMsgDelayTime" BO_ 1931 0;
BA_ "DiagResponse" BO_ 1931 1;
BA_ "NetworkInitialization" BO_ 1937 0;
BA_ "GenMsgSendType" BO_ 1937 1;
BA_ "GenMsgILSupport" BO_ 1937 0;
BA_ "GenMsgDelayTime" BO_ 1937 0;
BA_ "DiagRequest" BO_ 1937 1;
BA_ "NetworkInitialization" BO_ 1945 0;
BA_ "GenMsgSendType" BO_ 1945 1;
BA_ "GenMsgILSupport" BO_ 1945 0;
BA_ "GenMsgDelayTime" BO_ 1945 0;
BA_ "DiagResponse" BO_ 1945 1;
BA_ "NetworkInitialization" BO_ 1952 0;
BA_ "GenMsgSendType" BO_ 1952 1;
BA_ "GenMsgILSupport" BO_ 1952 0;
BA_ "GenMsgDelayTime" BO_ 1952 0;
BA_ "DiagRequest" BO_ 1952 1;
BA_ "NetworkInitialization" BO_ 1960 0;
BA_ "GenMsgSendType" BO_ 1960 1;
BA_ "GenMsgILSupport" BO_ 1960 0;
BA_ "GenMsgDelayTime" BO_ 1960 0;
BA_ "DiagResponse" BO_ 1960 1;
BA_ "NetworkInitialization" BO_ 1968 0;
BA_ "GenMsgSendType" BO_ 1968 1;
BA_ "GenMsgILSupport" BO_ 1968 0;
BA_ "GenMsgDelayTime" BO_ 1968 0;
BA_ "DiagRequest" BO_ 1968 1;
BA_ "NetworkInitialization" BO_ 1970 0;
BA_ "GenMsgSendType" BO_ 1970 1;
BA_ "GenMsgILSupport" BO_ 1970 0;
BA_ "GenMsgDelayTime" BO_ 1970 0;
BA_ "DiagRequest" BO_ 1970 1;
BA_ "NetworkInitialization" BO_ 1976 0;
BA_ "GenMsgSendType" BO_ 1976 1;
BA_ "GenMsgILSupport" BO_ 1976 0;
BA_ "GenMsgDelayTime" BO_ 1976 0;
BA_ "DiagResponse" BO_ 1976 1;
BA_ "NetworkInitialization" BO_ 1978 0;
BA_ "GenMsgSendType" BO_ 1978 1;
BA_ "GenMsgILSupport" BO_ 1978 0;
BA_ "GenMsgDelayTime" BO_ 1978 0;
BA_ "DiagResponse" BO_ 1978 1;
BA_ "NetworkInitialization" BO_ 2000 0;
BA_ "GenMsgSendType" BO_ 2000 1;
BA_ "GenMsgILSupport" BO_ 2000 0;
BA_ "GenMsgDelayTime" BO_ 2000 0;
BA_ "DiagRequest" BO_ 2000 1;
BA_ "NetworkInitialization" BO_ 2008 0;
BA_ "GenMsgSendType" BO_ 2008 1;
BA_ "GenMsgILSupport" BO_ 2008 0;
BA_ "GenMsgDelayTime" BO_ 2008 0;
BA_ "DiagResponse" BO_ 2008 1;
BA_ "NetworkInitialization" BO_ 2015 0;
BA_ "GenMsgSendType" BO_ 2015 1;
BA_ "GenMsgILSupport" BO_ 2015 0;
BA_ "GenMsgDelayTime" BO_ 2015 0;
BA_ "DiagState" BO_ 2015 1;
BA_ "VFrameFormat" BO_ 2609912024 1;
BA_ "TpTxIndex" BO_ 2609912024 462428376;
BA_ "NetworkInitialization" BO_ 2609912024 0;
BA_ "GenMsgSendType" BO_ 2609912024 1;
BA_ "GenMsgDelayTime" BO_ 2609912024 0;
BA_ "VFrameFormat" BO_ 2609915096 1;
BA_ "TpTxIndex" BO_ 2609915096 462431448;
BA_ "GenMsgSendType" BO_ 2609915096 1;
BA_ "GenMsgDelayTime" BO_ 2609915096 0;
BA_ "VFrameFormat" BO_ 2609942744 1;
BA_ "TpTxIndex" BO_ 2609942744 462459096;
BA_ "GenMsgSendType" BO_ 2609942744 1;
BA_ "GenMsgDelayTime" BO_ 2609942744 0;
BA_ "VFrameFormat" BO_ 2609958104 1;
BA_ "TpTxIndex" BO_ 2609958104 462474456;
BA_ "GenMsgSendType" BO_ 2609958104 1;
BA_ "GenMsgDelayTime" BO_ 2609958104 0;
BA_ "VFrameFormat" BO_ 2609971416 1;
BA_ "TpTxIndex" BO_ 2609971416 462487768;
BA_ "NetworkInitialization" BO_ 2609971416 0;
BA_ "GenMsgSendType" BO_ 2609971416 1;
BA_ "GenMsgDelayTime" BO_ 2609971416 0;
BA_ "VFrameFormat" BO_ 2609991896 1;
BA_ "TpTxIndex" BO_ 2609991896 462508248;
BA_ "NetworkInitialization" BO_ 2609991896 0;
BA_ "GenMsgSendType" BO_ 2609991896 1;
BA_ "GenMsgDelayTime" BO_ 2609991896 0;
BA_ "VFrameFormat" BO_ 2610004184 1;
BA_ "TpTxIndex" BO_ 2610004184 462520536;
BA_ "NetworkInitialization" BO_ 2610004184 0;
BA_ "GenMsgSendType" BO_ 2610004184 1;
BA_ "GenMsgDelayTime" BO_ 2610004184 0;
BA_ "VFrameFormat" BO_ 2610020568 1;
BA_ "TpTxIndex" BO_ 2610020568 462536920;
BA_ "NetworkInitialization" BO_ 2610020568 0;
BA_ "GenMsgSendType" BO_ 2610020568 1;
BA_ "GenMsgDelayTime" BO_ 2610020568 0;
BA_ "VFrameFormat" BO_ 2610036952 1;
BA_ "TpTxIndex" BO_ 2610036952 462553304;
BA_ "GenMsgSendType" BO_ 2610036952 1;
BA_ "GenMsgDelayTime" BO_ 2610036952 0;
BA_ "VFrameFormat" BO_ 2610049240 1;
BA_ "TpTxIndex" BO_ 2610049240 462565592;
BA_ "NetworkInitialization" BO_ 2610049240 0;
BA_ "GenMsgSendType" BO_ 2610049240 1;
BA_ "GenMsgDelayTime" BO_ 2610049240 0;
BA_ "VFrameFormat" BO_ 2610117848 1;
BA_ "TpTxIndex" BO_ 2610117848 462634200;
BA_ "NetworkInitialization" BO_ 2610117848 0;
BA_ "GenMsgSendType" BO_ 2610117848 1;
BA_ "GenMsgDelayTime" BO_ 2610117848 0;
BA_ "VFrameFormat" BO_ 2610126854 1;
BA_ "TpTxIndex" BO_ 2610126854 462428376;
BA_ "NetworkInitialization" BO_ 2610126854 0;
BA_ "GenMsgSendType" BO_ 2610126854 1;
BA_ "GenMsgDelayTime" BO_ 2610126854 0;
BA_ "VFrameFormat" BO_ 2610126857 1;
BA_ "TpTxIndex" BO_ 2610126857 462431448;
BA_ "GenMsgSendType" BO_ 2610126857 1;
BA_ "GenMsgDelayTime" BO_ 2610126857 0;
BA_ "VFrameFormat" BO_ 2610126884 1;
BA_ "TpTxIndex" BO_ 2610126884 462459096;
BA_ "GenMsgSendType" BO_ 2610126884 1;
BA_ "GenMsgDelayTime" BO_ 2610126884 0;
BA_ "VFrameFormat" BO_ 2610126899 1;
BA_ "TpTxIndex" BO_ 2610126899 462474456;
BA_ "GenMsgSendType" BO_ 2610126899 1;
BA_ "GenMsgDelayTime" BO_ 2610126899 0;
BA_ "VFrameFormat" BO_ 2610126912 1;
BA_ "TpTxIndex" BO_ 2610126912 462487768;
BA_ "NetworkInitialization" BO_ 2610126912 0;
BA_ "GenMsgSendType" BO_ 2610126912 1;
BA_ "GenMsgDelayTime" BO_ 2610126912 0;
BA_ "VFrameFormat" BO_ 2610126932 1;
BA_ "TpTxIndex" BO_ 2610126932 462508248;
BA_ "NetworkInitialization" BO_ 2610126932 0;
BA_ "GenMsgSendType" BO_ 2610126932 1;
BA_ "GenMsgDelayTime" BO_ 2610126932 0;
BA_ "VFrameFormat" BO_ 2610126944 1;
BA_ "TpTxIndex" BO_ 2610126944 462520536;
BA_ "NetworkInitialization" BO_ 2610126944 0;
BA_ "GenMsgSendType" BO_ 2610126944 1;
BA_ "GenMsgDelayTime" BO_ 2610126944 0;
BA_ "VFrameFormat" BO_ 2610126960 1;
BA_ "TpTxIndex" BO_ 2610126960 462643312;
BA_ "NetworkInitialization" BO_ 2610126960 0;
BA_ "GenMsgSendType" BO_ 2610126960 1;
BA_ "GenMsgDelayTime" BO_ 2610126960 0;
BA_ "VFrameFormat" BO_ 2610126976 1;
BA_ "TpTxIndex" BO_ 2610126976 462553304;
BA_ "GenMsgSendType" BO_ 2610126976 1;
BA_ "GenMsgDelayTime" BO_ 2610126976 0;
BA_ "VFrameFormat" BO_ 2610126988 1;
BA_ "TpTxIndex" BO_ 2610126988 462565592;
BA_ "NetworkInitialization" BO_ 2610126988 0;
BA_ "GenMsgSendType" BO_ 2610126988 1;
BA_ "GenMsgDelayTime" BO_ 2610126988 0;
BA_ "VFrameFormat" BO_ 2610127055 1;
BA_ "TpTxIndex" BO_ 2610127055 462634200;
BA_ "NetworkInitialization" BO_ 2610127055 0;
BA_ "GenMsgSendType" BO_ 2610127055 1;
BA_ "GenMsgDelayTime" BO_ 2610127055 0;
BA_ "VFrameFormat" BO_ 2610953432 1;
BA_ "TpTxIndex" BO_ 2610953432 463469784;
BA_ "NetworkInitialization" BO_ 2610953432 0;
BA_ "GenMsgSendType" BO_ 2610953432 1;
BA_ "GenMsgDelayTime" BO_ 2610953432 0;
BA_ "VFrameFormat" BO_ 2610960600 1;
BA_ "TpTxIndex" BO_ 2610960600 463476952;
BA_ "NetworkInitialization" BO_ 2610960600 0;
BA_ "GenMsgSendType" BO_ 2610960600 1;
BA_ "GenMsgDelayTime" BO_ 2610960600 0;
BA_ "VFrameFormat" BO_ 2610963672 1;
BA_ "TpTxIndex" BO_ 2610963672 463480024;
BA_ "GenMsgSendType" BO_ 2610963672 1;
BA_ "GenMsgDelayTime" BO_ 2610963672 0;
BA_ "VFrameFormat" BO_ 2610991320 1;
BA_ "TpTxIndex" BO_ 2610991320 463507672;
BA_ "GenMsgSendType" BO_ 2610991320 1;
BA_ "GenMsgDelayTime" BO_ 2610991320 0;
BA_ "VFrameFormat" BO_ 2611006680 1;
BA_ "TpTxIndex" BO_ 2611006680 463523032;
BA_ "GenMsgSendType" BO_ 2611006680 1;
BA_ "GenMsgDelayTime" BO_ 2611006680 0;
BA_ "VFrameFormat" BO_ 2611019992 1;
BA_ "TpTxIndex" BO_ 2611019992 463536344;
BA_ "NetworkInitialization" BO_ 2611019992 0;
BA_ "GenMsgSendType" BO_ 2611019992 1;
BA_ "GenMsgDelayTime" BO_ 2611019992 0;
BA_ "VFrameFormat" BO_ 2611040472 1;
BA_ "TpTxIndex" BO_ 2611040472 463556824;
BA_ "NetworkInitialization" BO_ 2611040472 0;
BA_ "GenMsgSendType" BO_ 2611040472 1;
BA_ "GenMsgDelayTime" BO_ 2611040472 0;
BA_ "VFrameFormat" BO_ 2611052760 1;
BA_ "TpTxIndex" BO_ 2611052760 463569112;
BA_ "NetworkInitialization" BO_ 2611052760 0;
BA_ "GenMsgSendType" BO_ 2611052760 1;
BA_ "GenMsgDelayTime" BO_ 2611052760 0;
BA_ "VFrameFormat" BO_ 2611069144 1;
BA_ "TpTxIndex" BO_ 2611069144 463585496;
BA_ "NetworkInitialization" BO_ 2611069144 0;
BA_ "GenMsgSendType" BO_ 2611069144 1;
BA_ "GenMsgDelayTime" BO_ 2611069144 0;
BA_ "VFrameFormat" BO_ 2611085528 1;
BA_ "TpTxIndex" BO_ 2611085528 463601880;
BA_ "GenMsgSendType" BO_ 2611085528 1;
BA_ "GenMsgDelayTime" BO_ 2611085528 0;
BA_ "VFrameFormat" BO_ 2611097816 1;
BA_ "TpTxIndex" BO_ 2611097816 463614168;
BA_ "NetworkInitialization" BO_ 2611097816 0;
BA_ "GenMsgSendType" BO_ 2611097816 1;
BA_ "GenMsgDelayTime" BO_ 2611097816 0;
BA_ "VFrameFormat" BO_ 2611166424 1;
BA_ "TpTxIndex" BO_ 2611166424 463682776;
BA_ "NetworkInitialization" BO_ 2611166424 0;
BA_ "GenMsgSendType" BO_ 2611166424 1;
BA_ "GenMsgDelayTime" BO_ 2611166424 0;
BA_ "VFrameFormat" BO_ 2611175430 1;
BA_ "TpTxIndex" BO_ 2611175430 463476952;
BA_ "NetworkInitialization" BO_ 2611175430 0;
BA_ "GenMsgSendType" BO_ 2611175430 1;
BA_ "GenMsgDelayTime" BO_ 2611175430 0;
BA_ "VFrameFormat" BO_ 2611175433 1;
BA_ "TpTxIndex" BO_ 2611175433 463480024;
BA_ "GenMsgSendType" BO_ 2611175433 1;
BA_ "GenMsgDelayTime" BO_ 2611175433 0;
BA_ "VFrameFormat" BO_ 2611175460 1;
BA_ "TpTxIndex" BO_ 2611175460 463507672;
BA_ "GenMsgSendType" BO_ 2611175460 1;
BA_ "GenMsgDelayTime" BO_ 2611175460 0;
BA_ "VFrameFormat" BO_ 2611175475 1;
BA_ "TpTxIndex" BO_ 2611175475 463523032;
BA_ "GenMsgSendType" BO_ 2611175475 1;
BA_ "GenMsgDelayTime" BO_ 2611175475 0;
BA_ "VFrameFormat" BO_ 2611175488 1;
BA_ "TpTxIndex" BO_ 2611175488 463536344;
BA_ "NetworkInitialization" BO_ 2611175488 0;
BA_ "GenMsgSendType" BO_ 2611175488 1;
BA_ "GenMsgDelayTime" BO_ 2611175488 0;
BA_ "VFrameFormat" BO_ 2611175508 1;
BA_ "TpTxIndex" BO_ 2611175508 463556824;
BA_ "NetworkInitialization" BO_ 2611175508 0;
BA_ "GenMsgSendType" BO_ 2611175508 1;
BA_ "GenMsgDelayTime" BO_ 2611175508 0;
BA_ "VFrameFormat" BO_ 2611175520 1;
BA_ "TpTxIndex" BO_ 2611175520 463569112;
BA_ "NetworkInitialization" BO_ 2611175520 0;
BA_ "GenMsgSendType" BO_ 2611175520 1;
BA_ "GenMsgDelayTime" BO_ 2611175520 0;
BA_ "VFrameFormat" BO_ 2611175536 1;
BA_ "TpTxIndex" BO_ 2611175536 463691888;
BA_ "NetworkInitialization" BO_ 2611175536 0;
BA_ "GenMsgSendType" BO_ 2611175536 1;
BA_ "GenMsgDelayTime" BO_ 2611175536 0;
BA_ "VFrameFormat" BO_ 2611175552 1;
BA_ "TpTxIndex" BO_ 2611175552 463601880;
BA_ "GenMsgSendType" BO_ 2611175552 1;
BA_ "GenMsgDelayTime" BO_ 2611175552 0;
BA_ "VFrameFormat" BO_ 2611175564 1;
BA_ "TpTxIndex" BO_ 2611175564 463614168;
BA_ "NetworkInitialization" BO_ 2611175564 0;
BA_ "GenMsgSendType" BO_ 2611175564 1;
BA_ "GenMsgDelayTime" BO_ 2611175564 0;
BA_ "VFrameFormat" BO_ 2611175631 1;
BA_ "TpTxIndex" BO_ 2611175631 463682776;
BA_ "NetworkInitialization" BO_ 2611175631 0;
BA_ "GenMsgSendType" BO_ 2611175631 1;
BA_ "GenMsgDelayTime" BO_ 2611175631 0;
BA_ "VFrameFormat" BO_ 2612002008 1;
BA_ "TpTxIndex" BO_ 2612002008 464518360;
BA_ "NetworkInitialization" BO_ 2612002008 0;
BA_ "GenMsgSendType" BO_ 2612002008 1;
BA_ "GenMsgDelayTime" BO_ 2612002008 0;
BA_ "VFrameFormat" BO_ 2612009176 1;
BA_ "TpTxIndex" BO_ 2612009176 464525528;
BA_ "OvtpPushApplication" BO_ 2612009176 1;
BA_ "NetworkInitialization" BO_ 2612009176 0;
BA_ "GenMsgSendType" BO_ 2612009176 1;
BA_ "GenMsgDelayTime" BO_ 2612009176 0;
BA_ "VFrameFormat" BO_ 2612012248 1;
BA_ "TpTxIndex" BO_ 2612012248 464528600;
BA_ "OvtpPushApplication" BO_ 2612012248 1;
BA_ "GenMsgSendType" BO_ 2612012248 1;
BA_ "GenMsgDelayTime" BO_ 2612012248 0;
BA_ "VFrameFormat" BO_ 2612039896 1;
BA_ "TpTxIndex" BO_ 2612039896 464556248;
BA_ "OvtpPushApplication" BO_ 2612039896 1;
BA_ "GenMsgSendType" BO_ 2612039896 1;
BA_ "GenMsgDelayTime" BO_ 2612039896 0;
BA_ "VFrameFormat" BO_ 2612055256 1;
BA_ "TpTxIndex" BO_ 2612055256 464571608;
BA_ "OvtpPushApplication" BO_ 2612055256 1;
BA_ "GenMsgSendType" BO_ 2612055256 1;
BA_ "GenMsgDelayTime" BO_ 2612055256 0;
BA_ "SystemMessageLongSymbol" BO_ 2612055256 "PARSEDPushFcGWM_ECGtoMRCMB_RDAPM_HS3";
BA_ "VFrameFormat" BO_ 2612068568 1;
BA_ "TpTxIndex" BO_ 2612068568 464584920;
BA_ "OvtpPushApplication" BO_ 2612068568 1;
BA_ "NetworkInitialization" BO_ 2612068568 0;
BA_ "GenMsgSendType" BO_ 2612068568 1;
BA_ "GenMsgDelayTime" BO_ 2612068568 0;
BA_ "VFrameFormat" BO_ 2612089048 1;
BA_ "TpTxIndex" BO_ 2612089048 464605400;
BA_ "OvtpPushApplication" BO_ 2612089048 1;
BA_ "NetworkInitialization" BO_ 2612089048 0;
BA_ "GenMsgSendType" BO_ 2612089048 1;
BA_ "GenMsgDelayTime" BO_ 2612089048 0;
BA_ "VFrameFormat" BO_ 2612101336 1;
BA_ "TpTxIndex" BO_ 2612101336 464617688;
BA_ "OvtpPushApplication" BO_ 2612101336 1;
BA_ "NetworkInitialization" BO_ 2612101336 0;
BA_ "GenMsgSendType" BO_ 2612101336 1;
BA_ "GenMsgDelayTime" BO_ 2612101336 0;
BA_ "VFrameFormat" BO_ 2612117720 1;
BA_ "TpTxIndex" BO_ 2612117720 464634072;
BA_ "OvtpPushApplication" BO_ 2612117720 1;
BA_ "NetworkInitialization" BO_ 2612117720 0;
BA_ "GenMsgSendType" BO_ 2612117720 1;
BA_ "GenMsgDelayTime" BO_ 2612117720 0;
BA_ "VFrameFormat" BO_ 2612134104 1;
BA_ "TpTxIndex" BO_ 2612134104 464650456;
BA_ "OvtpPushApplication" BO_ 2612134104 1;
BA_ "GenMsgSendType" BO_ 2612134104 1;
BA_ "GenMsgDelayTime" BO_ 2612134104 0;
BA_ "VFrameFormat" BO_ 2612146392 1;
BA_ "TpTxIndex" BO_ 2612146392 464662744;
BA_ "OvtpPushApplication" BO_ 2612146392 1;
BA_ "NetworkInitialization" BO_ 2612146392 0;
BA_ "GenMsgSendType" BO_ 2612146392 1;
BA_ "GenMsgDelayTime" BO_ 2612146392 0;
BA_ "VFrameFormat" BO_ 2612215000 1;
BA_ "TpTxIndex" BO_ 2612215000 464731352;
BA_ "OvtpPushApplication" BO_ 2612215000 1;
BA_ "NetworkInitialization" BO_ 2612215000 0;
BA_ "GenMsgSendType" BO_ 2612215000 1;
BA_ "GenMsgDelayTime" BO_ 2612215000 0;
BA_ "VFrameFormat" BO_ 2612224006 1;
BA_ "TpTxIndex" BO_ 2612224006 464525528;
BA_ "OvtpPushApplication" BO_ 2612224006 1;
BA_ "NetworkInitialization" BO_ 2612224006 0;
BA_ "GenMsgSendType" BO_ 2612224006 1;
BA_ "GenMsgDelayTime" BO_ 2612224006 0;
BA_ "VFrameFormat" BO_ 2612224009 1;
BA_ "TpTxIndex" BO_ 2612224009 464528600;
BA_ "OvtpPushApplication" BO_ 2612224009 1;
BA_ "GenMsgSendType" BO_ 2612224009 1;
BA_ "GenMsgDelayTime" BO_ 2612224009 0;
BA_ "VFrameFormat" BO_ 2612224036 1;
BA_ "TpTxIndex" BO_ 2612224036 464556248;
BA_ "OvtpPushApplication" BO_ 2612224036 1;
BA_ "GenMsgSendType" BO_ 2612224036 1;
BA_ "GenMsgDelayTime" BO_ 2612224036 0;
BA_ "VFrameFormat" BO_ 2612224051 1;
BA_ "TpTxIndex" BO_ 2612224051 464571608;
BA_ "OvtpPushApplication" BO_ 2612224051 1;
BA_ "GenMsgSendType" BO_ 2612224051 1;
BA_ "GenMsgDelayTime" BO_ 2612224051 0;
BA_ "SystemMessageLongSymbol" BO_ 2612224051 "PARSEDPushMRCMB_RDAPM_HS3toGWM_ECG";
BA_ "VFrameFormat" BO_ 2612224064 1;
BA_ "TpTxIndex" BO_ 2612224064 464584920;
BA_ "OvtpPushApplication" BO_ 2612224064 1;
BA_ "NetworkInitialization" BO_ 2612224064 0;
BA_ "GenMsgSendType" BO_ 2612224064 1;
BA_ "GenMsgDelayTime" BO_ 2612224064 0;
BA_ "VFrameFormat" BO_ 2612224084 1;
BA_ "TpTxIndex" BO_ 2612224084 464605400;
BA_ "OvtpPushApplication" BO_ 2612224084 1;
BA_ "NetworkInitialization" BO_ 2612224084 0;
BA_ "GenMsgSendType" BO_ 2612224084 1;
BA_ "GenMsgDelayTime" BO_ 2612224084 0;
BA_ "VFrameFormat" BO_ 2612224096 1;
BA_ "TpTxIndex" BO_ 2612224096 464617688;
BA_ "OvtpPushApplication" BO_ 2612224096 1;
BA_ "GenMsgSendType" BO_ 2612224096 1;
BA_ "GenMsgDelayTime" BO_ 2612224096 0;
BA_ "VFrameFormat" BO_ 2612224112 1;
BA_ "TpTxIndex" BO_ 2612224112 464740464;
BA_ "OvtpPushApplication" BO_ 2612224112 1;
BA_ "NetworkInitialization" BO_ 2612224112 0;
BA_ "GenMsgSendType" BO_ 2612224112 1;
BA_ "GenMsgDelayTime" BO_ 2612224112 0;
BA_ "VFrameFormat" BO_ 2612224128 1;
BA_ "TpTxIndex" BO_ 2612224128 464650456;
BA_ "OvtpPushApplication" BO_ 2612224128 1;
BA_ "GenMsgSendType" BO_ 2612224128 1;
BA_ "GenMsgDelayTime" BO_ 2612224128 0;
BA_ "VFrameFormat" BO_ 2612224140 1;
BA_ "TpTxIndex" BO_ 2612224140 464662744;
BA_ "OvtpPushApplication" BO_ 2612224140 1;
BA_ "NetworkInitialization" BO_ 2612224140 0;
BA_ "GenMsgSendType" BO_ 2612224140 1;
BA_ "GenMsgDelayTime" BO_ 2612224140 0;
BA_ "VFrameFormat" BO_ 2612224207 1;
BA_ "TpTxIndex" BO_ 2612224207 464731352;
BA_ "OvtpPushApplication" BO_ 2612224207 1;
BA_ "NetworkInitialization" BO_ 2612224207 0;
BA_ "GenMsgSendType" BO_ 2612224207 1;
BA_ "GenMsgDelayTime" BO_ 2612224207 0;
BA_ "VFrameFormat" BO_ 2613060824 1;
BA_ "TpTxIndex" BO_ 2613060824 465577176;
BA_ "GenMsgSendType" BO_ 2613060824 1;
BA_ "GenMsgDelayTime" BO_ 2613060824 0;
BA_ "VFrameFormat" BO_ 2613103832 1;
BA_ "TpTxIndex" BO_ 2613103832 465620184;
BA_ "GenMsgSendType" BO_ 2613103832 1;
BA_ "GenMsgDelayTime" BO_ 2613103832 0;
BA_ "SystemMessageLongSymbol" BO_ 2613103832 "SymKeyPhysGWM_ECGtoMRCMB_RDAPM_HS3";
BA_ "VFrameFormat" BO_ 2613182680 1;
BA_ "TpTxIndex" BO_ 2613182680 465699032;
BA_ "GenMsgSendType" BO_ 2613182680 1;
BA_ "GenMsgDelayTime" BO_ 2613182680 0;
BA_ "VFrameFormat" BO_ 2613194968 1;
BA_ "TpTxIndex" BO_ 2613194968 465711320;
BA_ "NetworkInitialization" BO_ 2613194968 0;
BA_ "GenMsgSendType" BO_ 2613194968 1;
BA_ "GenMsgDelayTime" BO_ 2613194968 0;
BA_ "VFrameFormat" BO_ 2613263576 1;
BA_ "TpTxIndex" BO_ 2613263576 465779928;
BA_ "NetworkInitialization" BO_ 2613263576 0;
BA_ "GenMsgSendType" BO_ 2613263576 1;
BA_ "GenMsgDelayTime" BO_ 2613263576 0;
BA_ "VFrameFormat" BO_ 2613272585 1;
BA_ "TpTxIndex" BO_ 2613272585 465577176;
BA_ "GenMsgSendType" BO_ 2613272585 1;
BA_ "GenMsgDelayTime" BO_ 2613272585 0;
BA_ "VFrameFormat" BO_ 2613272627 1;
BA_ "TpTxIndex" BO_ 2613272627 465620184;
BA_ "GenMsgSendType" BO_ 2613272627 1;
BA_ "GenMsgDelayTime" BO_ 2613272627 0;
BA_ "SystemMessageLongSymbol" BO_ 2613272627 "SymKeyPhysMRCMB_RDAPM_HS3toGWM_ECG";
BA_ "VFrameFormat" BO_ 2613272704 1;
BA_ "TpTxIndex" BO_ 2613272704 465699032;
BA_ "GenMsgSendType" BO_ 2613272704 1;
BA_ "GenMsgDelayTime" BO_ 2613272704 0;
BA_ "VFrameFormat" BO_ 2613272716 1;
BA_ "TpTxIndex" BO_ 2613272716 465711320;
BA_ "NetworkInitialization" BO_ 2613272716 0;
BA_ "GenMsgSendType" BO_ 2613272716 1;
BA_ "GenMsgDelayTime" BO_ 2613272716 0;
BA_ "VFrameFormat" BO_ 2613272783 1;
BA_ "TpTxIndex" BO_ 2613272783 465779928;
BA_ "NetworkInitialization" BO_ 2613272783 0;
BA_ "GenMsgSendType" BO_ 2613272783 1;
BA_ "GenMsgDelayTime" BO_ 2613272783 0;
BA_ "VFrameFormat" BO_ 2614099160 1;
BA_ "TpTxIndex" BO_ 2614099160 466615512;
BA_ "NetworkInitialization" BO_ 2614099160 0;
BA_ "GenMsgSendType" BO_ 2614099160 1;
BA_ "GenMsgDelayTime" BO_ 2614099160 0;
BA_ "GenSigStartValue" SG_ 1152 StopStrtVThres_D_Stat 1;
BA_ "GenSigStartValue" SG_ 1152 VehElEff_No_Avg 126;
BA_ "GenSigStartValue" SG_ 1152 DcacLoFuelLim_L_PwRsrv 510;
BA_ "GenSigSendType" SG_ 1155 WshrLvlFrontTop_B_Stat 3;
BA_ "GenSigSendType" SG_ 1155 WshrLvlFront_B_Falt 3;
BA_ "GenSigSendType" SG_ 1155 WshrLvlFrontBttm_B_Stat 3;
BA_ "GenSigSendType" SG_ 1155 WshrLvlRearTop_B_Stat 3;
BA_ "GenSigSendType" SG_ 1155 WshrLvlRearBttm_B_Stat 3;
BA_ "GenSigSendType" SG_ 1155 WshrLvlRear_B_Falt 3;
BA_ "GenSigStartValue" SG_ 1156 VehElEffAvg_No_Dsply 126;
BA_ "GenSigStartValue" SG_ 1156 RngPerChrgAvg_L2_Dsply 8190;
BA_ "GenSigStartValue" SG_ 1159 SecondRowBuckleMid2 1;
BA_ "GenSigStartValue" SG_ 1159 SecondRowBuckleDriver2 1;
BA_ "GenSigStartValue" SG_ 1159 ThirdRowBuckleDriver2 1;
BA_ "GenSigStartValue" SG_ 1159 SecondRowBucklePsngr2 1;
BA_ "GenSigStartValue" SG_ 1159 ThirdRowBucklePsngr2 1;
BA_ "GenSigStartValue" SG_ 1159 ThirdRowBuckleMid2 1;
BA_ "GenSigStartValue" SG_ 1159 FourthRowBuckleMid2 1;
BA_ "GenSigStartValue" SG_ 1159 FourthRowBuckleDriver2 1;
BA_ "GenSigStartValue" SG_ 1159 FourthRowBucklePsngr2 1;
BA_ "GenSigStartValue" SG_ 1161 BattTracCellCnt_No_Actl 254;
BA_ "GenSigStartValue" SG_ 1161 BattTracCellUMn_No_Actl 254;
BA_ "GenSigStartValue" SG_ 1161 BattTracTeCnt_No_Actl 254;
BA_ "GenSigStartValue" SG_ 1161 BattTracTeMn_No_Actl 254;
BA_ "GenSigStartValue" SG_ 1161 BattTracTeMx_No_Actl 254;
BA_ "GenSigStartValue" SG_ 1161 BattTracUMxArry_No_Actl 31;
BA_ "GenSigStartValue" SG_ 1161 BattTracCellUMx_No_Actl 254;
BA_ "WakeupSignal" SG_ 1163 DrSwtchInnrFl_No_Rq 1;
BA_ "WakeupSignal" SG_ 1164 DrSwtchInnrFr_No_Rq 1;
BA_ "GenSigSendType" SG_ 1184 APIM_TCU_Word_Rx 3;
BA_ "ECGUsedRxSignal" SG_ 1185 TCU_MC_WORD_Rx 1;
BA_ "GenSigStartValue" SG_ 1186 SelDrvMdeAwd2_D_Stat 31;
BA_ "GenSigStartValue" SG_ 1186 FrontDiffLck_Tq_Actl 16382;
BA_ "GenSigSendType" SG_ 1187 TCU_RDISP2_WORD_Tx 3;
BA_ "ECGUsedTxSignal" SG_ 1187 TCU_RDISP2_WORD_Tx 1;
BA_ "ECGUsedRxSignal" SG_ 1188 OPTIN_MC_WORD_Rx 1;
BA_ "GenSigSendType" SG_ 1192 APIM_TCU_Word_Tx 3;
BA_ "ECGUsedRxSignal" SG_ 1192 APIM_TCU_Word_Tx 1;
BA_ "GenSigSendType" SG_ 1195 TCU_RDISP2_WORD_Rx 3;
BA_ "ECGUsedRxSignal" SG_ 1195 TCU_RDISP2_WORD_Rx 1;
BA_ "GenSigStartValue" SG_ 1200 BrkBstrVac_P_Actl 127;
BA_ "GenSigSendType" SG_ 1203 ApnlNameTxt01_No_Actl 3;
BA_ "ECGUsedTxSignal" SG_ 1203 ApnlNameTxt01_No_Actl 1;
BA_ "GenSigSendType" SG_ 1203 ApnlNameTxt02_No_Actl 3;
BA_ "ECGUsedTxSignal" SG_ 1203 ApnlNameTxt02_No_Actl 1;
BA_ "GenSigSendType" SG_ 1203 ApnlNameTxt03_No_Actl 3;
BA_ "ECGUsedTxSignal" SG_ 1203 ApnlNameTxt03_No_Actl 1;
BA_ "GenSigSendType" SG_ 1203 ApnlNameTxt04_No_Actl 3;
BA_ "ECGUsedTxSignal" SG_ 1203 ApnlNameTxt04_No_Actl 1;
BA_ "GenSigSendType" SG_ 1203 ApnlNameTxt05_No_Actl 3;
BA_ "ECGUsedTxSignal" SG_ 1203 ApnlNameTxt05_No_Actl 1;
BA_ "GenSigSendType" SG_ 1203 ApnlNameTxt06_No_Actl 3;
BA_ "ECGUsedTxSignal" SG_ 1203 ApnlNameTxt06_No_Actl 1;
BA_ "GenSigSendType" SG_ 1203 ApnlNameTxt07_No_Actl 3;
BA_ "ECGUsedTxSignal" SG_ 1203 ApnlNameTxt07_No_Actl 1;
BA_ "GenSigSendType" SG_ 1203 ApnlNameTxt08_No_Actl 3;
BA_ "ECGUsedTxSignal" SG_ 1203 ApnlNameTxt08_No_Actl 1;
BA_ "GenSigStartValue" SG_ 1205 CstmDrvMde1_No_Confg2 15;
BA_ "GenSigStartValue" SG_ 1205 CstmDrvMde1_No_Confg1 15;
BA_ "GenSigStartValue" SG_ 1205 CstmDrvMde2_No_Confg2 15;
BA_ "GenSigStartValue" SG_ 1205 CstmDrvMde2_No_Confg1 15;
BA_ "GenSigStartValue" SG_ 1205 CstmDrvMde3_No_Confg2 15;
BA_ "GenSigStartValue" SG_ 1205 CstmDrvMde3_No_Confg1 15;
BA_ "GenSigStartValue" SG_ 1205 CstmDrvMde4_No_Confg2 15;
BA_ "GenSigStartValue" SG_ 1205 CstmDrvMde4_No_Confg1 15;
BA_ "GenSigStartValue" SG_ 1205 CstmDrvMde5_No_Confg2 15;
BA_ "GenSigStartValue" SG_ 1205 CstmDrvMde5_No_Confg1 15;
BA_ "GenSigStartValue" SG_ 1205 CstmDrvMde_No_Confg1 63;
BA_ "GenSigStartValue" SG_ 1205 CstmDrvMde_No_Confg2 63;
BA_ "GenSigSendType" SG_ 1208 StopStrtImccSel_B_Falt 3;
BA_ "GenSigStartValue" SG_ 1208 Btt_L2_Actl2 124;
BA_ "GenSigSendType" SG_ 1208 Btt_L2_Actl2 3;
BA_ "GenSigSendType" SG_ 1208 WiprFrontActv_D_Rq 3;
BA_ "GenSigSendType" SG_ 1208 WshrFrontActv_B_Rq 3;
BA_ "GenSigSendType" SG_ 1208 StopStrtImccSel_B_Rq 3;
BA_ "GenSigSendType" SG_ 1208 StopStrtImccTxt_D_Stat 3;
BA_ "GenSigSendType" SG_ 1208 TjaAutoLcEnbl_D_RqMnu 3;
BA_ "GenSigSendType" SG_ 1208 IpwEnbl_D_RqMnu 3;
BA_ "ECGUsedRxSignal" SG_ 1208 IpwEnbl_D_RqMnu 1;
BA_ "GenSigSendType" SG_ 1208 EngStrtChimeSet_D_Rq 3;
BA_ "ECGUsedRxSignal" SG_ 1208 IpwSocMn_Pc_RqMnu 1;
BA_ "GenSigSendType" SG_ 1211 E_Voice_Blower_Limit 3;
BA_ "GenSigSendType" SG_ 1211 E_Frt_Blwr_Speed 3;
BA_ "GenSigSendType" SG_ 1211 E_Drv_Set_Temp 3;
BA_ "GenSigStartValue" SG_ 1211 FrtBlwr_An_Actl 511;
BA_ "GenSigSendType" SG_ 1211 FrtBlwr_An_Actl 3;
BA_ "GenSigSendType" SG_ 1211 E_Frt_Btn_Status_1st 3;
BA_ "GenSigStartValue" SG_ 1211 FrtTe_An_Actl 511;
BA_ "GenSigSendType" SG_ 1211 FrtTe_An_Actl 3;
BA_ "GenSigSendType" SG_ 1211 E_Frt_Btn_Status_2nd 3;
BA_ "GenSigSendType" SG_ 1211 E_Rr_Btn_Status_1st 3;
BA_ "GenSigSendType" SG_ 1211 E_Rr_Btn_Status_2nd 3;
BA_ "GenSigStartValue" SG_ 1212 LostPKChirp_D_Stat 3;
BA_ "WakeupSignal" SG_ 1212 DelvrAsstFeat_D_Stat 1;
BA_ "WakeupSignal" SG_ 1212 KeyFobEvnt_D_Stat 1;
BA_ "WakeupSignal" SG_ 1212 DelvrAsstExtndWak_D_Rq 1;
BA_ "WakeupSignal" SG_ 1216 SldrlUnlck_No_Cnt 1;
BA_ "WakeupSignal" SG_ 1216 SldrlChildLck_No_Cnt 1;
BA_ "WakeupSignal" SG_ 1216 Sldrl_D_Stat 1;
BA_ "WakeupSignal" SG_ 1216 SldrlMsgTxt_D2_Rq 1;
BA_ "WakeupSignal" SG_ 1216 SldrlChime_D_Rq 1;
BA_ "WakeupSignal" SG_ 1216 DrSwtchExtRl_No_Rq 1;
BA_ "WakeupSignal" SG_ 1216 DrSwtchInnrRl_No_Rq 1;
BA_ "WakeupSignal" SG_ 1217 SldrrUnlck_No_Cnt 1;
BA_ "WakeupSignal" SG_ 1217 SldrrChildLck_No_Cnt 1;
BA_ "WakeupSignal" SG_ 1217 Sldrr_D_Stat 1;
BA_ "WakeupSignal" SG_ 1217 SldrrMsgTxt_D2_Rq 1;
BA_ "WakeupSignal" SG_ 1217 SldrrChime_D_Rq 1;
BA_ "WakeupSignal" SG_ 1217 DrSwtchExtRr_No_Rq 1;
BA_ "WakeupSignal" SG_ 1217 DrSwtchInnrRr_No_Rq 1;
BA_ "GenSigSendType" SG_ 1223 DrDrv_No_Crc 3;
BA_ "GenSigSendType" SG_ 1223 DrDrv_No_Cnt 3;
BA_ "GenSigSendType" SG_ 1223 MrorAutoSavDrv_D_Stat 3;
BA_ "GenSigSendType" SG_ 1223 DrvWndwAutoOprt_D_Stat 3;
BA_ "GenSigStartValue" SG_ 1223 DrDrv_UNUSED_1bit_1 1;
BA_ "GenSigSendType" SG_ 1223 ChildLckFdbkRd2_B_Stat 3;
BA_ "GenSigSendType" SG_ 1223 DrChildLckDrv_No_Rq 3;
BA_ "GenSigSendType" SG_ 1223 DrSwtchExtDrv_No_Rq 3;
BA_ "GenSigStartValue" SG_ 1223 DrDrv_UNUSED_8bit_1 255;
BA_ "GenSigStartValue" SG_ 1223 DrDrv_UNUSED_8bit_2 255;
BA_ "GenSigStartValue" SG_ 1223 DrDrv_UNUSED_8bit_3 255;
BA_ "GenSigStartValue" SG_ 1223 DrDrv_UNUSED_8bit_4 255;
BA_ "GenSigStartValue" SG_ 1223 DrDrv_UNUSED_8bit_5 255;
BA_ "GenSigStartValue" SG_ 1224 DrPsngr_UNUSED_7bit_1 127;
BA_ "GenSigStartValue" SG_ 1224 DrPsngr_UNUSED_8bit_1 255;
BA_ "GenSigStartValue" SG_ 1224 DrPsngr_UNUSED_8bit_2 255;
BA_ "GenSigStartValue" SG_ 1224 DrPsngr_UNUSED_8bit_3 255;
BA_ "GenSigStartValue" SG_ 1224 DrPsngr_UNUSED_8bit_4 255;
BA_ "GenSigStartValue" SG_ 1224 DrPsngr_UNUSED_8bit_5 255;
BA_ "GenSigStartValue" SG_ 1225 RgstrHzntlObl_An_Actl 30;
BA_ "GenSigStartValue" SG_ 1225 RgstrHzntlIbl_An_Actl 30;
BA_ "GenSigStartValue" SG_ 1225 RgstrHzntlObr_An_Actl 30;
BA_ "GenSigStartValue" SG_ 1225 RgstrHzntlIbr_An_Actl 30;
BA_ "GenSigStartValue" SG_ 1225 RgstrVertObl_An_Actl 75;
BA_ "GenSigStartValue" SG_ 1225 RgstrVertIbl_An_Actl 75;
BA_ "GenSigStartValue" SG_ 1225 RgstrVertObr_An_Actl 75;
BA_ "GenSigStartValue" SG_ 1225 RgstrVertIbr_An_Actl 75;
BA_ "GenSigStartValue" SG_ 1235 ApaSlotFrontY_L_Actl 32;
BA_ "GenSigStartValue" SG_ 1236 ApaSlotRearY_L_Actl 32;
BA_ "GenSigSendType" SG_ 1238 OraAutoActv_D_Rq 3;
BA_ "GenSigStartValue" SG_ 1238 Fba_D_Stat 1;
BA_ "GenSigSendType" SG_ 1239 CstmDrvMdeTracCtl_D_Rq 3;
BA_ "ECGUsedTxSignal" SG_ 1239 CstmDrvMdeTracCtl_D_Rq 1;
BA_ "GenSigSendType" SG_ 1239 SeatOccRearChime_B_Rq 3;
BA_ "ECGUsedTxSignal" SG_ 1239 SeatOccRearChime_B_Rq 1;
BA_ "GenSigStartValue" SG_ 1239 ActvDrvMdeCstm_D2_Rq 31;
BA_ "GenSigSendType" SG_ 1239 ActvDrvMdeCstm_D2_Rq 3;
BA_ "ECGUsedTxSignal" SG_ 1239 ActvDrvMdeCstm_D2_Rq 1;
BA_ "GenSigStartValue" SG_ 1239 IndvMdeSteCstm_No_Rq 15;
BA_ "GenSigSendType" SG_ 1239 IndvMdeSteCstm_No_Rq 3;
BA_ "ECGUsedTxSignal" SG_ 1239 IndvMdeSteCstm_No_Rq 1;
BA_ "GenSigSendType" SG_ 1239 CstmDrvMdeMsgTxt_D_Rq 3;
BA_ "ECGUsedTxSignal" SG_ 1239 CstmDrvMdeMsgTxt_D_Rq 1;
BA_ "GenSigSendType" SG_ 1239 StabBarCnnctLamp_D_Cstm 3;
BA_ "ECGUsedTxSignal" SG_ 1239 StabBarCnnctLamp_D_Cstm 1;
BA_ "GenSigSendType" SG_ 1239 SelDrvMdeCstmLamp_D_Rq 3;
BA_ "ECGUsedTxSignal" SG_ 1239 SelDrvMdeCstmLamp_D_Rq 1;
BA_ "GenSigSendType" SG_ 1239 CstmDrvMdePrfl_No_Actl 3;
BA_ "ECGUsedTxSignal" SG_ 1239 CstmDrvMdePrfl_No_Actl 1;
BA_ "GenSigStartValue" SG_ 1239 CstmDrvMdeHmi2_D_Rq 31;
BA_ "GenSigSendType" SG_ 1239 CstmDrvMdeHmi2_D_Rq 3;
BA_ "ECGUsedTxSignal" SG_ 1239 CstmDrvMdeHmi2_D_Rq 1;
BA_ "GenSigSendType" SG_ 1239 CstmDrvMdeChassis_D_Rq 3;
BA_ "ECGUsedTxSignal" SG_ 1239 CstmDrvMdeChassis_D_Rq 1;
BA_ "GenSigSendType" SG_ 1239 SelDrvMdeCstm_D_RqDrv 3;
BA_ "ECGUsedTxSignal" SG_ 1239 SelDrvMdeCstm_D_RqDrv 1;
BA_ "GenSigStartValue" SG_ 1239 IndvMdeSuspCstm_No_Rq 15;
BA_ "GenSigSendType" SG_ 1239 IndvMdeSuspCstm_No_Rq 3;
BA_ "ECGUsedTxSignal" SG_ 1239 IndvMdeSuspCstm_No_Rq 1;
BA_ "GenSigSendType" SG_ 1242 SelDrvMdeCstmPt_D_Rq 3;
BA_ "ECGUsedTxSignal" SG_ 1242 SelDrvMdeCstmPt_D_Rq 1;
BA_ "GenSigSendType" SG_ 1242 EngExhMdeQuietCstm_D_Rq 3;
BA_ "ECGUsedTxSignal" SG_ 1242 EngExhMdeQuietCstm_D_Rq 1;
BA_ "GenSigSendType" SG_ 1242 StopStrtCstm_D_Rq 3;
BA_ "ECGUsedTxSignal" SG_ 1242 StopStrtCstm_D_Rq 1;
BA_ "GenSigStartValue" SG_ 1245 SelDrvMdeAwd2_D_Cstm 31;
BA_ "GenSigSendType" SG_ 1245 SelDrvMdeAwd2_D_Cstm 3;
BA_ "ECGUsedTxSignal" SG_ 1245 SelDrvMdeAwd2_D_Cstm 1;
BA_ "GenSigSendType" SG_ 1245 AwdMdeCstm_D_RqDrv 3;
BA_ "ECGUsedTxSignal" SG_ 1245 AwdMdeCstm_D_RqDrv 1;
BA_ "GenSigStartValue" SG_ 1245 SndPersIndx_D_Rq 4;
BA_ "GenSigSendType" SG_ 1245 SndPersIndx_D_Rq 3;
BA_ "ECGUsedTxSignal" SG_ 1245 SndPersIndx_D_Rq 1;
BA_ "GenSigSendType" SG_ 1245 RearDiffLckLamp_D_Cstm 3;
BA_ "ECGUsedTxSignal" SG_ 1245 RearDiffLckLamp_D_Cstm 1;
BA_ "GenSigSendType" SG_ 1245 FrontDiffLckLamp_D_Cstm 3;
BA_ "ECGUsedTxSignal" SG_ 1245 FrontDiffLckLamp_D_Cstm 1;
BA_ "GenSigSendType" SG_ 1245 SndPersFeat_No_Rq 3;
BA_ "ECGUsedTxSignal" SG_ 1245 SndPersFeat_No_Rq 1;
BA_ "GenSigSendType" SG_ 1245 SndPersFeatVal_No_Rq 3;
BA_ "ECGUsedTxSignal" SG_ 1245 SndPersFeatVal_No_Rq 1;
BA_ "GenSigSendType" SG_ 1245 SndPersSrvcId_No_Rq 3;
BA_ "ECGUsedTxSignal" SG_ 1245 SndPersSrvcId_No_Rq 1;
BA_ "GenSigSendType" SG_ 1245 SndPersSrvc_D_Rq 3;
BA_ "ECGUsedTxSignal" SG_ 1245 SndPersSrvc_D_Rq 1;
BA_ "GenSigSendType" SG_ 1246 TrlrBrkCtl2_B_Falt 3;
BA_ "GenSigStartValue" SG_ 1259 RgstrHzntlObl_An_Rq 30;
BA_ "GenSigSendType" SG_ 1259 RgstrHzntlObl_An_Rq 3;
BA_ "GenSigStartValue" SG_ 1259 RgstrHzntlIbl_An_Rq 30;
BA_ "GenSigSendType" SG_ 1259 RgstrHzntlIbl_An_Rq 3;
BA_ "GenSigStartValue" SG_ 1259 RgstrHzntlObr_An_Rq 30;
BA_ "GenSigSendType" SG_ 1259 RgstrHzntlObr_An_Rq 3;
BA_ "GenSigStartValue" SG_ 1259 RgstrHzntlIbr_An_Rq 30;
BA_ "GenSigSendType" SG_ 1259 RgstrHzntlIbr_An_Rq 3;
BA_ "GenSigStartValue" SG_ 1259 RgstrVertObl_An_Rq 75;
BA_ "GenSigSendType" SG_ 1259 RgstrVertObl_An_Rq 3;
BA_ "GenSigStartValue" SG_ 1259 RgstrVertIbl_An_Rq 75;
BA_ "GenSigSendType" SG_ 1259 RgstrVertIbl_An_Rq 3;
BA_ "GenSigStartValue" SG_ 1259 RgstrVertObr_An_Rq 75;
BA_ "GenSigSendType" SG_ 1259 RgstrVertObr_An_Rq 3;
BA_ "GenSigStartValue" SG_ 1259 RgstrVertIbr_An_Rq 75;
BA_ "GenSigSendType" SG_ 1259 RgstrVertIbr_An_Rq 3;
BA_ "GenSigSendType" SG_ 1261 StmsAutoSavDrv_D_Stat 3;
BA_ "GenSigStartValue" SG_ 1262 CabnScent1Life_Pc_Actl 127;
BA_ "GenSigStartValue" SG_ 1262 CabnScent2Life_Pc_Actl 127;
BA_ "GenSigStartValue" SG_ 1262 CabnScent3Life_Pc_Actl 127;
BA_ "GenSigStartValue" SG_ 1262 CabnScent4Life_Pc_Actl 127;
BA_ "GenSigStartValue" SG_ 1262 CabnScent5Life_Pc_Actl 127;
BA_ "GenSigSendType" SG_ 1266 CabnScentCalbType_No_Rq 3;
BA_ "GenSigSendType" SG_ 1266 SafePetTempSet_D_Rq 3;
BA_ "GenSigSendType" SG_ 1266 CabnScentCalibVal_No_Rq 3;
BA_ "GenSigSendType" SG_ 1270 UpftrElementId_No_Rq 3;
BA_ "GenSigStartValue" SG_ 1337 WCMB_AutoSarNMNodeId 57;
BA_ "GenSigStartValue" SG_ 1337 WCMB_AutoSarNMReserved1 255;
BA_ "GenSigStartValue" SG_ 1337 WCMB_AutoSarNMReserved2 255;
BA_ "GenSigStartValue" SG_ 1337 WCMB_GWOnBoardTester 255;
BA_ "GenSigStartValue" SG_ 1337 WCMB_GWNMProxy 255;
BA_ "GenSigStartValue" SG_ 1337 WCMB_AutoSarNMReserved3 255;
BA_ "GenSigStartValue" SG_ 1337 WCMB_AutoSarNMReserved4 255;
BA_ "GenSigStartValue" SG_ 1338 WCMC_AutoSarNMNodeId 58;
BA_ "GenSigStartValue" SG_ 1338 WCMC_AutoSarNMReserved1 255;
BA_ "GenSigStartValue" SG_ 1338 WCMC_AutoSarNMReserved2 255;
BA_ "GenSigStartValue" SG_ 1338 WCMC_GWOnBoardTester 255;
BA_ "GenSigStartValue" SG_ 1338 WCMC_GWNMProxy 255;
BA_ "GenSigStartValue" SG_ 1338 WCMC_AutoSarNMReserved3 255;
BA_ "GenSigStartValue" SG_ 1338 WCMC_AutoSarNMReserved4 255;
BA_ "GenSigStartValue" SG_ 1388 ESPM_AutoSarNMNodeId 108;
BA_ "GenSigStartValue" SG_ 1388 ESPM_AutoSarNMReserved1 255;
BA_ "GenSigStartValue" SG_ 1388 ESPM_AutoSarNMReserved2 255;
BA_ "GenSigStartValue" SG_ 1388 ESPM_GWOnBoardTester 255;
BA_ "GenSigStartValue" SG_ 1388 ESPM_GWNMProxy 255;
BA_ "GenSigStartValue" SG_ 1388 ESPM_AutoSarNMReserved3 255;
BA_ "GenSigStartValue" SG_ 1388 ESPM_AutoSarNMReserved4 255;
BA_ "GenSigStartValue" SG_ 1420 ACM_AutoSarNMNodeId 140;
BA_ "ECGUsedRxSignal" SG_ 1420 ACM_AutoSarNMNodeId 1;
BA_ "ECGUsedRxSignal" SG_ 1420 ACM_AutoSarNMControl 1;
BA_ "GenSigStartValue" SG_ 1420 ACM_AutoSarNMReserved1 255;
BA_ "ECGUsedRxSignal" SG_ 1420 ACM_AutoSarNMReserved1 1;
BA_ "GenSigStartValue" SG_ 1420 ACM_AutoSarNMReserved2 255;
BA_ "ECGUsedRxSignal" SG_ 1420 ACM_AutoSarNMReserved2 1;
BA_ "GenSigStartValue" SG_ 1420 ACM_GWOnBoardTester 255;
BA_ "ECGUsedRxSignal" SG_ 1420 ACM_GWOnBoardTester 1;
BA_ "GenSigStartValue" SG_ 1420 ACM_GWNMProxy 255;
BA_ "ECGUsedRxSignal" SG_ 1420 ACM_GWNMProxy 1;
BA_ "GenSigStartValue" SG_ 1420 ACM_AutoSarNMReserved3 255;
BA_ "ECGUsedRxSignal" SG_ 1420 ACM_AutoSarNMReserved3 1;
BA_ "GenSigStartValue" SG_ 1420 ACM_AutoSarNMReserved4 255;
BA_ "ECGUsedRxSignal" SG_ 1420 ACM_AutoSarNMReserved4 1;
BA_ "GenSigStartValue" SG_ 1425 IPC_AutoSarNMNodeId 145;
BA_ "ECGUsedRxSignal" SG_ 1425 IPC_AutoSarNMNodeId 1;
BA_ "ECGUsedRxSignal" SG_ 1425 IPC_AutoSarNMControl 1;
BA_ "GenSigStartValue" SG_ 1425 IPC_AutoSarNMReserved1 255;
BA_ "ECGUsedRxSignal" SG_ 1425 IPC_AutoSarNMReserved1 1;
BA_ "GenSigStartValue" SG_ 1425 IPC_AutoSarNMReserved2 255;
BA_ "ECGUsedRxSignal" SG_ 1425 IPC_AutoSarNMReserved2 1;
BA_ "GenSigStartValue" SG_ 1425 IPC_GWOnBoardTester 255;
BA_ "ECGUsedRxSignal" SG_ 1425 IPC_GWOnBoardTester 1;
BA_ "GenSigStartValue" SG_ 1425 IPC_GWNMProxy 255;
BA_ "ECGUsedRxSignal" SG_ 1425 IPC_GWNMProxy 1;
BA_ "GenSigStartValue" SG_ 1425 IPC_AutoSarNMReserved3 255;
BA_ "ECGUsedRxSignal" SG_ 1425 IPC_AutoSarNMReserved3 1;
BA_ "GenSigStartValue" SG_ 1425 IPC_AutoSarNMReserved4 255;
BA_ "ECGUsedRxSignal" SG_ 1425 IPC_AutoSarNMReserved4 1;
BA_ "GenSigStartValue" SG_ 1432 RACM_RCIM_AutoSarNMNodeId 152;
BA_ "ECGUsedRxSignal" SG_ 1432 RACM_RCIM_AutoSarNMNodeId 1;
BA_ "ECGUsedRxSignal" SG_ 1432 RACM_RCIM_AutoSarNMControl 1;
BA_ "GenSigStartValue" SG_ 1432 RACM_RCIM_AutoSarNMReserved1 255;
BA_ "ECGUsedRxSignal" SG_ 1432 RACM_RCIM_AutoSarNMReserved1 1;
BA_ "GenSigStartValue" SG_ 1432 RACM_RCIM_AutoSarNMReserved2 255;
BA_ "ECGUsedRxSignal" SG_ 1432 RACM_RCIM_AutoSarNMReserved2 1;
BA_ "GenSigStartValue" SG_ 1432 RACM_RCIM_GWOnBoardTester 255;
BA_ "ECGUsedRxSignal" SG_ 1432 RACM_RCIM_GWOnBoardTester 1;
BA_ "GenSigStartValue" SG_ 1432 RACM_RCIM_GWNMProxy 255;
BA_ "ECGUsedRxSignal" SG_ 1432 RACM_RCIM_GWNMProxy 1;
BA_ "GenSigStartValue" SG_ 1432 RACM_RCIM_AutoSarNMReserved3 255;
BA_ "ECGUsedRxSignal" SG_ 1432 RACM_RCIM_AutoSarNMReserved3 1;
BA_ "GenSigStartValue" SG_ 1432 RACM_RCIM_AutoSarNMReserved4 255;
BA_ "ECGUsedRxSignal" SG_ 1432 RACM_RCIM_AutoSarNMReserved4 1;
BA_ "GenSigStartValue" SG_ 1435 HUD_ADV_AutoSarNMNodeId 155;
BA_ "ECGUsedRxSignal" SG_ 1435 HUD_ADV_AutoSarNMNodeId 1;
BA_ "ECGUsedRxSignal" SG_ 1435 HUD_ADV_AutoSarNMControl 1;
BA_ "GenSigStartValue" SG_ 1435 HUD_ADV_AutoSarNMReserved1 255;
BA_ "ECGUsedRxSignal" SG_ 1435 HUD_ADV_AutoSarNMReserved1 1;
BA_ "GenSigStartValue" SG_ 1435 HUD_ADV_AutoSarNMReserved2 255;
BA_ "ECGUsedRxSignal" SG_ 1435 HUD_ADV_AutoSarNMReserved2 1;
BA_ "GenSigStartValue" SG_ 1435 HUD_ADV_GWOnBoardTester 255;
BA_ "ECGUsedRxSignal" SG_ 1435 HUD_ADV_GWOnBoardTester 1;
BA_ "GenSigStartValue" SG_ 1435 HUD_ADV_GWNMProxy 255;
BA_ "ECGUsedRxSignal" SG_ 1435 HUD_ADV_GWNMProxy 1;
BA_ "GenSigStartValue" SG_ 1435 HUD_ADV_AutoSarNMReserved3 255;
BA_ "ECGUsedRxSignal" SG_ 1435 HUD_ADV_AutoSarNMReserved3 1;
BA_ "GenSigStartValue" SG_ 1435 HUD_ADV_AutoSarNMReserved4 255;
BA_ "ECGUsedRxSignal" SG_ 1435 HUD_ADV_AutoSarNMReserved4 1;
BA_ "GenSigStartValue" SG_ 1438 GWM_AutoSarNMNodeId 158;
BA_ "ECGUsedTxSignal" SG_ 1438 GWM_AutoSarNMNodeId 1;
BA_ "ECGUsedTxSignal" SG_ 1438 GWM_AutoSarNMControl 1;
BA_ "GenSigStartValue" SG_ 1438 GWM_AutoSarNMReserved1 255;
BA_ "ECGUsedTxSignal" SG_ 1438 GWM_AutoSarNMReserved1 1;
BA_ "GenSigStartValue" SG_ 1438 GWM_AutoSarNMReserved2 255;
BA_ "ECGUsedTxSignal" SG_ 1438 GWM_AutoSarNMReserved2 1;
BA_ "GenSigStartValue" SG_ 1438 GWM_GWOnBoardTester 255;
BA_ "ECGUsedTxSignal" SG_ 1438 GWM_GWOnBoardTester 1;
BA_ "GenSigStartValue" SG_ 1438 GWM_GWNMProxy 255;
BA_ "ECGUsedTxSignal" SG_ 1438 GWM_GWNMProxy 1;
BA_ "GenSigStartValue" SG_ 1438 GWM_AutoSarNMReserved3 255;
BA_ "ECGUsedTxSignal" SG_ 1438 GWM_AutoSarNMReserved3 1;
BA_ "GenSigStartValue" SG_ 1438 GWM_AutoSarNMReserved4 255;
BA_ "ECGUsedTxSignal" SG_ 1438 GWM_AutoSarNMReserved4 1;
BA_ "GenSigStartValue" SG_ 1439 WCM_AutoSarNMNodeId 159;
BA_ "GenSigStartValue" SG_ 1439 WCM_AutoSarNMReserved1 255;
BA_ "GenSigStartValue" SG_ 1439 WCM_AutoSarNMReserved2 255;
BA_ "GenSigStartValue" SG_ 1439 WCM_GWOnBoardTester 255;
BA_ "GenSigStartValue" SG_ 1439 WCM_GWNMProxy 255;
BA_ "GenSigStartValue" SG_ 1439 WCM_AutoSarNMReserved3 255;
BA_ "GenSigStartValue" SG_ 1439 WCM_AutoSarNMReserved4 255;
BA_ "GenSigStartValue" SG_ 1478 DSP_AutoSarNMNodeId 198;
BA_ "GenSigStartValue" SG_ 1478 DSP_AutoSarNMReserved1 255;
BA_ "GenSigStartValue" SG_ 1478 DSP_AutoSarNMReserved2 255;
BA_ "GenSigStartValue" SG_ 1478 DSP_GWOnBoardTester 255;
BA_ "GenSigStartValue" SG_ 1478 DSP_GWNMProxy 255;
BA_ "GenSigStartValue" SG_ 1478 DSP_AutoSarNMReserved3 255;
BA_ "GenSigStartValue" SG_ 1478 DSP_AutoSarNMReserved4 255;
BA_ "GenSigStartValue" SG_ 1484 MRCMB_RDAPM_HS3_AutoSarNMNodeId 204;
BA_ "GenSigStartValue" SG_ 1484 MRCMB_RDAPM_HS3_AutoSarNMReserve 255;
BA_ "SystemSignalLongSymbol" SG_ 1484 MRCMB_RDAPM_HS3_AutoSarNMReserve "MRCMB_RDAPM_HS3_AutoSarNMReserved1";
BA_ "GenSigStartValue" SG_ 1484 MRCMB_RDAPM_HS3_AutoSarNMRe_0000 255;
BA_ "SystemSignalLongSymbol" SG_ 1484 MRCMB_RDAPM_HS3_AutoSarNMRe_0000 "MRCMB_RDAPM_HS3_AutoSarNMReserved2";
BA_ "GenSigStartValue" SG_ 1484 MRCMB_RDAPM_HS3_GWOnBoardTester 255;
BA_ "GenSigStartValue" SG_ 1484 MRCMB_RDAPM_HS3_GWNMProxy 255;
BA_ "GenSigStartValue" SG_ 1484 MRCMB_RDAPM_HS3_AutoSarNMRe_0001 255;
BA_ "SystemSignalLongSymbol" SG_ 1484 MRCMB_RDAPM_HS3_AutoSarNMRe_0001 "MRCMB_RDAPM_HS3_AutoSarNMReserved3";
BA_ "GenSigStartValue" SG_ 1484 MRCMB_RDAPM_HS3_AutoSarNMRe_0002 255;
BA_ "SystemSignalLongSymbol" SG_ 1484 MRCMB_RDAPM_HS3_AutoSarNMRe_0002 "MRCMB_RDAPM_HS3_AutoSarNMReserved4";
BA_ "GenSigStartValue" SG_ 1492 TRM_ITRM_AutoSarNMNodeId 212;
BA_ "GenSigStartValue" SG_ 1492 TRM_ITRM_AutoSarNMReserved1 255;
BA_ "GenSigStartValue" SG_ 1492 TRM_ITRM_AutoSarNMReserved2 255;
BA_ "GenSigStartValue" SG_ 1492 TRM_ITRM_GWOnBoardTester 255;
BA_ "GenSigStartValue" SG_ 1492 TRM_ITRM_GWNMProxy 255;
BA_ "GenSigStartValue" SG_ 1492 TRM_ITRM_AutoSarNMReserved3 255;
BA_ "GenSigStartValue" SG_ 1492 TRM_ITRM_AutoSarNMReserved4 255;
BA_ "GenSigStartValue" SG_ 1500 ARM_AutoSarNMNodeId 220;
BA_ "GenSigStartValue" SG_ 1500 ARM_AutoSarNMReserved1 255;
BA_ "GenSigStartValue" SG_ 1500 ARM_AutoSarNMReserved2 255;
BA_ "GenSigStartValue" SG_ 1500 ARM_GWOnBoardTester 255;
BA_ "GenSigStartValue" SG_ 1500 ARM_GWNMProxy 255;
BA_ "GenSigStartValue" SG_ 1500 ARM_AutoSarNMReserved3 255;
BA_ "GenSigStartValue" SG_ 1500 ARM_AutoSarNMReserved4 255;
BA_ "GenSigStartValue" SG_ 1506 APIM_CDC_AutoSarNMNodeId 226;
BA_ "GenSigStartValue" SG_ 1506 APIM_CDC_AutoSarNMReserved1 255;
BA_ "GenSigStartValue" SG_ 1506 APIM_CDC_AutoSarNMReserved2 255;
BA_ "GenSigStartValue" SG_ 1506 APIM_CDC_GWOnBoardTester 255;
BA_ "GenSigStartValue" SG_ 1506 APIM_CDC_GWNMProxy 255;
BA_ "GenSigStartValue" SG_ 1506 APIM_CDC_AutoSarNMReserved3 255;
BA_ "GenSigStartValue" SG_ 1506 APIM_CDC_AutoSarNMReserved4 255;
BA_ "GenSigSendType" SG_ 1735 TesterPhysicalReqWCMB 3;
BA_ "GenSigSendType" SG_ 1743 TesterPhysicalResWCMB 3;
BA_ "GenSigSendType" SG_ 1744 TesterPhysicalReqWCMC 3;
BA_ "GenSigSendType" SG_ 1752 TesterPhysicalResWCMC 3;
BA_ "GenSigSendType" SG_ 1761 TesterPhysicalReqESPM 3;
BA_ "GenSigSendType" SG_ 1769 TesterPhysicalResESPM 3;
BA_ "GenSigSendType" SG_ 1814 TesterPhysicalReqGWM_H3 3;
BA_ "ECGUsedRxSignal" SG_ 1814 TesterPhysicalReqGWM_H3 1;
BA_ "GenSigSendType" SG_ 1822 TesterPhysicalResGWM 3;
BA_ "ECGUsedTxSignal" SG_ 1822 TesterPhysicalResGWM 1;
BA_ "GenSigSendType" SG_ 1824 TesterPhysicalReqIPC 3;
BA_ "GenSigSendType" SG_ 1829 TesterPhysicalReqWCM 3;
BA_ "GenSigSendType" SG_ 1831 TesterPhysicalReqACM 3;
BA_ "GenSigSendType" SG_ 1832 TesterPhysicalResIPC 3;
BA_ "GenSigSendType" SG_ 1837 TesterPhysicalResWCM 3;
BA_ "GenSigSendType" SG_ 1839 TesterPhysicalResACM 3;
BA_ "GenSigSendType" SG_ 1877 TesterPhysicalReqARM 3;
BA_ "GenSigSendType" SG_ 1879 TesterPhysicalReqTBM 3;
BA_ "GenSigSendType" SG_ 1885 TesterPhysicalResARM 3;
BA_ "GenSigSendType" SG_ 1908 TesterPhysicalReqRACM 3;
BA_ "GenSigSendType" SG_ 1916 TesterPhysicalResRACM 3;
BA_ "GenSigSendType" SG_ 1923 TesterPhysicalReqDSP 3;
BA_ "GenSigSendType" SG_ 1931 TesterPhysicalResDSP 3;
BA_ "GenSigSendType" SG_ 1937 TesterPhysicalReqTRM_ITRM 3;
BA_ "GenSigSendType" SG_ 1945 TesterPhysicalResTRM_ITRM 3;
BA_ "GenSigSendType" SG_ 1952 TesterPhysicalReqFCIMB 3;
BA_ "GenSigSendType" SG_ 1960 TesterPhysicalResFCIMB 3;
BA_ "GenSigSendType" SG_ 1968 TesterPhysicalReqRDAPM_20 3;
BA_ "GenSigSendType" SG_ 1970 TesterPhysicalReqHUD_ADV 3;
BA_ "GenSigSendType" SG_ 1976 TesterPhysicalResRDAPM_20 3;
BA_ "GenSigSendType" SG_ 1978 TesterPhysicalResHUD_ADV 3;
BA_ "GenSigSendType" SG_ 2000 TesterPhysicalReqAPIM 3;
BA_ "GenSigSendType" SG_ 2008 TesterPhysicalResAPIM 3;
BA_ "GenSigSendType" SG_ 2015 TesterFunctionalReq 3;
BA_ "ECGUsedRxSignal" SG_ 2015 TesterFunctionalReq 1;
BA_ "GenSigSendType" SG_ 2609912024 OTAPhysGWM_ECGtoHUD 3;
BA_ "ECGUsedTxSignal" SG_ 2609912024 OTAPhysGWM_ECGtoHUD 1;
BA_ "GenSigSendType" SG_ 2609915096 OTAPhysGWM_ECGtoDSP 3;
BA_ "ECGUsedTxSignal" SG_ 2609915096 OTAPhysGWM_ECGtoDSP 1;
BA_ "GenSigSendType" SG_ 2609942744 OTAPhysGWM_ECGtoTRM_ITRM 3;
BA_ "ECGUsedTxSignal" SG_ 2609942744 OTAPhysGWM_ECGtoTRM_ITRM 1;
BA_ "GenSigSendType" SG_ 2609958104 OTAPhysGWM_ECGtoMRCMB_RDAPM 3;
BA_ "ECGUsedTxSignal" SG_ 2609958104 OTAPhysGWM_ECGtoMRCMB_RDAPM 1;
BA_ "GenSigSendType" SG_ 2609971416 OTAPhysGWM_ECGtoWCM 3;
BA_ "ECGUsedTxSignal" SG_ 2609971416 OTAPhysGWM_ECGtoWCM 1;
BA_ "GenSigSendType" SG_ 2609991896 OTAPhysGWM_ECGtoWCMC 3;
BA_ "ECGUsedTxSignal" SG_ 2609991896 OTAPhysGWM_ECGtoWCMC 1;
BA_ "GenSigSendType" SG_ 2610004184 OTAPhysGWM_ECGtoIPC 3;
BA_ "ECGUsedTxSignal" SG_ 2610004184 OTAPhysGWM_ECGtoIPC 1;
BA_ "GenSigSendType" SG_ 2610020568 OTAPhysGWM_ECGtoWCMB 3;
BA_ "ECGUsedTxSignal" SG_ 2610020568 OTAPhysGWM_ECGtoWCMB 1;
BA_ "GenSigSendType" SG_ 2610036952 OTAPhysGWM_ECGtoACM 3;
BA_ "ECGUsedTxSignal" SG_ 2610036952 OTAPhysGWM_ECGtoACM 1;
BA_ "GenSigSendType" SG_ 2610049240 OTAPhysGWM_ECGtoRACM 3;
BA_ "ECGUsedTxSignal" SG_ 2610049240 OTAPhysGWM_ECGtoRACM 1;
BA_ "GenSigSendType" SG_ 2610117848 OTAPhysGWM_ECGtoESPM 3;
BA_ "ECGUsedTxSignal" SG_ 2610117848 OTAPhysGWM_ECGtoESPM 1;
BA_ "GenSigSendType" SG_ 2610126854 OTAPhysHUDtoGWM_ECG 3;
BA_ "ECGUsedRxSignal" SG_ 2610126854 OTAPhysHUDtoGWM_ECG 1;
BA_ "GenSigSendType" SG_ 2610126857 OTAPhysDSPtoGWM_ECG 3;
BA_ "ECGUsedRxSignal" SG_ 2610126857 OTAPhysDSPtoGWM_ECG 1;
BA_ "GenSigSendType" SG_ 2610126884 OTAPhysTRM_ITRMtoGWM_ECG 3;
BA_ "ECGUsedRxSignal" SG_ 2610126884 OTAPhysTRM_ITRMtoGWM_ECG 1;
BA_ "GenSigSendType" SG_ 2610126899 OTAPhysMRCMB_RDAPMtoGWM_ECG 3;
BA_ "ECGUsedRxSignal" SG_ 2610126899 OTAPhysMRCMB_RDAPMtoGWM_ECG 1;
BA_ "GenSigSendType" SG_ 2610126912 OTAPhysWCMtoGWM_ECG 3;
BA_ "ECGUsedRxSignal" SG_ 2610126912 OTAPhysWCMtoGWM_ECG 1;
BA_ "GenSigSendType" SG_ 2610126932 OTAPhysWCMCtoGWM_ECG 3;
BA_ "ECGUsedRxSignal" SG_ 2610126932 OTAPhysWCMCtoGWM_ECG 1;
BA_ "GenSigSendType" SG_ 2610126944 OTAPhysIPCtoGWM_ECG 3;
BA_ "ECGUsedRxSignal" SG_ 2610126944 OTAPhysIPCtoGWM_ECG 1;
BA_ "GenSigSendType" SG_ 2610126960 OTAPhysWCMBtoGWM_ECG 3;
BA_ "ECGUsedRxSignal" SG_ 2610126960 OTAPhysWCMBtoGWM_ECG 1;
BA_ "GenSigSendType" SG_ 2610126976 OTAPhysACMtoGWM_ECG 3;
BA_ "ECGUsedRxSignal" SG_ 2610126976 OTAPhysACMtoGWM_ECG 1;
BA_ "GenSigSendType" SG_ 2610126988 OTAPhysRACMtoGWM_ECG 3;
BA_ "ECGUsedRxSignal" SG_ 2610126988 OTAPhysRACMtoGWM_ECG 1;
BA_ "GenSigSendType" SG_ 2610127055 OTAPhysESPMtoGWM_ECG 3;
BA_ "ECGUsedRxSignal" SG_ 2610127055 OTAPhysESPMtoGWM_ECG 1;
BA_ "GenSigSendType" SG_ 2610953432 OTAFuncGWM_ECG 3;
BA_ "ECGUsedTxSignal" SG_ 2610953432 OTAFuncGWM_ECG 1;
BA_ "GenSigSendType" SG_ 2610960600 PARSEDPhysGWM_ECGtoHUD 3;
BA_ "ECGUsedTxSignal" SG_ 2610960600 PARSEDPhysGWM_ECGtoHUD 1;
BA_ "GenSigSendType" SG_ 2610963672 PARSEDPhysGWM_ECGtoDSP 3;
BA_ "ECGUsedTxSignal" SG_ 2610963672 PARSEDPhysGWM_ECGtoDSP 1;
BA_ "GenSigSendType" SG_ 2610991320 PARSEDPhysGWM_ECGtoTRM_ITRM 3;
BA_ "ECGUsedTxSignal" SG_ 2610991320 PARSEDPhysGWM_ECGtoTRM_ITRM 1;
BA_ "GenSigSendType" SG_ 2611006680 PARSEDPhysGWM_ECGtoMRCMB_RDAPM 3;
BA_ "ECGUsedTxSignal" SG_ 2611006680 PARSEDPhysGWM_ECGtoMRCMB_RDAPM 1;
BA_ "GenSigSendType" SG_ 2611019992 PARSEDPhysGWM_ECGtoWCM 3;
BA_ "ECGUsedTxSignal" SG_ 2611019992 PARSEDPhysGWM_ECGtoWCM 1;
BA_ "GenSigSendType" SG_ 2611040472 PARSEDPhysGWM_ECGtoWCMC 3;
BA_ "ECGUsedTxSignal" SG_ 2611040472 PARSEDPhysGWM_ECGtoWCMC 1;
BA_ "GenSigSendType" SG_ 2611052760 PARSEDPhysGWM_ECGtoIPC 3;
BA_ "ECGUsedTxSignal" SG_ 2611052760 PARSEDPhysGWM_ECGtoIPC 1;
BA_ "GenSigSendType" SG_ 2611069144 PARSEDPhysGWM_ECGtoWCMB 3;
BA_ "ECGUsedTxSignal" SG_ 2611069144 PARSEDPhysGWM_ECGtoWCMB 1;
BA_ "GenSigSendType" SG_ 2611085528 PARSEDPhysGWM_ECGtoACM 3;
BA_ "ECGUsedTxSignal" SG_ 2611085528 PARSEDPhysGWM_ECGtoACM 1;
BA_ "GenSigSendType" SG_ 2611097816 PARSEDPhysGWM_ECGtoRACM 3;
BA_ "ECGUsedTxSignal" SG_ 2611097816 PARSEDPhysGWM_ECGtoRACM 1;
BA_ "GenSigSendType" SG_ 2611166424 PARSEDPhysGWM_ECGtoESPM 3;
BA_ "ECGUsedTxSignal" SG_ 2611166424 PARSEDPhysGWM_ECGtoESPM 1;
BA_ "GenSigSendType" SG_ 2611175430 PARSEDPhysHUDtoGWM_ECG 3;
BA_ "ECGUsedRxSignal" SG_ 2611175430 PARSEDPhysHUDtoGWM_ECG 1;
BA_ "GenSigSendType" SG_ 2611175433 PARSEDPhysDSPtoGWM_ECG 3;
BA_ "ECGUsedRxSignal" SG_ 2611175433 PARSEDPhysDSPtoGWM_ECG 1;
BA_ "GenSigSendType" SG_ 2611175460 PARSEDPhysTRM_ITRMtoGWM_ECG 3;
BA_ "ECGUsedRxSignal" SG_ 2611175460 PARSEDPhysTRM_ITRMtoGWM_ECG 1;
BA_ "GenSigSendType" SG_ 2611175475 PARSEDPhysMRCMB_RDAPMtoGWM_ECG 3;
BA_ "ECGUsedRxSignal" SG_ 2611175475 PARSEDPhysMRCMB_RDAPMtoGWM_ECG 1;
BA_ "GenSigSendType" SG_ 2611175488 PARSEDPhysWCMtoGWM_ECG 3;
BA_ "ECGUsedRxSignal" SG_ 2611175488 PARSEDPhysWCMtoGWM_ECG 1;
BA_ "GenSigSendType" SG_ 2611175508 PARSEDPhysWCMCtoGWM_ECG 3;
BA_ "ECGUsedRxSignal" SG_ 2611175508 PARSEDPhysWCMCtoGWM_ECG 1;
BA_ "GenSigSendType" SG_ 2611175520 PARSEDPhysIPCtoGWM_ECG 3;
BA_ "ECGUsedRxSignal" SG_ 2611175520 PARSEDPhysIPCtoGWM_ECG 1;
BA_ "GenSigSendType" SG_ 2611175536 PARSEDPhysWCMBtoGWM_ECG 3;
BA_ "ECGUsedRxSignal" SG_ 2611175536 PARSEDPhysWCMBtoGWM_ECG 1;
BA_ "GenSigSendType" SG_ 2611175552 PARSEDPhysACMtoGWM_ECG 3;
BA_ "ECGUsedRxSignal" SG_ 2611175552 PARSEDPhysACMtoGWM_ECG 1;
BA_ "GenSigSendType" SG_ 2611175564 PARSEDPhysRACMtoGWM_ECG 3;
BA_ "ECGUsedRxSignal" SG_ 2611175564 PARSEDPhysRACMtoGWM_ECG 1;
BA_ "GenSigSendType" SG_ 2611175631 PARSEDPhysESPMtoGWM_ECG 3;
BA_ "ECGUsedRxSignal" SG_ 2611175631 PARSEDPhysESPMtoGWM_ECG 1;
BA_ "GenSigSendType" SG_ 2612002008 PARSEDFuncGWM_ECG 3;
BA_ "ECGUsedTxSignal" SG_ 2612002008 PARSEDFuncGWM_ECG 1;
BA_ "GenSigSendType" SG_ 2612009176 PARSEDPushFcGWM_ECGtoHUD 3;
BA_ "ECGUsedTxSignal" SG_ 2612009176 PARSEDPushFcGWM_ECGtoHUD 1;
BA_ "GenSigSendType" SG_ 2612012248 PARSEDPushFcGWM_ECGtoDSP 3;
BA_ "ECGUsedTxSignal" SG_ 2612012248 PARSEDPushFcGWM_ECGtoDSP 1;
BA_ "GenSigSendType" SG_ 2612039896 PARSEDPushFcGWM_ECGtoTRM_ITRM 3;
BA_ "ECGUsedTxSignal" SG_ 2612039896 PARSEDPushFcGWM_ECGtoTRM_ITRM 1;
BA_ "GenSigSendType" SG_ 2612055256 PARSEDPushFcGWM_ECGtoMRCMB_RDAPM 3;
BA_ "ECGUsedTxSignal" SG_ 2612055256 PARSEDPushFcGWM_ECGtoMRCMB_RDAPM 1;
BA_ "GenSigSendType" SG_ 2612068568 PARSEDPushFcGWM_ECGtoWCM 3;
BA_ "ECGUsedTxSignal" SG_ 2612068568 PARSEDPushFcGWM_ECGtoWCM 1;
BA_ "GenSigSendType" SG_ 2612089048 PARSEDPushFcGWM_ECGtoWCMC 3;
BA_ "ECGUsedTxSignal" SG_ 2612089048 PARSEDPushFcGWM_ECGtoWCMC 1;
BA_ "GenSigSendType" SG_ 2612101336 PARSEDPushFcGWM_ECGtoIPC 3;
BA_ "ECGUsedTxSignal" SG_ 2612101336 PARSEDPushFcGWM_ECGtoIPC 1;
BA_ "GenSigSendType" SG_ 2612117720 PARSEDPushFcGWM_ECGtoWCMB 3;
BA_ "ECGUsedTxSignal" SG_ 2612117720 PARSEDPushFcGWM_ECGtoWCMB 1;
BA_ "GenSigSendType" SG_ 2612134104 PARSEDPushFcGWM_ECGtoACM 3;
BA_ "ECGUsedTxSignal" SG_ 2612134104 PARSEDPushFcGWM_ECGtoACM 1;
BA_ "GenSigSendType" SG_ 2612146392 PARSEDPushFcGWM_ECGtoRACM 3;
BA_ "ECGUsedTxSignal" SG_ 2612146392 PARSEDPushFcGWM_ECGtoRACM 1;
BA_ "GenSigSendType" SG_ 2612215000 PARSEDPushFcGWM_ECGtoESPM 3;
BA_ "ECGUsedTxSignal" SG_ 2612215000 PARSEDPushFcGWM_ECGtoESPM 1;
BA_ "GenSigSendType" SG_ 2612224006 PARSEDPushHUDtoGWM_ECG 3;
BA_ "ECGUsedRxSignal" SG_ 2612224006 PARSEDPushHUDtoGWM_ECG 1;
BA_ "GenSigSendType" SG_ 2612224009 PARSEDPushDSPtoGWM_ECG 3;
BA_ "ECGUsedRxSignal" SG_ 2612224009 PARSEDPushDSPtoGWM_ECG 1;
BA_ "GenSigSendType" SG_ 2612224036 PARSEDPushTRM_ITRMtoGWM_ECG 3;
BA_ "ECGUsedRxSignal" SG_ 2612224036 PARSEDPushTRM_ITRMtoGWM_ECG 1;
BA_ "GenSigSendType" SG_ 2612224051 PARSEDPushMRCMB_RDAPMtoGWM_ECG 3;
BA_ "ECGUsedRxSignal" SG_ 2612224051 PARSEDPushMRCMB_RDAPMtoGWM_ECG 1;
BA_ "GenSigSendType" SG_ 2612224064 PARSEDPushWCMtoGWM_ECG 3;
BA_ "ECGUsedRxSignal" SG_ 2612224064 PARSEDPushWCMtoGWM_ECG 1;
BA_ "GenSigSendType" SG_ 2612224084 PARSEDPushWCMCtoGWM_ECG 3;
BA_ "ECGUsedRxSignal" SG_ 2612224084 PARSEDPushWCMCtoGWM_ECG 1;
BA_ "GenSigSendType" SG_ 2612224096 PARSEDPushIPCtoGWM_ECG 3;
BA_ "ECGUsedRxSignal" SG_ 2612224096 PARSEDPushIPCtoGWM_ECG 1;
BA_ "GenSigSendType" SG_ 2612224112 PARSEDPushWCMBtoGWM_ECG 3;
BA_ "ECGUsedRxSignal" SG_ 2612224112 PARSEDPushWCMBtoGWM_ECG 1;
BA_ "GenSigSendType" SG_ 2612224128 PARSEDPushACMtoGWM_ECG 3;
BA_ "ECGUsedRxSignal" SG_ 2612224128 PARSEDPushACMtoGWM_ECG 1;
BA_ "GenSigSendType" SG_ 2612224140 PARSEDPushRACMtoGWM_ECG 3;
BA_ "ECGUsedRxSignal" SG_ 2612224140 PARSEDPushRACMtoGWM_ECG 1;
BA_ "GenSigSendType" SG_ 2612224207 PARSEDPushESPMoGWM_ECG 3;
BA_ "GenSigSendType" SG_ 2613060824 SymKeyPhysGWM_ECGtoDSP 3;
BA_ "ECGUsedTxSignal" SG_ 2613060824 SymKeyPhysGWM_ECGtoDSP 1;
BA_ "GenSigSendType" SG_ 2613103832 SymKeyPhysGWM_ECGtoMRCMB_RDAPM 3;
BA_ "ECGUsedTxSignal" SG_ 2613103832 SymKeyPhysGWM_ECGtoMRCMB_RDAPM 1;
BA_ "GenSigSendType" SG_ 2613182680 SymKeyPhysGWM_ECGtoACM 3;
BA_ "ECGUsedTxSignal" SG_ 2613182680 SymKeyPhysGWM_ECGtoACM 1;
BA_ "GenSigSendType" SG_ 2613194968 SymKeyPhysGWM_ECGtoRACM 3;
BA_ "ECGUsedTxSignal" SG_ 2613194968 SymKeyPhysGWM_ECGtoRACM 1;
BA_ "GenSigSendType" SG_ 2613263576 SymKeyPhysGWM_ECGtoESPM 3;
BA_ "ECGUsedTxSignal" SG_ 2613263576 SymKeyPhysGWM_ECGtoESPM 1;
BA_ "GenSigSendType" SG_ 2613272585 SymKeyPhysDSPtoGWM_ECG 3;
BA_ "ECGUsedRxSignal" SG_ 2613272585 SymKeyPhysDSPtoGWM_ECG 1;
BA_ "GenSigSendType" SG_ 2613272627 SymKeyPhysMRCMB_RDAPMtoGWM_ECG 3;
BA_ "ECGUsedRxSignal" SG_ 2613272627 SymKeyPhysMRCMB_RDAPMtoGWM_ECG 1;
BA_ "GenSigSendType" SG_ 2613272704 SymKeyPhysACMtoGWM_ECG 3;
BA_ "ECGUsedRxSignal" SG_ 2613272704 SymKeyPhysACMtoGWM_ECG 1;
BA_ "GenSigSendType" SG_ 2613272716 SymKeyPhysRACMtoGWM_ECG 3;
BA_ "ECGUsedRxSignal" SG_ 2613272716 SymKeyPhysRACMtoGWM_ECG 1;
BA_ "GenSigSendType" SG_ 2613272783 SymKeyPhysESPMtoGWM_ECG 3;
BA_ "ECGUsedRxSignal" SG_ 2613272783 SymKeyPhysESPMtoGWM_ECG 1;
BA_ "GenSigSendType" SG_ 2614099160 SymKeyFuncGWM_ECG 3;
BA_ "ECGUsedTxSignal" SG_ 2614099160 SymKeyFuncGWM_ECG 1;
VAL_ 1152 StopStrtVThres_D_Stat 0 "NoSelection" 1 "Low" 2 "Medium" 3 "High" ;
VAL_ 1152 BattTracDiagClr_B_Stat 0 "Off" 1 "On" ;
VAL_ 1152 OnePdlDrv_D_Dsply 0 "Off" 1 "On" 2 "Suspended" 3 "Faulty" ;
VAL_ 1152 EngTeHi_B_Actl 0 "Normal" 1 "EngineTempHigh" ;
VAL_ 1152 DcdcOn_B_Rq 0 "Off" 1 "On" ;
VAL_ 1152 ULoBattSpprtSustn_B_Rq 0 "Inactive" 1 "Active" ;
VAL_ 1152 GrdAsstActv_B_Stat 0 "Off" 1 "On" ;
VAL_ 1152 VehElEff_No_Avg 126 "NoDataExists" 127 "Faulty" ;
VAL_ 1152 PwOutlet8EnblScnd_B_Rq 0 "Disable" 1 "Enable" ;
VAL_ 1152 PwOutlet8Enbl_B_Rq 0 "Disable" 1 "Enable" ;
VAL_ 1152 PwOutlet7EnblScnd_B_Rq 0 "Disable" 1 "Enable" ;
VAL_ 1152 PwOutlet7Enbl_B_Rq 0 "Disable" 1 "Enable" ;
VAL_ 1152 PwOutlet6EnblScnd_B_Rq 0 "Disable" 1 "Enable" ;
VAL_ 1152 PwOutlet6Enbl_B_Rq 0 "Disable" 1 "Enable" ;
VAL_ 1152 HybPwULoLamp_B_Rq 0 "Off" 1 "On" ;
VAL_ 1152 OnePdlDrvLamp_B_Rq 0 "Off" 1 "On" ;
VAL_ 1152 DcacPwSustn_B_RqPt 0 "No" 1 "Yes" ;
VAL_ 1152 OnePdlDrvButtn_D_Dsply 0 "Off" 1 "On" 2 "Off_And_GreyedOut" 3 "On_And_GreyedOut" ;
VAL_ 1152 DcdcOnScnd_B_Rq 0 "Off" 1 "On" ;
VAL_ 1152 PwCabinEnblScnd_B_Rq 0 "Disable" 1 "Enable" ;
VAL_ 1152 PwCabinEnbl_B_Rq 0 "Disable" 1 "Enable" ;
VAL_ 1152 PwTrnkFrntEnblScnd_B_Rq 0 "Disable" 1 "Enable" ;
VAL_ 1152 PwTrnkFrntEnbl_B_Rq 0 "Disable" 1 "Enable" ;
VAL_ 1152 DcacLoFuelLim_L_PwRsrv 510 "No data exists" 511 "Fault" ;
VAL_ 1153 TerrMde_D_RqDrv 0 "Special_Operating_Mode_Off" 1 "Low_Mu_Mode" 2 "Undefined" 3 "Sand_Mode" 4 "Mud_Ruts_Mode" 5 "Rock_Crawl_Mode" 6 "Dynamic_Mode" 7 "Fail_Safe_Default" ;
VAL_ 1153 TerrStat_D_RqDsply 0 "No_Message" 1 "Special_Modes_Off" 2 "Low_Mu_Mode_Select" 3 "Mud_Ruts_Mode_Select" 4 "Sand_Mode_Select" 5 "Rock_Crawl_Mode_Select" 6 "Dynamics_Mode_Select" 7 "Mode_Change_InProgress" 8 "Terrain_System_Fault" 9 "Terrain_Sys_Not_Avail" 10 "ModeChangeNotAvailable" 11 "Economy_Mode_Select" 12 "Crawl_Mode_4LOW_Reqd" 13 "Reserved2" 14 "Reserved3" 15 "Reserved4" ;
VAL_ 1155 WshrLvlFrontTop_B_Stat 0 "FALSE" 1 "TRUE" ;
VAL_ 1155 WshrLvlFront_B_Falt 0 "No" 1 "Yes" ;
VAL_ 1155 WshrFrontActv_B_Stat 0 "Off" 1 "On" ;
VAL_ 1155 WiprFrontWarn2_B_Rq 0 "Off" 1 "On" ;
VAL_ 1155 CoolFanOdmc_D_Rq 0 "Off" 1 "Low" 2 "Medium" 3 "High" ;
VAL_ 1155 ClnCtlLoPw_B_Stat 0 "Fail" 1 "Success" ;
VAL_ 1155 WiprFrontWarn_B_Rq 0 "Off" 1 "On" ;
VAL_ 1155 WshrLvlFrontBttm_B_Stat 0 "FALSE" 1 "TRUE" ;
VAL_ 1155 WshrLvlRearTop_B_Stat 0 "FALSE" 1 "TRUE" ;
VAL_ 1155 WshrLvlRearBttm_B_Stat 0 "FALSE" 1 "TRUE" ;
VAL_ 1155 WshrLvlRear_B_Falt 0 "No" 1 "Yes" ;
VAL_ 1156 PwFlwFuelClimt_B_Dsply 0 "Off" 1 "On" ;
VAL_ 1156 PwFlwFuelBatt_B_Dsply 0 "Off" 1 "On" ;
VAL_ 1156 PwFlwBattGen_D_Dsply 0 "Off" 1 "On" ;
VAL_ 1156 PwFlwBattClimt_B_Dsply 0 "Off" 1 "On" ;
VAL_ 1156 PwFlwBatt_D_Dsply 0 "NoFlow" 1 "FlwFromBattToRearWhls" 2 "FlwFromRearWhlsToBatt" 3 "FlwFromBattToFrontWhls" 4 "FlwFromFrontWhlsToBatt" 5 "FlwFromBattToAllWhls" 6 "FlwFromAllWhlsToBatt" 7 "FlwFromWallToBatt" 8 "NotUsed_1" 9 "NotUsed_2" 10 "NotUsed_3" 11 "NotUsed_4" 12 "NotUsed_5" 13 "NotUsed_6" 14 "NotUsed_7" 15 "NotUsed_8" ;
VAL_ 1156 HtrnLoPw_B_Stat 0 "Fail" 1 "Success" ;
VAL_ 1156 PwFlwFuelDrv_D_Dsply 0 "NoFlow" 1 "FlwFromFuelToRearWhls" 2 "FlwFromFuelToFrontWhls" 3 "FlwFromFuelToAllWhls" 4 "NotUsed_1" 5 "NotUsed_2" 6 "NotUsed_3" 7 "NotUsed_4" ;
VAL_ 1156 VehElEffAvg_No_Dsply 126 "NoDataExists" 127 "Faulty" ;
VAL_ 1156 RngPerChrgAvg_L2_Dsply 8190 "NoDataExists" 8191 "Faulty" ;
VAL_ 1157 SodAltLeft_D2_StatAft 0 "Standby" 1 "ActiveNoDetection" 2 "ActiveDetection" 3 "Faulty" ;
VAL_ 1158 SodAltRight_D2_StatAft 0 "Standby" 1 "ActiveNoDetection" 2 "ActiveDetection" 3 "Faulty" ;
VAL_ 1159 WBCM_Search_CAN 0 "Inactive" 1 "Active" ;
VAL_ 1159 SecondRowBuckleMid2 0 "EmptyBelted" 1 "NotDetermined" 2 "BatteryLow" 3 "OccupiedUnbelted" 4 "EmptyUnbelted" 5 "SeatAbsent" 6 "OccupiedBelted" 7 "Faulty" ;
VAL_ 1159 SecondRowBuckleDriver2 0 "EmptyBelted" 1 "NotDetermined" 2 "BatteryLow" 3 "OccupiedUnbelted" 4 "EmptyUnbelted" 5 "SeatAbsent" 6 "OccupiedBelted" 7 "Faulty" ;
VAL_ 1159 ThirdRowBuckleDriver2 0 "EmptyBelted" 1 "NotDetermined" 2 "BatteryLow" 3 "OccupiedUnbelted" 4 "EmptyUnbelted" 5 "SeatAbsent" 6 "OccupiedBelted" 7 "Faulty" ;
VAL_ 1159 SecondRowBucklePsngr2 0 "EmptyBelted" 1 "NotDetermined" 2 "BatteryLow" 3 "OccupiedUnbelted" 4 "EmptyUnbelted" 5 "SeatAbsent" 6 "OccupiedBelted" 7 "Faulty" ;
VAL_ 1159 ThirdRowBucklePsngr2 0 "EmptyBelted" 1 "NotDetermined" 2 "BatteryLow" 3 "OccupiedUnbelted" 4 "EmptyUnbelted" 5 "SeatAbsent" 6 "OccupiedBelted" 7 "Faulty" ;
VAL_ 1159 ThirdRowBuckleMid2 0 "EmptyBelted" 1 "NotDetermined" 2 "BatteryLow" 3 "OccupiedUnbelted" 4 "EmptyUnbelted" 5 "SeatAbsent" 6 "OccupiedBelted" 7 "Faulty" ;
VAL_ 1159 FourthRowBuckleMid2 0 "EmptyBelted" 1 "NotDetermined" 2 "BatteryLow" 3 "OccupiedUnbelted" 4 "EmptyUnbelted" 5 "SeatAbsent" 6 "OccupiedBelted" 7 "Faulty" ;
VAL_ 1159 FourthRowBuckleDriver2 0 "EmptyBelted" 1 "NotDetermined" 2 "BatteryLow" 3 "OccupiedUnbelted" 4 "EmptyUnbelted" 5 "SeatAbsent" 6 "OccupiedBelted" 7 "Faulty" ;
VAL_ 1159 FourthRowBucklePsngr2 0 "EmptyBelted" 1 "NotDetermined" 2 "BatteryLow" 3 "OccupiedUnbelted" 4 "EmptyUnbelted" 5 "SeatAbsent" 6 "OccupiedBelted" 7 "Faulty" ;
VAL_ 1161 BattTracCellCnt_No_Actl 254 "NoDataExists" 255 "Faulty" ;
VAL_ 1161 BattTracCellUMn_No_Actl 254 "NoDataExists" 255 "Faulty" ;
VAL_ 1161 BattTracTeCnt_No_Actl 254 "NoDataExists" 255 "Faulty" ;
VAL_ 1161 BattTracTeMn_No_Actl 254 "NoDataExists" 255 "Faulty" ;
VAL_ 1161 BattTracTeMx_No_Actl 254 "NoDataExists" 255 "Faulty" ;
VAL_ 1161 BattTracTeMx_B_Falt 0 "No" 1 "Yes" ;
VAL_ 1161 BattTracTeDelta_B_Falt 0 "No" 1 "Yes" ;
VAL_ 1161 BattTracSoftware_B_Falt 0 "No" 1 "Yes" ;
VAL_ 1161 BattTracCellDiff_B_Falt 0 "No" 1 "Yes" ;
VAL_ 1161 BattChrgSocMx_B_Falt 0 "No" 1 "Yes" ;
VAL_ 1161 BattChrgSocMn_B_Falt 0 "No" 1 "Yes" ;
VAL_ 1161 BattChrgSocErrtc_B_Falt 0 "No" 1 "Yes" ;
VAL_ 1161 BattChrgIsltn_B_Falt 0 "No" 1 "Yes" ;
VAL_ 1161 BattTracUMxArry_No_Actl 31 "Faulty" ;
VAL_ 1161 BattChrgUMx_B_Falt 0 "No" 1 "Yes" ;
VAL_ 1161 BattTracUMx_B_Falt 0 "No" 1 "Yes" ;
VAL_ 1161 BattTracUMn_B_Falt 0 "No" 1 "Yes" ;
VAL_ 1161 BattTracCellUMx_No_Actl 254 "NoDataExists" 255 "Faulty" ;
VAL_ 1163 DrLatchFlMsgTxt_D_Rq 0 "NoMessage" 1 "Message1" 2 "Message2" 3 "Message3" 4 "Message4" 5 "Message5" 6 "Message6" 7 "Message7" ;
VAL_ 1163 DrLatchFl_B_Falt 0 "No" 1 "Yes" ;
VAL_ 1163 DrHndlExtFlPull_B_Stat 0 "AtRest" 1 "Pulled" ;
VAL_ 1163 DrOpenPrvntFl_D_Stat 0 "Off" 1 "On" 2 "Overruled" 3 "NotUsed" ;
VAL_ 1163 DrHandleInnrFl_B_Stat 0 "AtRest" 1 "Pulled" ;
VAL_ 1163 DrLatchLckFl_B_Stat 0 "Unlock" 1 "Locked" ;
VAL_ 1163 DrDrv_D_Stat 0 "Unknown" 1 "Closed" 2 "Ajar" 3 "Faulty" ;
VAL_ 1164 DrLatchFrMsgTxt_D_Rq 0 "NoMessage" 1 "Message1" 2 "Message2" 3 "Message3" 4 "Message4" 5 "Message5" 6 "Message6" 7 "Message7" ;
VAL_ 1164 DrLatchFr_B_Falt 0 "No" 1 "Yes" ;
VAL_ 1164 DrOpenPrvntFr_D_Stat 0 "Off" 1 "On" 2 "Overruled" 3 "NotUsed" ;
VAL_ 1164 DrHandleInnrFr_B_Stat 0 "AtRest" 1 "Pulled" ;
VAL_ 1164 DrLatchLckFr_B_Stat 0 "Unlock" 1 "Locked" ;
VAL_ 1164 DrHndlExtFrPull_B_Stat 0 "AtRest" 1 "Pulled" ;
VAL_ 1164 DrPsngr_D_Stat 0 "Unknown" 1 "Closed" 2 "Ajar" 3 "Faulty" ;
VAL_ 1166 DrHndlExtRrPull_B_Stat 0 "AtRest" 1 "Pulled" ;
VAL_ 1186 RearDiffLck_Tq_Actl 4094 "Unknown" 4095 "Fault" ;
VAL_ 1186 FrontDiffFalt_D_Stat 0 "No_Fault" 1 "Fault_Non_Specific" 2 "Diff_Failed_Open" 3 "Diff_Failed_Closed" ;
VAL_ 1186 RearDiffLckLamp_D_Rq 0 "Off" 1 "On" 2 "Flash" 3 "Not_Used" ;
VAL_ 1186 FrontDiffLckLamp_D_Rq 0 "Off" 1 "On" 2 "Flash" 3 "Triggered" ;
VAL_ 1186 RearDiffLckMsg_D_Rq 0 "Normal_No_Message_" 1 "Speed1" 2 "Spee2" 3 "Speed3" 4 "Speed4" 5 "Locker_Accel_Pedal" 6 "Locker_Enabled" 7 "Locker_Disabled" ;
VAL_ 1186 LsdSrvcRqd_B_Rq 0 "Off" 1 "On" ;
VAL_ 1186 RearDiffFalt_D_Stat 0 "No_Fault" 1 "Fault_Non_Specific" 2 "Diff_Failed_Open" 3 "Diff_Failed_Closed" ;
VAL_ 1186 FrontDiffLckMsg_D_Rq 0 "NormalNoMessage" 1 "Speed1" 2 "Speed2" 3 "Speed3" 4 "Speed4" 5 "LockerAccelPedal" 6 "LockerEnabled" 7 "LockerDisabled" ;
VAL_ 1186 SelDrvMdeAwd2_D_Stat 0 "NormalMode" 1 "Normal_2H" 2 "Normal_4A" 3 "Normal_4L" 4 "SportMode" 5 "TowHaulMode" 6 "GrassGravelSnow" 7 "EconomyMode" 8 "SandMode" 9 "MudRutsMode" 10 "RockCrawlMode" 11 "SportAdaptiveMode" 12 "HighSpeedDesertMode_Baja" 13 "NotAvailable" 14 "RoughRoadMode" 15 "TrackMode" 16 "EvNowMode" 17 "EvLaterChargeMode" 18 "DragMode" 19 "OnePedalDrive" 20 "CustomMode" 21 "NotUsed_8" 22 "NotUsed_9" 23 "NotUsed_10" 24 "NotUsed_11" 25 "NotUsed_12" 26 "NotUsed_13" 27 "NotUsed_14" 28 "NotUsed_15" 29 "NotUsed_16" 30 "NotUsed_17" 31 "Faulty" ;
VAL_ 1186 AwdDrvMde_D2_Stat 0 "Normal" 1 "Sport" 2 "Weather" 3 "MudAndSand" 4 "Baja" 5 "RockCrawl" 6 "TowHaul" 7 "NotAvailable" 8 "NotUsed_1" 9 "NotUsed_2" 10 "NotUsed_3" 11 "NotUsed_4" 12 "NotUsed_5" 13 "NotUsed_6" 14 "NotUsed_7" 15 "Faulty" ;
VAL_ 1186 FrontDiffLck_Tq_Actl 16382 "NoDataExists" 16383 "Faulty" ;
VAL_ 1186 AwdStat2_D_RqDsply 0 "Normal" 1 "ChangeTCaseOil" 2 "TCaseOilChanged" 3 "HillHoldFail" 4 "UnavailableDriveMode" 5 "Unavailable4x4Mode_" 6 "NotUsed_1" 7 "NotUsed_2" 8 "NotUsed_3" 9 "NotUsed_4" 10 "NotUsed_5" 11 "NotUsed_6" 12 "NotUsed_7" 13 "NotUsed_8" 14 "NotUsed_9" 15 "NotUsed_10" 16 "NotUsed_11" 17 "NotUsed_12" 18 "NotUsed_13" 19 "NotUsed_14" 20 "NotUsed_15" 21 "NotUsed_16" 22 "NotUsed_17" 23 "NotUsed_18" 24 "NotUsed_19" 25 "NotUsed_20" 26 "NotUsed_21" 27 "NotUsed_22" 28 "NotUsed_23" 29 "NotUsed_24" 30 "NotUsed_25" 31 "NotUsed_26" ;
VAL_ 1189 PwRnngBoardSwtch_B_St 0 "Inactive" 1 "Active" ;
VAL_ 1189 SeatDfaltPosFront_B_Stat 0 "No" 1 "Yes" ;
VAL_ 1189 PwStep_D_Stat 0 "Off" 1 "StepsStowed" 2 "StepsNotStowed" 3 "PositionNotKnown" ;
VAL_ 1189 PwStepMsgTxt_D_Rq 0 "NoMessage" 1 "DriveInhibited" 2 "Malfunction" 3 "NotUsed" ;
VAL_ 1189 Running_Board_Stat 0 "All_Disabled" 1 "All_Enabled" 2 "Manually_Deployed" 3 "Unused" ;
VAL_ 1189 PwRnngBoardPsngr_D_St 0 "Unknown" 1 "Stowed" 2 "Deployed" 3 "Stowing" 4 "Deploying" 5 "Paused" 6 "Reversing" 7 "NotUsed_1" ;
VAL_ 1189 PwRnngBoardDrv_D_St 0 "Unknown" 1 "Stowed" 2 "Deployed" 3 "Stowing" 4 "Deploying" 5 "Paused" 6 "Reversing" 7 "NotUsed_1" ;
VAL_ 1200 YawStabilityIndex 510 "NoDataExists" 511 "Fault" ;
VAL_ 1200 BrkBstrVac_P_Actl 127 "Invalid" ;
VAL_ 1200 HsaTrnAout_Tq_Rq 65534 "Unknown" 65535 "Fault" ;
VAL_ 1200 BrkHold_D_Stat 0 "Off" 1 "Inactive" 2 "Held" 3 "HeldSecure" 4 "HeldSecondary" 5 "NotUsed_1" 6 "NotUsed_2" 7 "NotUsed_3" ;
VAL_ 1200 BrkRearPCorrltn_B_Stat 0 "No" 1 "Yes" ;
VAL_ 1200 BrkTot_Tq_RqDrv 8191 "Fault" ;
VAL_ 1200 HsaStat_D_Dsply 0 "Inactive" 1 "Active" 2 "SlowReleaseWithoutChime" 3 "SlowReleaseWithChime" 4 "NotAvailable" 5 "NotUsed1" 6 "NotUsed2" 7 "NotUsed3" ;
VAL_ 1204 DcacZone3Pw_B_Stat 0 "Off" 1 "On" ;
VAL_ 1204 DcacZone2Pw_B_Stat 0 "Off" 1 "On" ;
VAL_ 1204 DcacEngOnMsgTxt_D2_Rq 0 "Ok" 1 "DisplayWarning" 2 "DisplayQuestion" 3 "AeisManualOverrideWarning" 4 "AeisDoorAjarWarning" 5 "AeisFinalMinutesWarning" 6 "NotUsed_1" 7 "NotUsed_2" 8 "NotUsed_3" 9 "NotUsed_4" 10 "NotUsed_5" 11 "NotUsed_6" 12 "NotUsed_7" 13 "NotUsed_8" 14 "NotUsed_9" 15 "NotUsed_10" ;
VAL_ 1204 DcacElPwScnd_D_Stat 0 "Off" 1 "Low" 2 "High" 3 "NotUsed" ;
VAL_ 1204 DcacOutScnd_Pw_DsplyMx 1023 "Faulty" ;
VAL_ 1204 DcacOutScnd_Pw2_Dsply 8190 "NoDataExists" 8191 "Faulty" ;
VAL_ 1204 EngIdlShutDwnT_B_Dsply 0 "Off" 1 "On" ;
VAL_ 1205 CstmDrvMdeCfg2_B_Avail 0 "NotAvailable" 1 "Available" ;
VAL_ 1205 CstmDrvMdeCfg1_B_Avail 0 "NotAvailable" 1 "Available" ;
VAL_ 1208 StopStrtImccSel_B_Falt 0 "No" 1 "Yes" ;
VAL_ 1208 Btt_L2_Actl2 126 "NoDataExists" 127 "Faulty" ;
VAL_ 1208 WiprFrontActv_D_Rq 0 "Null" 1 "Off" 2 "AutoRainSensing" 3 "LowSpeed" 4 "HighSpeed" 5 "NotUsed_1" 6 "NoDataExists" 7 "Faulty" ;
VAL_ 1208 WshrFrontActv_B_Rq 0 "Off" 1 "On" ;
VAL_ 1208 StopStrtImccSel_B_Rq 0 "Off" 1 "On" ;
VAL_ 1208 StopStrtImccTxt_D_Stat 0 "NotActive" 1 "ActiveOnDsply" 2 "ClosedNo" 3 "ClosedYes" 4 "ClosedTimeout" 5 "NotUsed_1" 6 "NotUsed_2" 7 "NotUsed_3" ;
VAL_ 1208 TjaAutoLcEnbl_D_RqMnu 0 "Null" 1 "Off" 2 "On" 3 "NotUsed" ;
VAL_ 1208 IpwEnbl_D_RqMnu 0 "Null" 1 "Off" 2 "On" 3 "NotUsed" ;
VAL_ 1208 EngStrtChimeSet_D_Rq 0 "Inactive" 1 "Off" 2 "On" 3 "NotUsed" ;
VAL_ 1211 E_Voice_Blower_Limit 0 "NoRequest" 1 "Request" ;
VAL_ 1211 E_Frt_Blwr_Speed 0 "No_Request" 1 "Min_Blower" 2 "Max_Blower" 3 "NotUsed" ;
VAL_ 1211 E_Drv_Set_Temp 0 "No_Request" 1 "LO" 2 "15_5" 3 "16_0" 4 "16_5" 5 "17_0" 6 "17_5" 7 "18_0" 8 "18_5" 9 "19_0" 10 "19_5" 11 "20_0" 12 "20_5" 13 "21_0" 14 "21_5" 15 "22_0" 16 "22_5" 17 "23_0" 18 "23_5" 19 "24_0" 20 "24_5" 21 "25_0" 22 "25_5" 23 "26_0" 24 "26_5" 25 "27_0" 26 "27_5" 27 "28_0" 28 "28_5" 29 "29_0" 30 "29_5" 31 "HI" ;
VAL_ 1211 FrtBlwr_An_Actl 511 "Faulty" ;
VAL_ 1211 E_Frt_Btn_Status_1st 0 "None_Pressed" 1 "Panel_Pressed" 2 "Panel_Floor_Pressed" 3 "Floor_Pressed" 4 "Floor_Ws_Pressed" 5 "AC_Pressed" 6 "Dual_Pressed" 7 "LHS_Temp_Inc_Pressed" 8 "LHS_Temp_Dec_Pressed" 9 "RHS_Temp_Inc_Pressed" 10 "RHS_Temp_Dec_Pressed" 11 "Blwr_Inc_Pressed" 12 "Blwr_Dec_Pressed" 13 "Auto_Pressed" 14 "Max_AC_Pressed" 15 "Recirc_Pressed" 16 "Outside_Pressed" 17 "Auto_Recirc_Pressed" 18 "Htd_Frt_Wsh_Pressed" 19 "Windscreen_Pressed" 20 "Pnl_Ws_Pressed" 21 "Pnl_Flr_Ws_Pressed" 22 "Rear_Defrost_Pressed" 23 "Front_Power_Pressed" 24 "My_Temp_Pressed" 25 "Max_Defrost_Pressed" 26 "LHS_Htd_Seat_Pressed" 27 "RHS_Htd_Seat_Pressed" 28 "LHS_Cld_Seat_Pressed" 29 "RHS_Cld_Seat_Pressed" 30 "Htg_Strg_Whl_Pressed" 31 "Defrost_Pressed" 32 "FrontMnu_Pressed" 33 "RearMnu_Pressed" 34 "Heat_Pressed" 35 "AAR_Pressed" 36 "MdeMnu_Pressed" 37 "DrvrFcsdMde_Pressed" 38 "LHS_Seat_Off_Pressed" 39 "LHS_Htd_Seat1_Pressed" 40 "LHS_Htd_Seat2_Pressed" 41 "LHS_Htd_Seat3_Pressed" 42 "LHS_Auto_Seat_Pressed" 43 "RHS_Seat_Off_Pressed" 44 "RHS_Htd_Seat1_Pressed" 45 "RHS_Htd_Seat2_Pressed" 46 "RHS_Htd_Seat3_Pressed" 47 "RHS_Auto_Seat_Pressed" 48 "LHS_Cld_Seat1_Pressed" 49 "LHS_Cld_Seat2_Pressed" 50 "LHS_Cld_Seat3_Pressed" 51 "RHS_Cld_Seat1_Pressed" 52 "RHS_Cld_Seat2_Pressed" 53 "RHS_Cld_Seat3_Pressed" 54 "AUTO_Lo_Pressed" 55 "AUTO_Med_Pressed" 56 "AUTO_Hi_Pressed" 57 "AUTO_Inc_Pressed" 58 "AUTO_Dec_Pressed" 59 "NotUsed_1" 60 "NotUsed_2" 61 "NotUsed_3" 62 "NotUsed_4" 63 "NotUsed_5" ;
VAL_ 1211 FrtTe_An_Actl 511 "Faulty" ;
VAL_ 1211 E_Frt_Btn_Status_2nd 0 "None_Pressed" 1 "Panel_Pressed" 2 "Panel_Floor_Pressed" 3 "Floor_Pressed" 4 "Floor_Ws_Pressed" 5 "AC_Pressed" 6 "Dual_Pressed" 7 "LHS_Temp_Inc_Pressed" 8 "LHS_Temp_Dec_Pressed" 9 "RHS_Temp_Inc_Pressed" 10 "RHS_Temp_Dec_Pressed" 11 "Blwr_Inc_Pressed" 12 "Blwr_Dec_Pressed" 13 "Auto_Pressed" 14 "Max_AC_Pressed" 15 "Recirc_Pressed" 16 "Outside_Pressed" 17 "Auto_Recirc_Pressed" 18 "Htd_Frt_Wsh_Pressed" 19 "Windscreen_Pressed" 20 "Pnl_Ws_Pressed" 21 "Pnl_Flr_Ws_Pressed" 22 "Rear_Defrost_Pressed" 23 "Front_Power_Pressed" 24 "My_Temp_Pressed" 25 "Max_Defrost_Pressed" 26 "LHS_Htd_Seat_Pressed" 27 "RHS_Htd_Seat_Pressed" 28 "LHS_Cld_Seat_Pressed" 29 "RHS_Cld_Seat_Pressed" 30 "Htg_Strg_Whl_Pressed" 31 "Defrost_Pressed" 32 "FrontMnu_Pressed" 33 "RearMnu_Pressed" 34 "Heat_Pressed" 35 "AAR_Pressed" 36 "MdeMnu_Pressed" 37 "DrvrFcsdMde_Pressed" 38 "LHS_Seat_Off_Pressed" 39 "LHS_Htd_Seat1_Pressed" 40 "LHS_Htd_Seat2_Pressed" 41 "LHS_Htd_Seat3_Pressed" 42 "LHS_Auto_Seat_Pressed" 43 "RHS_Seat_Off_Pressed" 44 "RHS_Htd_Seat1_Pressed" 45 "RHS_Htd_Seat2_Pressed" 46 "RHS_Htd_Seat3_Pressed" 47 "RHS_Auto_Seat_Pressed" 48 "LHS_Cld_Seat1_Pressed" 49 "LHS_Cld_Seat2_Pressed" 50 "LHS_Cld_Seat3_Pressed" 51 "RHS_Cld_Seat1_Pressed" 52 "RHS_Cld_Seat2_Pressed" 53 "RHS_Cld_Seat3_Pressed" 54 "AUTO_Lo_Pressed" 55 "AUTO_Med_Pressed" 56 "AUTO_Hi_Pressed" 57 "AUTO_Inc_Pressed" 58 "AUTO_Dec_Pressed" 59 "NotUsed_1" 60 "NotUsed_2" 61 "NotUsed_3" 62 "NotUsed_4" 63 "NotUsed_5" ;
VAL_ 1211 E_Rr_Btn_Status_1st 0 "None_Pressed" 1 "Panel_Pressed" 2 "Panel_Floor_Pressed" 3 "Floor_Pressed" 4 "LHS_Temp_Inc_Pressed" 5 "LHS_Temp_Dec_Pressed" 6 "RHS_Temp_Inc_Pressed" 7 "RHS_Temp_Dec_Pressed" 8 "Blwr_Inc_Pressed" 9 "Blwr_Dec_Pressed" 10 "AUTO_Pressed" 11 "Rear_Power_Pressed" 12 "LHS_Htd_Seat_Pressed" 13 "RHS_Htd_Seat_Pressed" 14 "LHS_Cld_Seat_Pressed" 15 "RHS_Cld_Seat_Pressed" 16 "Rear_Lock_Pressed" 17 "Third_Blwr_Inc_Pressed" 18 "Third_Blwr_Dec_Pressed" 19 "Third_Panel_Pressed" 20 "Third_Floor_Pressed" 21 "Third_Pnl_Flr_Pressed" 22 "Third_Auto_Pressed" 23 "Third_Rr_Pwr_Pressed" 24 "Third_Synch_Pressed" 25 "NotUsed9" 26 "NotUsed10" 27 "NotUsed11" 28 "NotUsed12" 29 "NotUsed13" 30 "NotUsed14" 31 "NotUsed15" ;
VAL_ 1211 E_Rr_Btn_Status_2nd 0 "None_Pressed" 1 "Panel_Pressed" 2 "Panel_Floor_Pressed" 3 "Floor_Pressed" 4 "LHS_Temp_Inc_Pressed" 5 "LHS_Temp_Dec_Pressed" 6 "RHS_Temp_Inc_Pressed" 7 "RHS_Temp_Dec_Pressed" 8 "Blwr_Inc_Pressed" 9 "Blwr_Dec_Pressed" 10 "AUTO_Pressed" 11 "Rear_Power_Pressed" 12 "LHS_Htd_Seat_Pressed" 13 "RHS_Htd_Seat_Pressed" 14 "LHS_Cld_Seat_Pressed" 15 "RHS_Cld_Seat_Pressed" 16 "Rear_Lock_Pressed" 17 "Third_Blwr_Inc_Pressed" 18 "Third_Blwr_Dec_Pressed" 19 "Third_Panel_Pressed" 20 "Third_Floor_Pressed" 21 "Third_Pnl_Flr_Pressed" 22 "Third_Auto_Pressed" 23 "Third_Rr_Pwr_Pressed" 24 "Third_Synch_Pressed" 25 "NotUsed9" 26 "NotUsed10" 27 "NotUsed11" 28 "NotUsed12" 29 "NotUsed13" 30 "NotUsed14" 31 "NotUsed15" ;
VAL_ 1212 PersDgtlKey1_D_Stat 0 "Inactive" 1 "Index_1" 2 "Index_2" 3 "Index_3" 4 "Index_4" 5 "Index_5" 6 "Index_6" 7 "Index_7" 8 "Index_8" 9 "Index_9" 10 "Index_10" 11 "Index_11" 12 "Index_12" 13 "Index_13" 14 "Index_14" 15 "Index_15" 16 "Index_16" 17 "Index_17" 18 "Index_18" 19 "Index_19" 20 "Index_20" 21 "Index_21" 22 "Index_22" 23 "Index_23" 24 "Index_24" 25 "Index_25" 26 "Index_26" 27 "Index_27" 28 "Index_28" 29 "Index_29" 30 "Index_30" 31 "Index_31" 32 "Index_32" 33 "Index_33" 34 "Index_34" 35 "Index_35" 36 "Index_36" 37 "Index_37" 38 "Index_38" 39 "Index_39" 40 "Index_40" 41 "Index_41" 42 "Index_42" 43 "Index_43" 44 "Index_44" 45 "Index_45" 46 "Index_46" 47 "Index_47" 48 "Index_48" 49 "Index_49" 50 "Index_50" 51 "Index_51" 52 "Index_52" 53 "Index_53" 54 "Index_54" 55 "Index_55" 56 "Index_56" 57 "Index_57" 58 "Index_58" 59 "Index_59" 60 "Index_60" 61 "Index_61" 62 "Index_62" 63 "Index_63" 64 "Index_64" 65 "Index_65" 66 "Index_66" 67 "Index_67" 68 "Index_68" 69 "Index_69" 70 "Index_70" 71 "Index_71" 72 "Index_72" 73 "Index_73" 74 "Index_74" 75 "Index_75" 76 "Index_76" 77 "Index_77" 78 "Index_78" 79 "Index_79" 80 "Index_80" 81 "Index_81" 82 "Index_82" 83 "Index_83" 84 "Index_84" 85 "Index_85" 86 "Index_86" 87 "Index_87" 88 "Index_88" 89 "Index_89" 90 "Index_90" 91 "Index_91" 92 "Index_92" 93 "Index_93" 94 "Index_94" 95 "Index_95" 96 "Index_96" 97 "Index_97" 98 "Index_98" 99 "Index_99" 100 "Index_100" 101 "Index_101" 102 "Index_102" 103 "Index_103" 104 "Index_104" 105 "Index_105" 106 "Index_106" 107 "Index_107" 108 "Index_108" 109 "Index_109" 110 "Index_110" 111 "Index_111" 112 "Index_112" 113 "Index_113" 114 "Index_114" 115 "Index_115" 116 "Index_116" 117 "Index_117" 118 "Index_118" 119 "Index_119" 120 "Index_120" 121 "Index_121" 122 "Index_122" 123 "Index_123" 124 "Index_124" 125 "Index_125" 126 "Index_126" 127 "Index_127" 128 "Index_128" 129 "Index_129" 130 "Index_130" 131 "Index_131" 132 "Index_132" 133 "Index_133" 134 "Index_134" 135 "Index_135" 136 "Index_136" 137 "Index_137" 138 "Index_138" 139 "Index_139" 140 "Index_140" 141 "Index_141" 142 "Index_142" 143 "Index_143" 144 "Index_144" 145 "Index_145" 146 "Index_146" 147 "Index_147" 148 "Index_148" 149 "Index_149" 150 "Index_150" 151 "Index_151" 152 "Index_152" 153 "Index_153" 154 "Index_154" 155 "Index_155" 156 "Index_156" 157 "Index_157" 158 "Index_158" 159 "Index_159" 160 "Index_160" 161 "Index_161" 162 "Index_162" 163 "Index_163" 164 "Index_164" 165 "Index_165" 166 "Index_166" 167 "Index_167" 168 "Index_168" 169 "Index_169" 170 "Index_170" 171 "Index_171" 172 "Index_172" 173 "Index_173" 174 "Index_174" 175 "Index_175" 176 "Index_176" 177 "Index_177" 178 "Index_178" 179 "Index_179" 180 "Index_180" 181 "Index_181" 182 "Index_182" 183 "Index_183" 184 "Index_184" 185 "Index_185" 186 "Index_186" 187 "Index_187" 188 "Index_188" 189 "Index_189" 190 "Index_190" 191 "Index_191" 192 "Index_192" 193 "Index_193" 194 "Index_194" 195 "Index_195" 196 "Index_196" 197 "Index_197" 198 "Index_198" 199 "Index_199" 200 "Index_200" 201 "Index_201" 202 "Index_202" 203 "Index_203" 204 "Index_204" 205 "Index_205" 206 "Index_206" 207 "Index_207" 208 "Index_208" 209 "Index_209" 210 "Index_210" 211 "Index_211" 212 "Index_212" 213 "Index_213" 214 "Index_214" 215 "Index_215" 216 "Index_216" 217 "Index_217" 218 "Index_218" 219 "Index_219" 220 "Index_220" 221 "Index_221" 222 "Index_222" 223 "Index_223" 224 "Index_224" 225 "Index_225" 226 "Index_226" 227 "Index_227" 228 "Index_228" 229 "Index_229" 230 "Index_230" 231 "Index_231" 232 "Index_232" 233 "Index_233" 234 "Index_234" 235 "Index_235" 236 "Index_236" 237 "Index_237" 238 "Index_238" 239 "Index_239" 240 "Index_240" 241 "Index_241" 242 "Index_242" 243 "Index_243" 244 "Index_244" 245 "Index_245" 246 "Index_246" 247 "Index_247" 248 "Index_248" 249 "Index_249" 250 "Index_250" 251 "Index_251" 252 "Index_252" 253 "Index_253" 254 "Index_254" 255 "Index_255" ;
VAL_ 1212 PersDgtlKey2_D_Stat 0 "Inactive" 1 "Index_1" 2 "Index_2" 3 "Index_3" 4 "Index_4" 5 "Index_5" 6 "Index_6" 7 "Index_7" 8 "Index_8" 9 "Index_9" 10 "Index_10" 11 "Index_11" 12 "Index_12" 13 "Index_13" 14 "Index_14" 15 "Index_15" 16 "Index_16" 17 "Index_17" 18 "Index_18" 19 "Index_19" 20 "Index_20" 21 "Index_21" 22 "Index_22" 23 "Index_23" 24 "Index_24" 25 "Index_25" 26 "Index_26" 27 "Index_27" 28 "Index_28" 29 "Index_29" 30 "Index_30" 31 "Index_31" 32 "Index_32" 33 "Index_33" 34 "Index_34" 35 "Index_35" 36 "Index_36" 37 "Index_37" 38 "Index_38" 39 "Index_39" 40 "Index_40" 41 "Index_41" 42 "Index_42" 43 "Index_43" 44 "Index_44" 45 "Index_45" 46 "Index_46" 47 "Index_47" 48 "Index_48" 49 "Index_49" 50 "Index_50" 51 "Index_51" 52 "Index_52" 53 "Index_53" 54 "Index_54" 55 "Index_55" 56 "Index_56" 57 "Index_57" 58 "Index_58" 59 "Index_59" 60 "Index_60" 61 "Index_61" 62 "Index_62" 63 "Index_63" 64 "Index_64" 65 "Index_65" 66 "Index_66" 67 "Index_67" 68 "Index_68" 69 "Index_69" 70 "Index_70" 71 "Index_71" 72 "Index_72" 73 "Index_73" 74 "Index_74" 75 "Index_75" 76 "Index_76" 77 "Index_77" 78 "Index_78" 79 "Index_79" 80 "Index_80" 81 "Index_81" 82 "Index_82" 83 "Index_83" 84 "Index_84" 85 "Index_85" 86 "Index_86" 87 "Index_87" 88 "Index_88" 89 "Index_89" 90 "Index_90" 91 "Index_91" 92 "Index_92" 93 "Index_93" 94 "Index_94" 95 "Index_95" 96 "Index_96" 97 "Index_97" 98 "Index_98" 99 "Index_99" 100 "Index_100" 101 "Index_101" 102 "Index_102" 103 "Index_103" 104 "Index_104" 105 "Index_105" 106 "Index_106" 107 "Index_107" 108 "Index_108" 109 "Index_109" 110 "Index_110" 111 "Index_111" 112 "Index_112" 113 "Index_113" 114 "Index_114" 115 "Index_115" 116 "Index_116" 117 "Index_117" 118 "Index_118" 119 "Index_119" 120 "Index_120" 121 "Index_121" 122 "Index_122" 123 "Index_123" 124 "Index_124" 125 "Index_125" 126 "Index_126" 127 "Index_127" 128 "Index_128" 129 "Index_129" 130 "Index_130" 131 "Index_131" 132 "Index_132" 133 "Index_133" 134 "Index_134" 135 "Index_135" 136 "Index_136" 137 "Index_137" 138 "Index_138" 139 "Index_139" 140 "Index_140" 141 "Index_141" 142 "Index_142" 143 "Index_143" 144 "Index_144" 145 "Index_145" 146 "Index_146" 147 "Index_147" 148 "Index_148" 149 "Index_149" 150 "Index_150" 151 "Index_151" 152 "Index_152" 153 "Index_153" 154 "Index_154" 155 "Index_155" 156 "Index_156" 157 "Index_157" 158 "Index_158" 159 "Index_159" 160 "Index_160" 161 "Index_161" 162 "Index_162" 163 "Index_163" 164 "Index_164" 165 "Index_165" 166 "Index_166" 167 "Index_167" 168 "Index_168" 169 "Index_169" 170 "Index_170" 171 "Index_171" 172 "Index_172" 173 "Index_173" 174 "Index_174" 175 "Index_175" 176 "Index_176" 177 "Index_177" 178 "Index_178" 179 "Index_179" 180 "Index_180" 181 "Index_181" 182 "Index_182" 183 "Index_183" 184 "Index_184" 185 "Index_185" 186 "Index_186" 187 "Index_187" 188 "Index_188" 189 "Index_189" 190 "Index_190" 191 "Index_191" 192 "Index_192" 193 "Index_193" 194 "Index_194" 195 "Index_195" 196 "Index_196" 197 "Index_197" 198 "Index_198" 199 "Index_199" 200 "Index_200" 201 "Index_201" 202 "Index_202" 203 "Index_203" 204 "Index_204" 205 "Index_205" 206 "Index_206" 207 "Index_207" 208 "Index_208" 209 "Index_209" 210 "Index_210" 211 "Index_211" 212 "Index_212" 213 "Index_213" 214 "Index_214" 215 "Index_215" 216 "Index_216" 217 "Index_217" 218 "Index_218" 219 "Index_219" 220 "Index_220" 221 "Index_221" 222 "Index_222" 223 "Index_223" 224 "Index_224" 225 "Index_225" 226 "Index_226" 227 "Index_227" 228 "Index_228" 229 "Index_229" 230 "Index_230" 231 "Index_231" 232 "Index_232" 233 "Index_233" 234 "Index_234" 235 "Index_235" 236 "Index_236" 237 "Index_237" 238 "Index_238" 239 "Index_239" 240 "Index_240" 241 "Index_241" 242 "Index_242" 243 "Index_243" 244 "Index_244" 245 "Index_245" 246 "Index_246" 247 "Index_247" 248 "Index_248" 249 "Index_249" 250 "Index_250" 251 "Index_251" 252 "Index_252" 253 "Index_253" 254 "Index_254" 255 "Index_255" ;
VAL_ 1212 PersDgtlKey3_D_Stat 0 "Inactive" 1 "Index_1" 2 "Index_2" 3 "Index_3" 4 "Index_4" 5 "Index_5" 6 "Index_6" 7 "Index_7" 8 "Index_8" 9 "Index_9" 10 "Index_10" 11 "Index_11" 12 "Index_12" 13 "Index_13" 14 "Index_14" 15 "Index_15" 16 "Index_16" 17 "Index_17" 18 "Index_18" 19 "Index_19" 20 "Index_20" 21 "Index_21" 22 "Index_22" 23 "Index_23" 24 "Index_24" 25 "Index_25" 26 "Index_26" 27 "Index_27" 28 "Index_28" 29 "Index_29" 30 "Index_30" 31 "Index_31" 32 "Index_32" 33 "Index_33" 34 "Index_34" 35 "Index_35" 36 "Index_36" 37 "Index_37" 38 "Index_38" 39 "Index_39" 40 "Index_40" 41 "Index_41" 42 "Index_42" 43 "Index_43" 44 "Index_44" 45 "Index_45" 46 "Index_46" 47 "Index_47" 48 "Index_48" 49 "Index_49" 50 "Index_50" 51 "Index_51" 52 "Index_52" 53 "Index_53" 54 "Index_54" 55 "Index_55" 56 "Index_56" 57 "Index_57" 58 "Index_58" 59 "Index_59" 60 "Index_60" 61 "Index_61" 62 "Index_62" 63 "Index_63" 64 "Index_64" 65 "Index_65" 66 "Index_66" 67 "Index_67" 68 "Index_68" 69 "Index_69" 70 "Index_70" 71 "Index_71" 72 "Index_72" 73 "Index_73" 74 "Index_74" 75 "Index_75" 76 "Index_76" 77 "Index_77" 78 "Index_78" 79 "Index_79" 80 "Index_80" 81 "Index_81" 82 "Index_82" 83 "Index_83" 84 "Index_84" 85 "Index_85" 86 "Index_86" 87 "Index_87" 88 "Index_88" 89 "Index_89" 90 "Index_90" 91 "Index_91" 92 "Index_92" 93 "Index_93" 94 "Index_94" 95 "Index_95" 96 "Index_96" 97 "Index_97" 98 "Index_98" 99 "Index_99" 100 "Index_100" 101 "Index_101" 102 "Index_102" 103 "Index_103" 104 "Index_104" 105 "Index_105" 106 "Index_106" 107 "Index_107" 108 "Index_108" 109 "Index_109" 110 "Index_110" 111 "Index_111" 112 "Index_112" 113 "Index_113" 114 "Index_114" 115 "Index_115" 116 "Index_116" 117 "Index_117" 118 "Index_118" 119 "Index_119" 120 "Index_120" 121 "Index_121" 122 "Index_122" 123 "Index_123" 124 "Index_124" 125 "Index_125" 126 "Index_126" 127 "Index_127" 128 "Index_128" 129 "Index_129" 130 "Index_130" 131 "Index_131" 132 "Index_132" 133 "Index_133" 134 "Index_134" 135 "Index_135" 136 "Index_136" 137 "Index_137" 138 "Index_138" 139 "Index_139" 140 "Index_140" 141 "Index_141" 142 "Index_142" 143 "Index_143" 144 "Index_144" 145 "Index_145" 146 "Index_146" 147 "Index_147" 148 "Index_148" 149 "Index_149" 150 "Index_150" 151 "Index_151" 152 "Index_152" 153 "Index_153" 154 "Index_154" 155 "Index_155" 156 "Index_156" 157 "Index_157" 158 "Index_158" 159 "Index_159" 160 "Index_160" 161 "Index_161" 162 "Index_162" 163 "Index_163" 164 "Index_164" 165 "Index_165" 166 "Index_166" 167 "Index_167" 168 "Index_168" 169 "Index_169" 170 "Index_170" 171 "Index_171" 172 "Index_172" 173 "Index_173" 174 "Index_174" 175 "Index_175" 176 "Index_176" 177 "Index_177" 178 "Index_178" 179 "Index_179" 180 "Index_180" 181 "Index_181" 182 "Index_182" 183 "Index_183" 184 "Index_184" 185 "Index_185" 186 "Index_186" 187 "Index_187" 188 "Index_188" 189 "Index_189" 190 "Index_190" 191 "Index_191" 192 "Index_192" 193 "Index_193" 194 "Index_194" 195 "Index_195" 196 "Index_196" 197 "Index_197" 198 "Index_198" 199 "Index_199" 200 "Index_200" 201 "Index_201" 202 "Index_202" 203 "Index_203" 204 "Index_204" 205 "Index_205" 206 "Index_206" 207 "Index_207" 208 "Index_208" 209 "Index_209" 210 "Index_210" 211 "Index_211" 212 "Index_212" 213 "Index_213" 214 "Index_214" 215 "Index_215" 216 "Index_216" 217 "Index_217" 218 "Index_218" 219 "Index_219" 220 "Index_220" 221 "Index_221" 222 "Index_222" 223 "Index_223" 224 "Index_224" 225 "Index_225" 226 "Index_226" 227 "Index_227" 228 "Index_228" 229 "Index_229" 230 "Index_230" 231 "Index_231" 232 "Index_232" 233 "Index_233" 234 "Index_234" 235 "Index_235" 236 "Index_236" 237 "Index_237" 238 "Index_238" 239 "Index_239" 240 "Index_240" 241 "Index_241" 242 "Index_242" 243 "Index_243" 244 "Index_244" 245 "Index_245" 246 "Index_246" 247 "Index_247" 248 "Index_248" 249 "Index_249" 250 "Index_250" 251 "Index_251" 252 "Index_252" 253 "Index_253" 254 "Index_254" 255 "Index_255" ;
VAL_ 1212 PersDgtlKey4_D_Stat 0 "Inactive" 1 "Index_1" 2 "Index_2" 3 "Index_3" 4 "Index_4" 5 "Index_5" 6 "Index_6" 7 "Index_7" 8 "Index_8" 9 "Index_9" 10 "Index_10" 11 "Index_11" 12 "Index_12" 13 "Index_13" 14 "Index_14" 15 "Index_15" 16 "Index_16" 17 "Index_17" 18 "Index_18" 19 "Index_19" 20 "Index_20" 21 "Index_21" 22 "Index_22" 23 "Index_23" 24 "Index_24" 25 "Index_25" 26 "Index_26" 27 "Index_27" 28 "Index_28" 29 "Index_29" 30 "Index_30" 31 "Index_31" 32 "Index_32" 33 "Index_33" 34 "Index_34" 35 "Index_35" 36 "Index_36" 37 "Index_37" 38 "Index_38" 39 "Index_39" 40 "Index_40" 41 "Index_41" 42 "Index_42" 43 "Index_43" 44 "Index_44" 45 "Index_45" 46 "Index_46" 47 "Index_47" 48 "Index_48" 49 "Index_49" 50 "Index_50" 51 "Index_51" 52 "Index_52" 53 "Index_53" 54 "Index_54" 55 "Index_55" 56 "Index_56" 57 "Index_57" 58 "Index_58" 59 "Index_59" 60 "Index_60" 61 "Index_61" 62 "Index_62" 63 "Index_63" 64 "Index_64" 65 "Index_65" 66 "Index_66" 67 "Index_67" 68 "Index_68" 69 "Index_69" 70 "Index_70" 71 "Index_71" 72 "Index_72" 73 "Index_73" 74 "Index_74" 75 "Index_75" 76 "Index_76" 77 "Index_77" 78 "Index_78" 79 "Index_79" 80 "Index_80" 81 "Index_81" 82 "Index_82" 83 "Index_83" 84 "Index_84" 85 "Index_85" 86 "Index_86" 87 "Index_87" 88 "Index_88" 89 "Index_89" 90 "Index_90" 91 "Index_91" 92 "Index_92" 93 "Index_93" 94 "Index_94" 95 "Index_95" 96 "Index_96" 97 "Index_97" 98 "Index_98" 99 "Index_99" 100 "Index_100" 101 "Index_101" 102 "Index_102" 103 "Index_103" 104 "Index_104" 105 "Index_105" 106 "Index_106" 107 "Index_107" 108 "Index_108" 109 "Index_109" 110 "Index_110" 111 "Index_111" 112 "Index_112" 113 "Index_113" 114 "Index_114" 115 "Index_115" 116 "Index_116" 117 "Index_117" 118 "Index_118" 119 "Index_119" 120 "Index_120" 121 "Index_121" 122 "Index_122" 123 "Index_123" 124 "Index_124" 125 "Index_125" 126 "Index_126" 127 "Index_127" 128 "Index_128" 129 "Index_129" 130 "Index_130" 131 "Index_131" 132 "Index_132" 133 "Index_133" 134 "Index_134" 135 "Index_135" 136 "Index_136" 137 "Index_137" 138 "Index_138" 139 "Index_139" 140 "Index_140" 141 "Index_141" 142 "Index_142" 143 "Index_143" 144 "Index_144" 145 "Index_145" 146 "Index_146" 147 "Index_147" 148 "Index_148" 149 "Index_149" 150 "Index_150" 151 "Index_151" 152 "Index_152" 153 "Index_153" 154 "Index_154" 155 "Index_155" 156 "Index_156" 157 "Index_157" 158 "Index_158" 159 "Index_159" 160 "Index_160" 161 "Index_161" 162 "Index_162" 163 "Index_163" 164 "Index_164" 165 "Index_165" 166 "Index_166" 167 "Index_167" 168 "Index_168" 169 "Index_169" 170 "Index_170" 171 "Index_171" 172 "Index_172" 173 "Index_173" 174 "Index_174" 175 "Index_175" 176 "Index_176" 177 "Index_177" 178 "Index_178" 179 "Index_179" 180 "Index_180" 181 "Index_181" 182 "Index_182" 183 "Index_183" 184 "Index_184" 185 "Index_185" 186 "Index_186" 187 "Index_187" 188 "Index_188" 189 "Index_189" 190 "Index_190" 191 "Index_191" 192 "Index_192" 193 "Index_193" 194 "Index_194" 195 "Index_195" 196 "Index_196" 197 "Index_197" 198 "Index_198" 199 "Index_199" 200 "Index_200" 201 "Index_201" 202 "Index_202" 203 "Index_203" 204 "Index_204" 205 "Index_205" 206 "Index_206" 207 "Index_207" 208 "Index_208" 209 "Index_209" 210 "Index_210" 211 "Index_211" 212 "Index_212" 213 "Index_213" 214 "Index_214" 215 "Index_215" 216 "Index_216" 217 "Index_217" 218 "Index_218" 219 "Index_219" 220 "Index_220" 221 "Index_221" 222 "Index_222" 223 "Index_223" 224 "Index_224" 225 "Index_225" 226 "Index_226" 227 "Index_227" 228 "Index_228" 229 "Index_229" 230 "Index_230" 231 "Index_231" 232 "Index_232" 233 "Index_233" 234 "Index_234" 235 "Index_235" 236 "Index_236" 237 "Index_237" 238 "Index_238" 239 "Index_239" 240 "Index_240" 241 "Index_241" 242 "Index_242" 243 "Index_243" 244 "Index_244" 245 "Index_245" 246 "Index_246" 247 "Index_247" 248 "Index_248" 249 "Index_249" 250 "Index_250" 251 "Index_251" 252 "Index_252" 253 "Index_253" 254 "Index_254" 255 "Index_255" ;
VAL_ 1212 BonAur_D_Stat 0 "Null" 1 "Bonjour" 2 "Motive" 3 "Au_Revoir" 4 "NotUsed_1" 5 "NotUsed_2" 6 "NotUsed_3" 7 "NotUsed_4" ;
VAL_ 1212 LostPKChirp_D_Stat 0 "Null" 1 "Disabled" 2 "Enabled" 3 "NotConfigured" ;
VAL_ 1212 PersPrfl_D_Stat 0 "Null" 1 "PERS_1" 2 "PERS_2" 3 "PERS_3" 4 "PERS_4" 5 "Unused_1" 6 "Unused_2" 7 "Unused_3" ;
VAL_ 1212 DelvrAsstFeat_D_Stat 0 "Inactive" 1 "Enabled_Inactive" 2 "Pause_Active" 3 "Resume_Active" 4 "Pause_PT_Inactive" 5 "NotUsed_1" 6 "NotUsed_2" 7 "Faulty" ;
VAL_ 1212 BonAurMde_D_Stat 0 "Null" 1 "Prepareentrancelighting" 2 "Entrancelighting" 3 "Entrancelightingdelay" 4 "Pedalpress" 5 "Prepareexitlighting" 6 "Exitlighting" 7 "Exitlightingdelay" 8 "NotUsed_1" 9 "NotUsed_2" 10 "NotUsed_3" 11 "NotUsed_4" 12 "NotUsed_5" 13 "NotUsed_6" 14 "NotUsed_7" 15 "NotUsed_8" ;
VAL_ 1212 KeyFobEvnt_D_Stat 0 "KeyfobEventInactive" 1 "KeyfobEventActive" 2 "NotUsed_1" 3 "NotUsed_2" ;
VAL_ 1212 DelvrAsstExtndWak_D_Rq 0 "Null" 1 "Inactive" 2 "Active" 3 "NotUsed" ;
VAL_ 1216 DrHandleInnrRl_B_Stat 0 "AtRest" 1 "Pulled" ;
VAL_ 1216 SldrlStat_B_Actl 0 "Closed" 1 "Ajar" ;
VAL_ 1216 SldrlUnlckSwtch_D_Stat 0 "Null" 1 "IpSwitch" 2 "RearInteriorSwitch" 3 "InnerHandle" ;
VAL_ 1216 Sldrl_D_Stat 0 "NotMoving" 1 "Opening" 2 "Closing" 3 "NotCalibrated" ;
VAL_ 1216 PwStepLeft_D_Rq 0 "Null" 1 "Deploy" 2 "Stow" 3 "NotUsed" ;
VAL_ 1216 UnlckSrcRl_D_Stat 0 "Null" 1 "IpSwitch" 2 "RearInteriorSwitch" 3 "InnerHandle" ;
VAL_ 1216 SldrlMsgTxt_D2_Rq 0 "Null" 1 "SlidingDrClutchReleased" 2 "SlidingDrCalibNeeded" 3 "SlidingDrOpenCltchReleased" 4 "SlidingDrCalibNeeded2" 5 "NotUsed_1" 6 "NotUsed_2" 7 "NotUsed_3" ;
VAL_ 1216 SldrlChime_D_Rq 0 "Off" 1 "Operation" 2 "Programming" 3 "WarningRepeated" 4 "Warning" 5 "NotUsed1" 6 "NotUsed2" 7 "NotUsed3" ;
VAL_ 1216 DrLatchLckRl_B_Stat 0 "Unlock" 1 "Locked" ;
VAL_ 1216 DrLatchRlMsgTxt_D_Rq 0 "NoMessage" 1 "Message1" 2 "Message2" 3 "Message3" 4 "Message4" 5 "Message5" 6 "Message6" 7 "Message7" ;
VAL_ 1216 DrOpenPrvntRl_D_Stat 0 "Off" 1 "On" 2 "Overruled" 3 "NotUsed" ;
VAL_ 1216 DrHndlExtRlPull_B_Stat 0 "AtRest" 1 "Pulled" ;
VAL_ 1216 DrLatchRl_B_Falt 0 "No" 1 "Yes" ;
VAL_ 1217 DrHandleInnrRr_B_Stat 0 "AtRest" 1 "Pulled" ;
VAL_ 1217 SldrrStat_B_Actl 0 "Closed" 1 "Ajar" ;
VAL_ 1217 SldrrUnlckSwtch_D_Stat 0 "Null" 1 "IpSwitch" 2 "RearInteriorSwitch" 3 "InnerHandle" ;
VAL_ 1217 Sldrr_D_Stat 0 "NotMoving" 1 "Opening" 2 "Closing" 3 "NotCalibrated" ;
VAL_ 1217 PwStepRight_D_Rq 0 "Null" 1 "Deploy" 2 "Stow" 3 "NotUsed" ;
VAL_ 1217 UnlckSrcRr_D_Stat 0 "Null" 1 "IpSwitch" 2 "RearInteriorSwitch" 3 "InnerHandle" ;
VAL_ 1217 SldrrMsgTxt_D2_Rq 0 "Null" 1 "SlidingDrClutchReleased" 2 "SlidingDrCalibNeeded" 3 "SlidingDrOpenCltchReleased" 4 "SlidingDrCalibNeeded2" 5 "NotUsed_1" 6 "NotUsed_2" 7 "NotUsed_3" ;
VAL_ 1217 SldrrChime_D_Rq 0 "Off" 1 "Operation" 2 "Programming" 3 "WarningRepeated" 4 "Warning" 5 "NotUsed1" 6 "NotUsed2" 7 "NotUsed3" ;
VAL_ 1217 DrLatchLckRr_B_Stat 0 "Unlock" 1 "Locked" ;
VAL_ 1217 DrOpenPrvntRr_D_Stat 0 "Off" 1 "On" 2 "Overruled" 3 "NotUsed" ;
VAL_ 1217 DrLatchRrMsgTxt_D_Rq 0 "NoMessage" 1 "Message1" 2 "Message2" 3 "Message3" 4 "Message4" 5 "Message5" 6 "Message6" 7 "Message7" ;
VAL_ 1217 DrLatchRr_B_Falt 0 "No" 1 "Yes" ;
VAL_ 1218 BecSwtchExtLck_D_Stat 0 "Null" 1 "Locked" 2 "Unlocked" 3 "NoDeviceOrDoor" ;
VAL_ 1218 BecSwtch2ExtLck_D_Stat 0 "Null" 1 "Locked" 2 "Unlocked" 3 "NoDeviceOrDoor" ;
VAL_ 1218 DrPsngrRearLck_D_Stat 0 "Null" 1 "Locked" 2 "Unlocked" 3 "NoDeviceOrDoor" ;
VAL_ 1218 DrDrvRearLck_D_Stat 0 "Null" 1 "Locked" 2 "Unlocked" 3 "NoDeviceOrDoor" ;
VAL_ 1218 LckUnlckSrvc_D_Arb 0 "Null" 1 "Local" 2 "Soa" 3 "NotUsed_1" ;
VAL_ 1218 FecSwtchExtLck_D_Stat 0 "Null" 1 "Locked" 2 "Unlocked" 3 "NoDeviceOrDoor" ;
VAL_ 1218 DrPsngrLck_D_Stat 0 "Null" 1 "Locked" 2 "Unlocked" 3 "NoDeviceOrDoor" ;
VAL_ 1218 DrDrvLck_D_Stat 0 "Null" 1 "Locked" 2 "Unlocked" 3 "NoDeviceOrDoor" ;
VAL_ 1218 ClsrOprtSrvc_D_Arb 0 "Null" 1 "Local" 2 "Soa" 3 "NotUsed_1" ;
VAL_ 1218 ClsrOprtSrvc_D_Res 0 "Null" 1 "Success" 2 "Pending" 3 "Rejected" 4 "Interrupted" 5 "Failed" 6 "In_Prog" 7 "Invalid" 8 "NotUsed_1" 9 "NotUsed_2" 10 "NotUsed_3" 11 "NotUsed_4" 12 "NotUsed_5" 13 "NotUsed_6" 14 "NotUsed_7" 15 "Faulty" ;
VAL_ 1218 LckUnlckSrvc_D_Res 0 "Null" 1 "Success" 2 "Pending" 3 "Rejected" 4 "Interrupted" 5 "Failed" 6 "In_Prog" 7 "Invalid" 8 "NotUsed_1" 9 "NotUsed_2" 10 "NotUsed_3" 11 "NotUsed_4" 12 "NotUsed_5" 13 "NotUsed_6" 14 "NotUsed_7" 15 "Faulty" ;
VAL_ 1218 LatchFdbck_B_Stat 0 "Real" 1 "Inferred" ;
VAL_ 1218 PsngrAutoPwWndw_D_Rq 0 "Null" 1 "Stop" 2 "Close" 3 "Open" ;
VAL_ 1218 OprtSrc_D_Stat 0 "Null" 1 "RemoteKey" 2 "Handsfree" 3 "NotUsed_1" 4 "NotUsed_2" 5 "NotUsed_3" 6 "NotUsed_4" 7 "NotUsed_5" ;
VAL_ 1218 DrvAutoPwWndw_D_Rq 0 "Null" 1 "Stop" 2 "Close" 3 "Open" ;
VAL_ 1218 VehLck_D_Dsply 0 "Off" 1 "Lock" 2 "Unlock" 3 "Faulty" ;
VAL_ 1218 BodyPersSrvc_D_Res 0 "Null" 1 "Success" 2 "Pending" 3 "Rejected" 4 "Interrupted" 5 "Failed" 6 "InProg" 7 "Invalid" 8 "NotUsed1" 9 "NotUsed2" 10 "NotUsed3" 11 "NotUsed4" 12 "NotUsed5" 13 "NotUsed6" 14 "NotUsed7" 15 "Faulty" ;
VAL_ 1218 BodyPersChng_D_Stat 0 "Null" 1 "ProfileUpdated" 2 "DataLost" 3 "NotUsed1" ;
VAL_ 1223 MrorAutoSavDrv_D_Stat 0 "None" 1 "InProgress" 2 "Major" 3 "Minor" ;
VAL_ 1223 DrvWndwAutoOprt_D_Stat 0 "Null" 1 "NotAvailable" 2 "Available" 3 "Override" ;
VAL_ 1223 ChildLckFdbkRd2_B_Stat 0 "Unlock" 1 "Locked" ;
VAL_ 1224 MrorAutoSavPsngr_D_St 0 "None" 1 "InProgress" 2 "Major" 3 "Minor" ;
VAL_ 1224 PsngWndwAutoOpr_D_Stat 0 "Null" 1 "NotAvailable" 2 "Available" 3 "Override" ;
VAL_ 1224 ChildLckFdbkRp2_B_Stat 0 "Unlock" 1 "Locked" ;
VAL_ 1229 DrOpenPrvntRight_B_Rq 0 "False" 1 "True" ;
VAL_ 1229 DrOpenPrvntLeft_B_Rq 0 "False" 1 "True" ;
VAL_ 1229 ExitNotClrRight_B_Stat 0 "False" 1 "True" ;
VAL_ 1229 ExitNotClrLeft_B_Stat 0 "False" 1 "True" ;
VAL_ 1229 SodChimeEnbl_D_Stat 0 "Null" 1 "Disable" 2 "Enable" 3 "NotUsed" ;
VAL_ 1229 SodChime_D_Rq 0 "Level_0" 1 "Level_1" 2 "Level_2" 3 "Level_3" ;
VAL_ 1229 IsaOnOff_D_Rq 0 "Null" 1 "Off" 2 "On" 3 "Not Used" ;
VAL_ 1229 TrlrIspCnnct_D_Stat 0 "NotConnected" 1 "Connected" 2 "NotUsed_1" 3 "NotUsed_2" ;
VAL_ 1229 SodIndRr_D_Rq 0 "Level_0" 1 "Level_1" 2 "Level_2" 3 "Level_3" ;
VAL_ 1229 SodIndRl_D_Rq 0 "Level_0" 1 "Level_1" 2 "Level_2" 3 "Level_3" ;
VAL_ 1232 ACU_Configuration 0 "Invalid" 1 "LowLevelAudio" 2 "HighLevelAudio" 3 "LowLevelNavigation" 4 "HighLevelNavigation" 5 "HIN_LSRNS" 6 "HIN_HSRNS" ;
VAL_ 1232 ACU_MediaPlayer_St 0 "Invalid" 1 "MusicCassettePlayer" 2 "CdSinglePlayer" 3 "CdChanger" ;
VAL_ 1232 ACU_DigitalRadio_St 0 "Invalid" 1 "WithoutDigitalRadioSystem" 2 "DAB_RadioSystemWithPTY_EU" 3 "DAB_RadioSystemWithPTY_NA" 4 "DAB_RadioSystemWithPTY_GC" 5 "DAB_RadioSystemWithPTY_JA" ;
VAL_ 1232 AHU_AutoConfigOcc_Allst 0 "Not_Supported" 1 "Supported" ;
VAL_ 1232 AHU_AutoConfigOcc_Cnvrt 0 "Not_Supported" 1 "Supported" ;
VAL_ 1232 AHU_AutoConfigOcc_Drvr 0 "Not_Supported" 1 "Supported" ;
VAL_ 1232 AHU_AutoConfigOcc_Front 0 "Not_Supported" 1 "Supported" ;
VAL_ 1232 AHU_AutoConfigOcc_Rear 0 "Not_Supported" 1 "Supported" ;
VAL_ 1232 AHU_AutoConfigOcc_Shakr 0 "Not_Supported" 1 "Supported" ;
VAL_ 1232 AHU_EnsembleName_St 0 "Not_Supported" 1 "Supported" ;
VAL_ 1235 ApaSlotFront_D_Stat 0 "False" 1 "True" ;
VAL_ 1235 ApaSlotLeft1_B_Altr 0 "NotAvailable" 1 "Available" ;
VAL_ 1235 ApaSlotLeft1_D_Stat 0 "None" 1 "IPaFound" 2 "IPaReady" 3 "IPeFound" 4 "IPeReady" 5 "NotUsed_1" 6 "NotUsed_2" 7 "NotUsed_3" ;
VAL_ 1235 ApaSlotLeft3_B_Altr 0 "NotAvailable" 1 "Available" ;
VAL_ 1235 ApaSlotLeft2_B_Altr 0 "NotAvailable" 1 "Available" ;
VAL_ 1235 ApaSlotLeft2_D_Stat 0 "None" 1 "IPaFound" 2 "IPaReady" 3 "IPeFound" 4 "IPeReady" 5 "NotUsed_1" 6 "NotUsed_2" 7 "NotUsed_3" ;
VAL_ 1235 ApaSlotLeft3_D_Stat 0 "None" 1 "IPaFound" 2 "IPaReady" 3 "IPeFound" 4 "IPeReady" 5 "NotUsed_1" 6 "NotUsed_2" 7 "NotUsed_3" ;
VAL_ 1236 ApaSlotRear_D_Stat 0 "False" 1 "True" ;
VAL_ 1236 ApaSlotRight1_B_Altr 0 "NotAvailable" 1 "Available" ;
VAL_ 1236 ApaSlotRight1_D_Stat 0 "None" 1 "IPaFound" 2 "IPaReady" 3 "IPeFound" 4 "IPeReady" 5 "NotUsed_1" 6 "NotUsed_2" 7 "NotUsed_3" ;
VAL_ 1236 ApaSlotRight3_B_Altr 0 "NotAvailable" 1 "Available" ;
VAL_ 1236 ApaSlotRight2_B_Altr 0 "NotAvailable" 1 "Available" ;
VAL_ 1236 ApaSlotRight2_D_Stat 0 "None" 1 "IPaFound" 2 "IPaReady" 3 "IPeFound" 4 "IPeReady" 5 "NotUsed_1" 6 "NotUsed_2" 7 "NotUsed_3" ;
VAL_ 1236 ApaSlotRight3_D_Stat 0 "None" 1 "IPaFound" 2 "IPaReady" 3 "IPeFound" 4 "IPeReady" 5 "NotUsed_1" 6 "NotUsed_2" 7 "NotUsed_3" ;
VAL_ 1237 DasAttentWarn_D_Dsply 0 "No_Warning" 1 "EyesOffWarning_1" 2 "EyesOffWarning_2" 3 "EyesOffWarning_3" 4 "NotUsed_1" 5 "NotUsed_2" 6 "NotUsed_3" 7 "NotUsed_4" ;
VAL_ 1238 TjaLaneBias_D_Stat 0 "NoBias" 1 "ManualBiasLeft" 2 "ManualBiasRight" 3 "SystemBiasLeft" 4 "SystemBiasRight" 5 "ElBiasLeft" 6 "ElBiasRight" 7 "NotUsed" ;
VAL_ 1238 IaccVAdjReas_D_Dsply 0 "NoDisplay" 1 "RoadGeometryUnavailable" 2 "RightTurnIntersection" 3 "LeftTurnIntersection" 4 "RightCurve" 5 "LeftCurve" 6 "Roundabout_CW" 7 "Roundabout_CCW" 8 "RightRamp" 9 "LeftRamp" 10 "SpeedSign" 11 "NotUsed_1" 15 "NotUsed_21" ;
VAL_ 1238 TjaLcEnbl_D_Stat 0 "Inactive" 1 "Off" 2 "On" 3 "NotUsed" ;
VAL_ 1238 GfhbMnu_D_Rq 0 "Null" 1 "Disable" 2 "EnableGFHB" 3 "EnableADB" ;
VAL_ 1238 AhbcMnu_D_Rq 0 "Null" 1 "Disable" 2 "Enable" 3 "NotUsed" ;
VAL_ 1238 TjaLaneBiasEnbl_D_Stat 0 "Inactive" 1 "Disable" 2 "Enable" 3 "NotUsed" ;
VAL_ 1238 TjaLc_D_Stat 0 "Off" 1 "Standby" 2 "AvailableLeft" 3 "AvailableRight" 4 "AvailableLeftRight" 5 "PreparingLeft" 6 "PreparingRight" 7 "LcActiveLeft" 8 "LcActiveRight" 9 "NotUsed_1" 10 "NotUsed_2" 11 "NotUsed_3" 12 "NotUsed_4" 13 "NotUsed_5" 14 "NotUsed_6" 15 "NotUsed_7" ;
VAL_ 1238 TjaCanclMsgTxt_D_Dsply 0 "NoMessage" 1 "CancelledForRoadCurvature" 2 "CancelledForLaneConditions" 3 "HandsFreeUnavailForMaxSpd" 4 "HandsFreeUnavailInThisArea" 5 "DriverNotSeen1" 6 "DriverNotSeen2" 7 "HTOforRoadCurvWithoutChime" 8 "HTOforLaneCondWithoutChime" 9 "NotUsed_1" 10 "NotUsed_2" 11 "NotUsed_3" 12 "NotUsed_4" 13 "NotUsed_5" 14 "NotUsed_6" 15 "NotUsed_7" ;
VAL_ 1238 FbaAlrt_D_Dsply 0 "Off" 1 "Graphic" 2 "Text" 3 "Both" ;
VAL_ 1238 TjaLcWarn_D_Rq 0 "NoWarning" 1 "DriverCancel" 2 "SystemCancel" 3 "CancelNoLane" 4 "CancelLaneBusy" 5 "CancelSpeedTooLow" 6 "NotUsed_1" 7 "NotUsed_2" ;
VAL_ 1238 TjaLcMsgTxt_D_Rq 0 "NoMessage" 1 "LcSuggestionLeft" 2 "LcSuggestionRight" 3 "AlcOn" 4 "AlcOff" 5 "TurnOffIndicator" 6 "SysLcStartChime" 7 "SysLcCancelChime" ;
VAL_ 1238 OraAutoActv_D_Rq 0 "Null" 1 "Deactivate" 2 "Activate" 3 "NotUsed_1" ;
VAL_ 1238 FbaMsg_D_Rq 0 "Null" 1 "Off" 2 "Unavailable" 3 "Faulty" ;
VAL_ 1238 FbaMnu_D_Rq 0 "None" 1 "Inactive" 2 "Active" 3 "NotUsed" ;
VAL_ 1238 Fba_D_Stat 0 "Off" 1 "On" 2 "Disabled" 3 "NotUsed" ;
VAL_ 1238 MoisNotfn_D_Rq 0 "NO_REQUEST" 1 "INFORMATION_1" 2 "INFORMATION_2" 3 "WARNING_1" 4 "WARNING_2" 5 "FAILURE_WARNING" 6 "NotUsed_1" 7 "NotUsed_2" ;
VAL_ 1238 TjaAutoLcEnbl_D_Stat 0 "Inactive" 1 "Off" 2 "On" 3 "NotUsed" ;
VAL_ 1238 TsrAslButtnPress_D_Rq 0 "Null" 1 "Hold_For_Deactivation" 2 "Hold_For_Activation" 3 "Partial_Deactivation_SLWF" 4 "Partial_Deactivation_SCF" 5 "NotUsed_1" 6 "NotUsed_2" 7 "NotUsed_3" ;
VAL_ 1238 TjaLc_D2_Stat 0 "Off" 1 "Standby" 2 "AvailableLeft" 3 "AvailableRight" 4 "AvailableLeftRight" 5 "PreparingLeft" 6 "PreparingRight" 7 "LcActiveLeft" 8 "LcActiveRight" 9 "SlowVehUpcmLeft" 10 "SlowVehUpcmLeftCnclInf" 11 "SlowVehUpcmRight" 12 "SlowVehUpcmRightCnclInf" 13 "SlowVehPrepLeft" 14 "SlowVehPrepLeftCnclInf" 15 "SlowVehPrepRight" 16 "SlowVehPrepRightCnclInf" 17 "OutOfPassUpcmLeft" 18 "OutOfPassUpcmLeftCnclInf" 19 "OutOfPassUpcmRight" 20 "OutOfPassUpcmRightCnclInf" 21 "OutOfPassPrepLeft" 22 "OutOfPassPrepLeftCnclInf" 23 "OutOfPassPrepRight" 24 "OutOfPassPrepRightCnclInf" 25 "RouteUpcmLeft" 26 "RouteUpcmLeftCnclInf" 27 "RouteUpcmRight" 28 "RouteUpcmRightCnclInf" 29 "RoutePrepLeft" 30 "RoutePrepLeftCnclInf" 31 "RoutePrepRight" 32 "RoutePrepRightCnclInf" 33 "NotUsed_1" 34 "NotUsed_2" 35 "NotUsed_3" 36 "NotUsed_4" 37 "NotUsed_5" 38 "NotUsed_6" 39 "NotUsed_7" 40 "NotUsed_8" 41 "NotUsed_9" 42 "NotUsed_10" 43 "NotUsed_11" 44 "NotUsed_12" 45 "NotUsed_13" 46 "NotUsed_14" 47 "NotUsed_15" 48 "NotUsed_16" 49 "NotUsed_17" 50 "NotUsed_18" 51 "NotUsed_19" 52 "NotUsed_20" 53 "NotUsed_21" 54 "NotUsed_22" 55 "NotUsed_23" 56 "NotUsed_24" 57 "NotUsed_25" 58 "NotUsed_26" 59 "NotUsed_27" 60 "NotUsed_28" 61 "NotUsed_29" 62 "NotUsed_30" 63 "NotUsed_31" ;
VAL_ 1238 MoisChime_B_Rq 0 "Off" 1 "On" ;
VAL_ 1239 CstmDrvMdeTracCtl_D_Rq 0 "Default_Mode" 1 "App_Specific_Off_Mode_1" 2 "App_Specific_Off_Mode_2" 3 "App_Specific_Off_Mode_3" ;
VAL_ 1239 SeatOccRearChime_B_Rq 0 "Off" 1 "On" ;
VAL_ 1239 ActvDrvMdeCstm_D2_Rq 0 "SelDrvMde01" 1 "SelDrvMde02" 2 "SelDrvMde03" 3 "SelDrvMde04" 4 "SelDrvMde05" 5 "SelDrvMde06" 6 "SelDrvMde07" 7 "SelDrvMde08" 8 "SelDrvMde09" 9 "SelDrvMde10" 10 "SelDrvMde11" 11 "SelDrvMde12" 12 "SelDrvMde13" 13 "SelDrvMde14" 14 "SelDrvMde15" 15 "SelDrvMde16" 16 "SelDrvMde17" 17 "SelDrvMde18" 18 "SelDrvMde19" 19 "SelDrvMde20" 20 "SelDrvMde21" 21 "SelDrvMde22" 22 "SelDrvMde23" 23 "SelDrvMde24" 24 "SelDrvMde25" 25 "SelDrvMde26" 26 "SelDrvMde27" 27 "SelDrvMde28" 28 "SelDrvMde29" 29 "SelDrvMde30" 30 "SelDrvMde31" 31 "Faulty" ;
VAL_ 1239 CstmDrvMdeMsgTxt_D_Rq 0 "NoMessage" 1 "Message1" 2 "Message2" 3 "Message3" 4 "Message4" 5 "Message5" 6 "Message6" 7 "Message7" 8 "Message8" 9 "Message9" 10 "Message10" 11 "Message11" 12 "Message12" 13 "Message13" 14 "Message14" 15 "Message15" ;
VAL_ 1239 StabBarCnnctLamp_D_Cstm 0 "Off" 1 "On" 2 "Slow_Flash" 3 "Fast_Flash" ;
VAL_ 1239 SelDrvMdeCstmLamp_D_Rq 0 "Off" 1 "On" 2 "NotUsed1" 3 "NotUsed2" ;
VAL_ 1239 CstmDrvMdePrfl_No_Actl 15 "Faulty" ;
VAL_ 1239 CstmDrvMdeHmi2_D_Rq 0 "SelDrvMde01" 1 "SelDrvMde02" 2 "SelDrvMde03" 3 "SelDrvMde04" 4 "SelDrvMde05" 5 "SelDrvMde06" 6 "SelDrvMde07" 7 "SelDrvMde08" 8 "SelDrvMde09" 9 "SelDrvMde10" 10 "SelDrvMde11" 11 "SelDrvMde12" 12 "SelDrvMde13" 13 "SelDrvMde14" 14 "SelDrvMde15" 15 "SelDrvMde16" 16 "SelDrvMde17" 17 "SelDrvMde18" 18 "SelDrvMde19" 19 "SelDrvMde20" 20 "SelDrvMde21" 21 "SelDrvMde22" 22 "SelDrvMde23" 23 "SelDrvMde24" 24 "SelDrvMde25" 25 "SelDrvMde26" 26 "SelDrvMde27" 27 "SelDrvMde28" 28 "SelDrvMde29" 29 "SelDrvMde30" 30 "SelDrvMde31" 31 "Faulty" ;
VAL_ 1239 CstmDrvMdeChassis_D_Rq 0 "NormalMode" 1 "NormalAdaptiveMode" 2 "EconomyMode" 3 "SportMode" 4 "SportAdaptiveMode" 5 "ComfortMode" 6 "ComfortAdaptiveMode" 7 "LowMuMode" 8 "MudAndRutsMode" 9 "SandMode" 10 "RockCrawlMode" 11 "TowHaulMode" 12 "HighSpeedDesertMode" 13 "TrackMode" 14 "RoughRoadMode" 15 "DragMode" 16 "OnePedalDrive" 17 "NotUsed4" 18 "NotUsed5" 19 "NotUsed6" 20 "NotUsed7" 21 "NotUsed8" 22 "NotUsed9" 23 "NotUsed10" 24 "NotUsed11" 25 "NotUsed12" 26 "NotUsed13" 27 "NotUsed14" 28 "NotUsed15" 29 "NotUsed16" 30 "NotUsed17" 31 "Faulty" ;
VAL_ 1239 SelDrvMdeCstm_D_RqDrv 0 "Null" 1 "Activate" 2 "Save" 3 "Recall" 4 "NotUsed_1" 5 "NotUsed_2" 6 "NotUsed_3" 7 "Faulty" ;
VAL_ 1242 SelDrvMdeCstmPt_D_Rq 0 "NormalMode" 1 "SportMode" 2 "NotAvailable_02" 3 "TowHaulMode" 4 "NotAvailable_04" 5 "GrassGravelSnow" 6 "EconomyMode" 7 "SandMode" 8 "MudRutsMode" 9 "RockCrawlMode" 10 "NotAvailable_10" 11 "NotAvailable_11" 12 "NotAvailable_12" 13 "NotAvailable_13" 14 "SportAdaptiveMode" 15 "HighSpeedDesertMode_Baja" 16 "DragMode" 17 "EvNowMode" 18 "EvLaterChargerMode" 19 "OnePedalDrive" 20 "TrackMode" 21 "CustomMode" 22 "ComfortMode" 23 "NotUsed_1" 24 "NotUsed_2" 25 "NotUsed_3" 26 "NotUsed_4" 27 "NotUsed_5" 28 "NotUsed_6" 29 "NotUsed_7" 30 "NotUsed_8" 31 "Faulty" ;
VAL_ 1242 EngExhMdeQuietCstm_D_Rq 0 "Null" 1 "Stealth" 2 "Normal" 3 "Sport" 4 "Track" 5 "NotUsed_1" 6 "NotUsed_2" 7 "Faulty" ;
VAL_ 1242 StopStrtCstm_D_Rq 0 "NotAvailable" 1 "Off" 2 "On" 3 "Faulty" ;
VAL_ 1243 Con_BTAud_InfotainmVer_St 0 "invalid" 1 "B299" ;
VAL_ 1244 Con_InfotainmentVer_St 0 "invalid" 1 "B299" ;
VAL_ 1245 SelDrvMdeAwd2_D_Cstm 0 "NormalMode" 1 "Normal_2H" 2 "Normal_4A" 3 "Normal_4L" 4 "SportMode" 5 "TowHaulMode" 6 "GrassGravelSnow" 7 "EconomyMode" 8 "SandMode" 9 "MudRutsMode" 10 "RockCrawlMode" 11 "SportAdaptiveMode" 12 "HighSpeedDesertMode_Baja" 13 "NotAvailable" 14 "RoughRoadMode" 15 "TrackMode" 16 "EvNowMode" 17 "EvLaterChargeMode" 18 "DragMode" 19 "OnePedalDrive" 20 "CustomMode" 21 "NotUsed_8" 22 "NotUsed_9" 23 "NotUsed_10" 24 "NotUsed_11" 25 "NotUsed_12" 26 "NotUsed_13" 27 "NotUsed_14" 28 "NotUsed_15" 29 "NotUsed_16" 30 "NotUsed_17" 31 "Faulty" ;
VAL_ 1245 AwdMdeCstm_D_RqDrv 0 "FourByTwo" 1 "FourByFourAuto" 2 "FourByFourHigh" 3 "FourByFourLow" 4 "NotUsed_1" 5 "NotUsed_2" 6 "NotUsed_3" 7 "Faulty" ;
VAL_ 1245 SndPersIndx_D_Rq 0 "Pers_1" 1 "Pers_2" 2 "Pers_3" 3 "Pers_4" 4 "Vehicle" 5 "NotUsed_1" 6 "NotUsed_2" 7 "NotUsed_3" ;
VAL_ 1245 RearDiffLckLamp_D_Cstm 0 "Off" 1 "On" 2 "Flash" 3 "Not_Used" ;
VAL_ 1245 FrontDiffLckLamp_D_Cstm 0 "Off" 1 "On" 2 "Slow_Flash" 3 "Fast_Flash" ;
VAL_ 1245 SndPersSrvc_D_Rq 0 "Null" 1 "Query" 2 "Set" 3 "Upload" 4 "Restore" 5 "Copy" 6 "NotUsed_1" 7 "NotUsed_2" ;
VAL_ 1246 TrlrBrkCtl2_B_Falt 0 "False" 1 "True" ;
VAL_ 1247 TrlrBrkCtl3_B_Falt 0 "False" 1 "True" ;
VAL_ 1247 StopLamp_B_RqTrlrAft 0 "False" 1 "True" ;
VAL_ 1248 BalrLeft1Dsply_B_Stat 0 "No" 1 "Yes" ;
VAL_ 1248 BalrLeft1Fast_B_Stat 0 "No" 1 "Yes" ;
VAL_ 1248 BalrLeft1Threat_D_Stat 0 "No" 1 "Yes" ;
VAL_ 1249 BalrLeft2Dsply_B_Stat 0 "No" 1 "Yes" ;
VAL_ 1249 BalrLeft2Fast_B_Stat 0 "No" 1 "Yes" ;
VAL_ 1249 BalrLeft2Threat_D_Stat 0 "No" 1 "Yes" ;
VAL_ 1250 BalrLeft3Dsply_B_Stat 0 "No" 1 "Yes" ;
VAL_ 1250 BalrLeft3Fast_B_Stat 0 "No" 1 "Yes" ;
VAL_ 1250 BalrLeft3Threat_D_Stat 0 "No" 1 "Yes" ;
VAL_ 1251 BalrLeft4Dsply_B_Stat 0 "No" 1 "Yes" ;
VAL_ 1251 BalrLeft4Fast_B_Stat 0 "No" 1 "Yes" ;
VAL_ 1251 BalrLeft4Threat_D_Stat 0 "No" 1 "Yes" ;
VAL_ 1252 BalrRight1Dsply_B_Stat 0 "No" 1 "Yes" ;
VAL_ 1252 BalrRight1Fast_B_Stat 0 "No" 1 "Yes" ;
VAL_ 1252 BalrRight1Threat_D_Stat 0 "No" 1 "Yes" ;
VAL_ 1253 BalrRight2Dsply_B_Stat 0 "No" 1 "Yes" ;
VAL_ 1253 BalrRight2Fast_B_Stat 0 "No" 1 "Yes" ;
VAL_ 1253 BalrRight2Threat_D_Stat 0 "No" 1 "Yes" ;
VAL_ 1254 BalrRight3Dsply_B_Stat 0 "No" 1 "Yes" ;
VAL_ 1254 BalrRight3Fast_B_Stat 0 "No" 1 "Yes" ;
VAL_ 1254 BalrRight3Threat_D_Stat 0 "No" 1 "Yes" ;
VAL_ 1255 BalrRight4Dsply_B_Stat 0 "No" 1 "Yes" ;
VAL_ 1255 BalrRight4Fast_B_Stat 0 "No" 1 "Yes" ;
VAL_ 1255 BalrRight4Threat_D_Stat 0 "No" 1 "Yes" ;
VAL_ 1258 TrlrCamraCalib_D_Stat 0 "NotCalibrating" 1 "Calibrating" 2 "NotUsed_1" 3 "NotUsed_2" ;
VAL_ 1258 TrlrCamraView_D_Stat 0 "Off" 1 "Trailer360View" 2 "TrailerRearNormalView" 3 "TrailerInteriorView1" 4 "TrailerInteriorView2" 5 "TrailerLeftSideView" 6 "TrailerRightSideView" 7 "NotUsed_1" 8 "NotUsed_2" 9 "NotUsed_3" 10 "NotUsed_4" 11 "NotUsed_5" 12 "NotUsed_6" 13 "NotUsed_7" 14 "NotUsed_8" 15 "NotUsed_9" ;
VAL_ 1258 TrlrCamraMsgTxt_D_Rq 0 "NoMessage" 1 "Message1" 2 "Message2" 3 "Message3" 4 "Message4" 5 "Message5" 6 "Message6" 7 "Message7" 8 "Message8" 9 "Message9" 10 "Message10" 11 "Message11" 12 "Message12" 13 "Message13" 14 "Message14" 15 "Message15" 16 "Message16" 17 "Message17" 18 "Message18" 19 "Message19" 20 "Message20" 21 "Message21" 22 "Message22" 23 "Message23" 24 "Message24" 25 "Message25" 26 "Message26" 27 "Message27" 28 "Message28" 29 "Message29" 30 "Message30" 31 "Message31" 32 "Message32" 33 "Message33" 34 "Message34" 35 "Message35" 36 "Message36" 37 "Message37" 38 "Message38" 39 "Message39" 40 "Message40" 41 "Message41" 42 "Message42" 43 "Message43" 44 "Message44" 45 "Message45" 46 "Message46" 47 "Message47" 48 "Message48" 49 "Message49" 50 "Message50" 51 "Message51" 52 "Message52" 53 "Message53" 54 "Message54" 55 "Message55" 56 "Message56" 57 "Message57" 58 "Message58" 59 "Message59" 60 "Message60" 61 "Message61" 62 "Message62" 63 "Message63" ;
VAL_ 1261 StmsAutoSavDrv_D_Stat 0 "None" 1 "InProgress" 2 "Major" 3 "Minor" ;
VAL_ 1262 RjvntClimt_B_Stat 0 "Off" 1 "On" ;
VAL_ 1262 RjvntSeatOvrrd_D_Stat 0 "Active" 1 "Overridden" 2 "NotUsed_1" 3 "Faulty" ;
VAL_ 1262 RjvntClimtOvrrd_D_Stat 0 "Active" 1 "Overridden" 2 "NotUsed_1" 3 "Faulty" ;
VAL_ 1262 RjvntClimtOvrdTyp_D_St 0 "NoOverrides" 1 "ClimatePowerOff" 2 "BlowerChanges" 3 "AutoSelected" 4 "TemperatureChanges" 5 "ModeChanges" 6 "RecircChanges" 7 "SeatClimateChanges" 8 "EMRegisterChanges" 9 "NotUsed_1" 10 "NotUsed_2" 11 "NotUsed_3" 12 "NotUsed_4" 13 "NotUsed_5" 14 "NotUsed_6" 15 "Faulty" ;
VAL_ 1263 CabnScentTeMsgTxt_D_Rq 0 "NormalTemp" 1 "OverTemp" 2 "UnderTemp" 3 "NotUsed" ;
VAL_ 1263 CabnScentIntns_D_Stat 0 "NotDetermined" 1 "Off" 2 "Very_Low" 3 "Low" 4 "Medium_Low" 5 "Medium" 6 "Medium_High" 7 "High" ;
VAL_ 1263 CabnScentChnl_D_Stat 0 "Off" 1 "Channel_1" 2 "Channel_2" 3 "Channel_3" 4 "Channel_4" 5 "Channel_5" 6 "Channel_6" 7 "Channel_7" ;
VAL_ 1263 CabnScentSplr_D_Stat 0 "NotDetermined" 1 "Supplier_1" 2 "Supplier_2" 3 "Supplier_3" 4 "Supplier_4" 5 "Supplier_5" 6 "Supplier_6" 7 "Supplier_7" 8 "Supplier_8" 9 "Supplier_9" 10 "Supplier_10" 11 "Supplier_11" 12 "Supplier_12" 13 "Supplier_13" 14 "Supplier_14" 15 "Supplier_15" ;
VAL_ 1263 CabnScentMde_D_Stat 0 "AwakeNotScenting" 1 "AwakeScenting" ;
VAL_ 1263 ActvButtnRight_D_Stat 0 "NonePressed" 1 "OnBodyRHS" 2 "OffBodyRHS" 3 "PresetOneRHS" 4 "PresetTwoRHS" 5 "Cycle_8_RHS" 6 "Cycle_C_RHS" 7 "Cycle_O_RHS" 8 "Cycle_RHS" 9 "Cycle_I_RHS" 10 "NotUsed_1" 11 "NotUsed_2" 12 "NotUsed_3" 13 "NotUsed_4" 14 "NotUsed_5" 15 "NotUsed_6" ;
VAL_ 1263 ActvButtnLeft_D_Stat 0 "NonePressed" 1 "OnBodyLHS" 2 "OffBodyLHS" 3 "PresetOneLHS" 4 "PresetTwoLHS" 5 "Cycle_8_LHS" 6 "Cycle_C_LHS" 7 "Cycle_O_LHS" 8 "Cycle_LHS" 9 "Cycle_I_LHS" 10 "NotUsed_1" 11 "NotUsed_2" 12 "NotUsed_3" 13 "NotUsed_4" 14 "NotUsed_5" 15 "NotUsed_6" ;
VAL_ 1266 CabnScentCalbType_No_Rq 0 "GeneralPurpose" 1 "LowIntensityBaseFanSpeed" 2 "MedIntensityBaseFanSpeed" 3 "HighIntensityBaseFanSpeed" 4 "RepeatNoseBlindLowInts" 5 "RepeatNoseBlindMedInts" 6 "RepeatNoseBlindHighInts" 7 "DurOfPauseNoseBlndLowIntns" 8 "DurOfPauseNoseBlndMedIntns" 9 "DurOfPauseNoseBlndHighIntn" 10 "MaxHoursRemainChannel1" 11 "MaxHoursRemainChannel2" 12 "MaxHoursRemainChannel3" 13 "MaxShelfLifeChannel1" 14 "MaxShelfLifeChannel2" 15 "MaxShelfLifeChannel3" 16 "YoungAgeCartrFanMultipl" 17 "MidAgeCartrFanMultipl" 18 "OldAgeCartrFanMultipl" 19 "CoolTempFanSpdsMultiplier" 20 "WarmTempFanSpdsMultiplier" 21 "HotTempFanSpdsMultiplier" 22 "VHotTempFanSpdsMultiplier" 23 "CoolTempEffectLifeRemain" 24 "MldTempEffectLifeRemain" 25 "HotTempEffectLifeRemain" 26 "LowIntnsEffectLifeRemain" 27 "MedIntnsEffectLifeRemain" 28 "HighIntnsEffectLifeRemain" 29 "NotUsed_1" 255 "NotUsed_227" ;
VAL_ 1266 SafePetTempSet_D_Rq 0 "No_Request" 1 "LO" 2 "15_5" 3 "16_0" 4 "16_5" 5 "17_0" 6 "17_5" 7 "18_0" 8 "18_5" 9 "19_0" 10 "19_5" 11 "20_0" 12 "20_5" 13 "21_0" 14 "21_5" 15 "22_0" 16 "22_5" 17 "23_0" 18 "23_5" 19 "24_0" 20 "24_5" 21 "25_0" 22 "25_5" 23 "26_0" 24 "26_5" 25 "27_0" 26 "27_5" 27 "28_0" 28 "28_5" 29 "29_0" 30 "29_5" 31 "HI" ;
SIG_GROUP_ 1223 SG_DrDrv_E2E_P01A 1 : ChildLckFdbkRd2_B_Stat DrChildLckDrv_No_Rq DrDrv_No_Cnt DrDrv_No_Crc DrDrv_UNUSED_1bit_1 DrDrv_UNUSED_8bit_1 DrDrv_UNUSED_8bit_2 DrDrv_UNUSED_8bit_3 DrDrv_UNUSED_8bit_4 DrDrv_UNUSED_8bit_5 DrSwtchExtDrv_No_Rq DrvWndwAutoOprt_D_Stat;
SIG_GROUP_ 1224 SG_DrPsngr_E2E_P01A 1 : ChildLckFdbkRp2_B_Stat DrPsngr_No_Cnt DrPsngr_No_Crc DrPsngr_UNUSED_7bit_1 DrPsngr_UNUSED_8bit_1 DrPsngr_UNUSED_8bit_2 DrPsngr_UNUSED_8bit_3 DrPsngr_UNUSED_8bit_4 DrPsngr_UNUSED_8bit_5 MrorAutoSavPsngr_D_St PsngWndwAutoOpr_D_Stat;
